VERSION ""

NS_ :

BS_:

BU_: HSCU BCM RINE BRUSA DCDC HVAC DECM BCM_HS HCSU ACCM_HS VICM_HS
VAL_TABLE_ NH3_Heater_Status 4 "Fault" 3 "Prewarm" 2 "On" 1 "Warm_Up" 0 "Off" ;
VAL_TABLE_ DebugRequest 16 "ADC Channel 0010'" 15 "ADC Channel 00F'" 14 "ADC Channel 00E'" 13 "ADC Channel 00D'" 12 "ADC Channel 00C'" 11 "ADC Channel 00B'" 10 "ADC Channel 00A'" 9 "ADC Channel 009'" 8 "ADC Channel 008'" 7 "ADC Channel 007'" 6 "ADC Channel 006'" 5 "ADC Channel 005'" 4 "ADC Channel 004'" 3 "ADC Channel 003'" 2 "ADC Channel 002'" 1 "ADC Channel 001'" 0 "ADC Channel 000'" ;
VAL_TABLE_ u13_error_no_value 8191 "ERROR" 8190 "NO_VALUE" ;
VAL_TABLE_ u10_error_no_value 1023 "ERROR" 1022 "NO_VALUE" ;
VAL_TABLE_ mainc_step 12 "MAIN_P_CLOSED_CHARGE" 11 "MAIN_PN_CLOSED_DRIVE" 10 "FAILED_MAINP_OPEN" 9 "OPEN_MAINR" 8 "CLOSE_MAINP" 7 "WAIT_PRECHARGE" 6 "FAILED_MAINN_OPEN" 5 "CLOSE_MAINN" 4 "FAILED_MAINN_WELD" 3 "FAILED_MAINR_OPEN" 2 "CLOSE_MAINR" 1 "FAILED_MAINP_OR_R_WELD" 0 "ALL_OPEN" ;
VAL_TABLE_ pump_stat 3 "FAILED_HIGH" 2 "FAILED_LOW" 1 "ON" 0 "OFF" ;
VAL_TABLE_ alarm_enum 3 "TYPE3" 2 "TYPE2" 1 "TYPE1" 0 "NONE" ;
VAL_TABLE_ contactor_enum 2 "FAILURE" 1 "CLOSED" 0 "OPEN" ;
VAL_TABLE_ u12_error_no_value 4095 "ERROR" 4094 "NO_VALUE" ;
VAL_TABLE_ u16_error_no_value 65534 "NO_VALUE" 65535 "ERROR" ;
VAL_TABLE_ u16_error 65535 "ERROR" ;
VAL_TABLE_ u8_error_no_value 255 "ERROR" 254 "NO_VALUE" ;
VAL_TABLE_ u8_error 255 "ERROR" ;
VAL_TABLE_ RtmControlState 0 "RtmOffline" 1 "RtmStartup" 2 "RtmRunning" 3 "RtmShutdown_SetDischarge" 4 "RtmShutdown_DischargeActive" 5 "RtmShutdown_DischargeComplete" 6 "RtmShutdown_ShutdownFault" 7 "RtmClearCodes" ;
VAL_TABLE_ BmsControlState 0 "BmsOffline" 1 "BmsStartup" 2 "BmsCloseContactors" 3 "BmsOnline" 4 "BmsShutdown" ;
VAL_TABLE_ mVec2ControlState 0 "mVec2ControllersOff" 1 "mVec2PowerModeOn" 2 "mVec2VehicleReadyOn" 3 "mVec2RineKeepOn" 4 "mVec2ChargerOn_NotCharging" 5 "mVec2ChargerOn_Charging" 6 "mVec2ChargerOn_Error" 7 "mVec2ChargerOn_FinishedCharging" 8 "mVec2HVIL" ;
VAL_TABLE_ mVecControlState 0 "mVec1ControllersOff" 1 "mVec1PowerModeOn" 2 "mVec1VehicleReadyOn" 3 "mVec1RineKeepOn" 4 "mVec1ChargerOn" 5 "mVec1HVIL" ;
VAL_TABLE_ TransmissionOverrideState 0 "Follow_Lever" 1 "Transition_to_Neutral" 2 "Forced_Neutral" 3 "Transition_to_Lever" ;
VAL_TABLE_ IceControlState 0 "IceOff" 1 "IceStartup" 2 "IceCrank_CrankOn" 3 "IceCrank_KeepCranking" 4 "IceCrank_CheckCrank" 5 "IceCrank_CrankComplete" 6 "IceCrank_CrankFail" 7 "IceIdle" 8 "IceEngaged" 9 "IceShutdown" 10 "IceRestartDelay" ;
VAL_TABLE_ VehicleMode 0 "PowertrainOff" 1 "RegenBraking" 2 "MixedBraking" 3 "HydraulicBraking" 4 "RtmOnly" 5 "Hybrid" 6 "IceOnly" 7 "Performance" 8 "LoadShifting" 9 "WaitForStartup" 10 "VehicleShuttingDown" 11 "OnCharger" 12 "ParkAndBrake" 13 "WaitForCrank" 14 "VehicleReady" 15 "PowertrainOff_No_Ice" 16 "PowertrainOff_StartIce" 17 "PowertrainOff_EngineIdle" 18 "PowertrainOff_EngineRevAllowed" 19 "IceOnly_EngageTransmission" 20 "IceOnly_StartEngine" 21 "RtmOnly_CheckEngine" 22 "RtmOnly_StartEngine" 23 "RtmOnly_RunningCoolant" 24 "RtmOnly_NoCoolant" ;

BO_ 3221225472 VECTOR__INDEPENDENT_SIG_MSG: 0 Vector__XXX
 SG_ HybContClrLgsDiag : 0|1@0+ (1,0) [0|1] "" Vector__XXX
 SG_ PrplsnSysAtv : 0|1@0+ (1,0) [0|1] "" Vector__XXX
 SG_ DgnInf : 0|64@0+ (1,0) [0|1.844674407371E+019] "" Vector__XXX
 SG_ PrplsnSysAtv : 0|1@0+ (1,0) [0|1] "" Vector__XXX
 SG_ PTShftLvrLckRqd : 0|1@0+ (1,0) [0|1] "" Vector__XXX
 SG_ DslExNxEmWrngIndRq : 0|4@0+ (1,0) [0|15] "" Vector__XXX
 SG_ DEFWVSL_S3SpdLmt : 0|8@0+ (1,0) [0|255] "km / h" Vector__XXX
 SG_ DEFWVSL_S2SpdLmt : 0|8@0+ (1,0) [0|255] "km / h" Vector__XXX
 SG_ DEFWVSL_S1SpdLmt : 0|8@0+ (1,0) [0|255] "km / h" Vector__XXX
 SG_ DslExFldTpWrngIndRq : 0|4@0+ (1,0) [0|15] "" Vector__XXX
 SG_ DslExhFldQlyWrngIReq : 0|4@0+ (1,0) [0|15] "" Vector__XXX
 SG_ DslExhFldWrngIdRqER : 0|4@0+ (1,0) [0|15] "" Vector__XXX
 SG_ DslExFldCnWrngIndRq : 0|4@0+ (1,0) [0|15] "" Vector__XXX
 SG_ DslExhFldDiagWrnIdRq : 0|3@0+ (1,0) [0|7] "" Vector__XXX
 SG_ DslEmnsOBDMrkt : 0|2@0+ (1,0) [0|3] "" Vector__XXX
 SG_ AlternativeFuelRichTrimLimitOff : 0|6@0- (0.01,0) [-0.32|0.31] "" Vector__XXX
 SG_ AlternativeFuelPostO2BiasOff : 0|8@0- (4,0) [-512|508] "mV" Vector__XXX
 SG_ AlternativeFuelLeanTrimLimitOff : 0|6@0- (0.01,0) [-0.32|0.31] "" Vector__XXX
 SG_ AlternativeFuelInjOpenOff : 0|8@0- (0.0313725490196078,0) [-4.01568|3.98431] "ms" Vector__XXX
 SG_ AlternativeFuelInjMinPulseOff : 0|8@0- (0.0313725490196078,0) [-4.01568|3.98431] "ms" Vector__XXX
 SG_ AlternativeFuelInjFlowOff : 0|8@1- (0.0313725490196078,0) [-4.01568|3.98431] "g/sec" Vector__XXX
 SG_ AlternativeFuelEquvRatBiasOff : 0|8@1- (0.1,0) [-0.0501961|0.0498039] "Eq Rat" Vector__XXX
 SG_ PgVehTheftDetNonImVirtDevAva : 0|1@0+ (1,0) [0|0] "" Vector__XXX
 SG_ PgTractionControlSysPresent : 0|1@0+ (1,0) [0|0] "" Vector__XXX
 SG_ PgThrottleProgReq : 0|2@0+ (1,0) [0|0] "" Vector__XXX
 SG_ PgSystemPowerMode : 0|2@0+ (1,0) [0|0] "" Vector__XXX
 SG_ PgSysBackupPowerModeEnabled : 0|1@0+ (1,0) [0|0] "" Vector__XXX
 SG_ PgSysBackupPowerMode : 0|2@0+ (1,0) [0|0] "" Vector__XXX
 SG_ PgRemVehStartReq : 0|1@0+ (1,0) [0|0] "" Vector__XXX
 SG_ PgrealTimeDampSysPresent : 0|1@0+ (1,0) [0|0] "" Vector__XXX
 SG_ PgPowerModeMstrRunCrankTermStat : 0|1@0+ (1,0) [0|0] "" Vector__XXX
 SG_ PgPowerModeMstrAccTermStatus : 0|1@0+ (1,0) [0|0] "" Vector__XXX
 SG_ PgParkBrakeVirtDevAva : 0|1@0+ (1,0) [0|0] "" Vector__XXX
 SG_ PgParkBrakeSwAct : 0|1@0+ (1,0) [0|0] "" Vector__XXX
 SG_ PgOutAirTempVirtDevAva : 0|1@0+ (1,0) [0|0] "" Vector__XXX
 SG_ PgManTransrevGearActV : 0|1@0+ (1,0) [0|0] "" Vector__XXX
 SG_ PgManTransRevGearAct : 0|1@0+ (1,0) [0|0] "" Vector__XXX
 SG_ PgManTranRevGearSwVDevAv : 0|1@0+ (1,0) [0|0] "" Vector__XXX
 SG_ PgEngOilLifeResetReq : 0|1@0+ (1,0) [0|0] "" Vector__XXX
 SG_ PgEngCoolLevSwVirtDevAva : 0|1@0+ (1,0) [0|0] "" Vector__XXX
 SG_ PgEngCoolLevLow : 0|1@0+ (1,0) [0|0] "" Vector__XXX
 SG_ PgEngCoolFanSpdAdjust : 0|8@0- (0.78125,0) [-100|99.2188] "%" Vector__XXX
 SG_ PgEnergyMngmtMinIdleBoostLevReq : 0|3@0+ (1,0) [0|0] "" Vector__XXX
 SG_ PgCruiseContSwProtValue : 0|4@0+ (1,0) [0|15] "" Vector__XXX
 SG_ PgCruiseControlSwFail : 0|1@0+ (1,0) [0|0] "" Vector__XXX
 SG_ PgCruiseControlSetSwAct : 0|1@0+ (1,0) [0|0] "" Vector__XXX
 SG_ PgCruiseControlResSwAct : 0|1@0+ (1,0) [0|0] "" Vector__XXX
 SG_ PgCruiseControlOnSwAct : 0|1@0+ (1,0) [0|0] "" Vector__XXX
 SG_ PgCruiseControlCancelReq : 0|1@0+ (1,0) [0|0] "" Vector__XXX
 SG_ PgCruiseContAliveRC : 0|2@0+ (1,0) [0|3] "" Vector__XXX
 SG_ PgClimateContVirtDevAva : 0|1@0+ (1,0) [0|0] "" Vector__XXX
 SG_ PgBackupPowerModeMstrVirtDevAva : 0|1@0+ (1,0) [0|0] "" Vector__XXX
 SG_ PgAntilockBrakeSysPresent : 0|1@0+ (1,0) [0|0] "" Vector__XXX
 SG_ PgAirCondCompPresent : 0|1@0+ (1,0) [0|0] "" Vector__XXX
 SG_ PgAirCondCompClutchReq : 0|2@0+ (1,0) [0|0] "" Vector__XXX
 SG_ PgAirbagVirtDevAva : 0|1@0+ (1,0) [0|0] "" Vector__XXX
 SG_ PgAirbagDep : 0|1@0+ (1,0) [0|0] "" Vector__XXX
 SG_ VehicleStabEnhanceSysSpdLimAct : 0|1@0+ (1,0) [0|0] "" Vector__XXX
 SG_ TractionControlSysFailed : 0|1@0+ (1,0) [0|0] "" Vector__XXX
 SG_ BrakePedalDriveAppPresDet : 0|1@0+ (1,0) [0|0] "" Vector__XXX
 SG_ BrakePedalDrivAppPresDetV : 0|1@0+ (1,0) [0|0] "" Vector__XXX
 SG_ SuspensionSysDampFailFullSoft : 0|1@0+ (1,0) [0|0] "" Vector__XXX
 SG_ VehicleDynamicControlActive : 0|1@0+ (1,0) [0|0] "" Vector__XXX
 SG_ TractionCntrlSysEnable : 0|1@0+ (1,0) [0|0] "" Vector__XXX
 SG_ TractionCntrlSysActive : 0|1@0+ (1,0) [0|0] "" Vector__XXX
 SG_ AntilockBrakeSysFailed : 0|1@0+ (1,0) [0|0] "" Vector__XXX
 SG_ AntilockBrakeSysActive : 0|1@0+ (1,0) [0|0] "" Vector__XXX
 SG_ WheelSpeedSensDiagComplete : 0|1@0+ (1,0) [0|0] "" Vector__XXX
 SG_ WheelAvgP2PAccelV : 0|1@0+ (1,0) [0|0] "" Vector__XXX
 SG_ WheelAvgP2PAccel : 0|8@0+ (0.00392156862745098,0) [0|1] "g's" Vector__XXX
 SG_ TractionTrqDecayCtrlActive : 0|1@0+ (1,0) [0|0] "" Vector__XXX
 SG_ WheelAngVelocityRearRightV : 0|1@0+ (1,0) [0|0] "" Vector__XXX
 SG_ WheelAngVelocityRearRight : 0|15@0- (0.25,0) [-4096|4095.75] "RPM" Vector__XXX
 SG_ WheelAngVelocityRearLeftV : 0|1@0+ (1,0) [0|0] "" Vector__XXX
 SG_ WheelAngVelocityRearLeft : 0|15@0- (0.25,0) [-4096|4095.75] "RPM" Vector__XXX
 SG_ WheelAngVelocityFrontRightV : 0|1@0+ (1,0) [0|0] "" Vector__XXX
 SG_ WheelAngVelocityFrontRight : 0|15@0+ (0.25,0) [-4096|4095.75] "RPM" Vector__XXX
 SG_ WheelAngVelocityFrontLeftV : 0|1@0+ (1,0) [0|0] "" Vector__XXX
 SG_ WheelAngVelocityFrontLeft : 0|15@0- (0.25,0) [-4096|4095.75] "RPM" Vector__XXX
 SG_ SteeringWheelAngleV : 0|1@0+ (1,0) [0|0] "" Vector__XXX
 SG_ SteeringWheelAngleGradV : 0|1@0+ (1,0) [0|0] "" Vector__XXX
 SG_ SteeringWheelAngleGrad : 0|12@0+ (1,0) [-2048|2047] "deg/s" Vector__XXX
 SG_ SteeringWheelAngle : 0|16@0+ (0.0625,0) [-2048|2047.94] "deg" Vector__XXX
 SG_ VehicleDynLateralAccV : 0|1@0+ (1,0) [0|0] "" Vector__XXX
 SG_ VehicleDynLateralAcc : 0|12@0- (0.015625,0) [-32|31.9844] "" Vector__XXX
 SG_ TractionTrqDecayGrad : 0|10@0+ (1.5,0) [0|1.5] "%/ms" Vector__XXX
 SG_ TractionTrqDecayEnable : 0|1@0+ (1,0) [0|0] "" Vector__XXX
 SG_ TractionControlTrqReqV : 0|1@0+ (1,0) [0|0] "" Vector__XXX
 SG_ TractionControlTrqReq : 0|16@0+ (1,0) [0|65535] "" Vector__XXX
 SG_ TractionControlAliveRollCount : 0|2@0+ (1,0) [0|3] "" Vector__XXX
 SG_ TorqueRequestValue : 0|12@0+ (0.25,-200) [-200|823.75] "Nm" Vector__XXX
 SG_ TorqueReductionRealizSuggestion : 0|2@0+ (1,0) [0|0] "" Vector__XXX
 SG_ TorqueInterventionType : 0|2@0+ (1,0) [0|0] "" Vector__XXX
 SG_ BrakePedalPosRollCount : 0|2@0+ (1,0) [0|3] "" Vector__XXX
 SG_ BrakePedalPosFailure : 0|1@0+ (1,0) [0|0] "" Vector__XXX
 SG_ BrakePedalModerateTravelAch : 0|1@0+ (1,0) [0|0] "" Vector__XXX
 SG_ BrakePedalInitTravelAchProt : 0|2@0+ (1,0) [0|3] "" Vector__XXX
 SG_ BrakePedalInitTravelAch : 0|1@0+ (1,0) [0|0] "" Vector__XXX
 SG_ VehicleLiftDiveStatusV : 0|1@0+ (1,0) [0|0] "" Vector__XXX
 SG_ VehicleLiftDiveStatus : 0|2@0+ (1,0) [0|0] "" Vector__XXX
 SG_ EngineTrqTractContReqFail : 0|1@0+ (1,0) [0|0] "" Vector__XXX
 SG_ EngineTorqueReductFailStat : 0|3@0+ (1,0) [0|0] "" Vector__XXX
 SG_ EngineTorqueMinV : 0|1@0+ (1,0) [0|0] "" Vector__XXX
 SG_ EngineTorqueMin : 0|12@0+ (0.25,-200) [-200|823.75] "Nm" Vector__XXX
 SG_ EngineTorqueMaxV : 0|1@0+ (1,0) [0|0] "" Vector__XXX
 SG_ EngineTorqueMax : 0|12@0+ (0.25,-200) [-200|823.75] "Nm" Vector__XXX
 SG_ EngineTorqueDriverReqV : 0|1@0+ (1,0) [0|0] "" Vector__XXX
 SG_ EngineTorqueDriverReq : 0|12@0+ (0.25,-200) [-200|823.75] "Nm" Vector__XXX
 SG_ EngineTorqueActualV : 0|1@0+ (1,0) [0|0] "" Vector__XXX
 SG_ EngineTorqueActual : 0|12@0+ (0.25,-200) [-200|823.75] "Nm" Vector__XXX
 SG_ AcceleratorActualPosV : 0|1@0+ (1,0) [0|0] "" Vector__XXX
 SG_ EngineSpeed : 0|16@0+ (0.25,0) [0|16383.75] "RPM" Vector__XXX
 SG_ CruiseControlActive : 0|1@0+ (1,0) [0|0] "" Vector__XXX
 SG_ ThrottlePosV : 0|1@0+ (1,0) [0|0] "" Vector__XXX
 SG_ ThrottlePos : 0|8@0+ (0.392156862745098,0) [0|100] "%" Vector__XXX
 SG_ AcceleratorEffectivePosV : 0|1@0+ (1,0) [0|0] "" Vector__XXX
 SG_ AcceleratorEffectivePos : 0|8@0+ (0.392156862745098,0) [0|100] "%" Vector__XXX
 SG_ AcceleratorActualPos : 0|8@0+ (0.392156862745098,0) [0|100] "%" Vector__XXX
 SG_ EngineSpeedV : 0|1@0+ (1,0) [0|0] "" Vector__XXX
 SG_ UW_Time : 0|64@1+ (1,0) [0|0] "s" Vector__XXX
 SG_ New_Signal_1256 : 0|8@1+ (1,0) [0|0] "" Vector__XXX
 SG_ New_Signal_1255 : 0|8@1+ (1,0) [0|0] "" Vector__XXX
 SG_ New_Signal_1254 : 0|8@1+ (1,0) [0|0] "" Vector__XXX
 SG_ rtmTqrTarget : 0|16@0- (0.0001,0) [-3.2768|3.2767] "" Vector__XXX
 SG_ Sensor_Temp_Fault : 0|1@1+ (1,0) [0|1] "" Vector__XXX
 SG_ Sensor_Internal_Fault : 0|1@1+ (1,0) [0|1] "" Vector__XXX
 SG_ Sensor_at_Temp : 0|1@1+ (1,0) [0|1] "" Vector__XXX
 SG_ Sensor_3_out_fault_Placeholder : 0|1@1+ (1,0) [0|1] "" Vector__XXX
 SG_ Sensor_2_Out_Fault : 0|1@1+ (1,0) [0|1] "" Vector__XXX
 SG_ Sensor_1_Out_Fault : 0|1@1+ (1,0) [0|1] "" Vector__XXX
 SG_ NH3_Trim_Fault : 0|1@1+ (1,0) [0|1] "" Vector__XXX

BO_ 68 K_VEH_CAN_TX_MSG4_ID: 8 Vector__XXX
 SG_ Sensor_tem_out_of_control_timer : 56|8@1+ (1,0) [0|0] "sec" Vector__XXX
 SG_ Heater_warm_up_timer : 48|8@1+ (1,0) [0|0] "sec" Vector__XXX
 SG_ Heater_Limited_Voltage : 32|16@1- (0.001,0) [0|0] "V" Vector__XXX
 SG_ Heater_Duty_Cycle : 16|16@1- (0.01,0) [0|0] "%" Vector__XXX
 SG_ Battery_Voltage : 0|16@1+ (0.01,0) [0|655.35] "V" Vector__XXX

BO_ 67 K_VEH_CAN_TX_MSG3_ID: 8 Vector__XXX
 SG_ NH3_Zcell : 48|16@1- (0.1,0) [0|0] "Ohm" Vector__XXX
 SG_ Sensor_3_Out_placeholder : 32|16@1- (1,0) [0|0] "mV" Vector__XXX
 SG_ Sensor_2_Out : 16|16@1- (1,0) [0|0] "mV" Vector__XXX
 SG_ Sensor_1_Out : 0|16@1- (1,0) [0|0] "mV" Vector__XXX

BO_ 66 K_VEH_CAN_TX_MSG2_ID: 8 Vector__XXX
 SG_ Heater_Warm_Up_too_Long_Fault : 8|1@1+ (1,0) [0|1] "" Vector__XXX
 SG_ Heater_Supply_Low_Fault : 7|1@1+ (1,0) [0|1] "" Vector__XXX

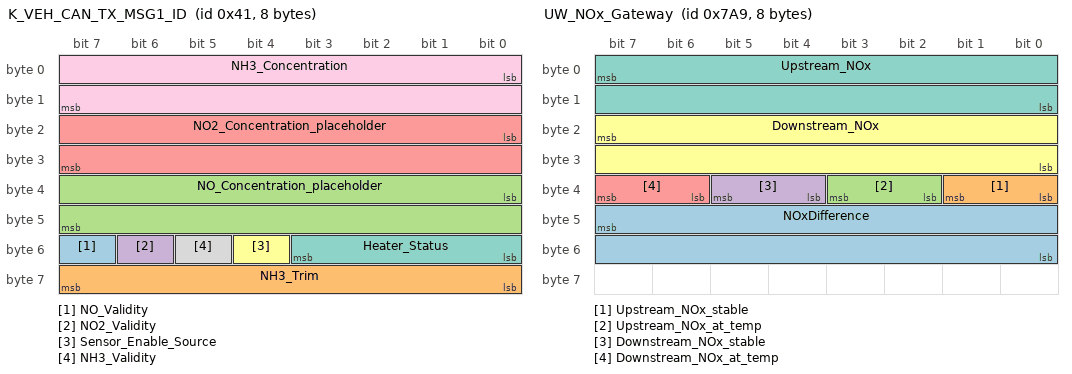
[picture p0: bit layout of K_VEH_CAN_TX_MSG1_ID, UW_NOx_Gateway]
BO_ 65 K_VEH_CAN_TX_MSG1_ID: 8 Vector__XXX
 SG_ NO_Validity : 55|1@1+ (1,0) [0|0] "" Vector__XXX
 SG_ NH3_Trim : 56|8@1+ (0.01,0) [0|2.55] "" Vector__XXX
 SG_ NO_Concentration_placeholder : 32|16@1+ (0.1,0) [0|6553.5] "ppm" Vector__XXX
 SG_ NO2_Validity : 54|1@1+ (1,0) [0|1] "" Vector__XXX
 SG_ NO2_Concentration_placeholder : 16|16@1+ (0.1,0) [0|6553.5] "ppm" Vector__XXX
 SG_ Sensor_Enable_Source : 52|1@1+ (1,0) [0|1] "" Vector__XXX
 SG_ Heater_Status : 48|4@1+ (1,0) [0|15] "" Vector__XXX
 SG_ NH3_Validity : 53|1@1+ (1,0) [0|1] "" Vector__XXX
 SG_ NH3_Concentration : 0|16@1+ (0.1,0) [0|6553.5] "ppm" Vector__XXX

BO_ 146 K_VEH_CAN_RX_MSG2_ID: 8 Vector__XXX
 SG_ Ammoniabyte6 : 48|8@1+ (1,0) [0|0] "" Vector__XXX
 SG_ AmmoniaByte5 : 40|8@1+ (1,0) [0|0] "" Vector__XXX
 SG_ AmmoniaByte4 : 32|8@1+ (1,0) [0|0] "" Vector__XXX
 SG_ AmmoniaByte3 : 24|8@1+ (1,0) [0|0] "" Vector__XXX
 SG_ Update_NonVolatile_Memory : 56|8@1+ (1,0) [0|255] "" Vector__XXX
 SG_ Clear_Diagnostic_Fault : 16|8@1+ (1,0) [0|255] "" Vector__XXX
 SG_ Prewarm_Enable : 8|8@1+ (1,0) [0|255] "" Vector__XXX
 SG_ Dew_Point_Status : 0|8@1+ (1,0) [0|255] "" Vector__XXX

BO_ 1962 UW_Controller_Values: 8 Vector__XXX
 SG_ NH3cumalitive : 39|16@0+ (0.1,0) [0|6553.5] "ppm*s" Vector__XXX
 SG_ NH3average : 23|16@0+ (0.01,0) [0|655.35] "ppm" Vector__XXX
 SG_ AtBMSbuffer : 2|1@0+ (1,0) [0|0] "" Vector__XXX
 SG_ EngineStopStartFlag : 3|1@0+ (1,0) [0|0] "" Vector__XXX
 SG_ targetSOC : 7|4@0+ (0.1,0) [0|0] "" Vector__XXX

BO_ 1961 UW_NOx_Gateway: 8 Vector__XXX
 SG_ NOxDifference : 47|16@0+ (0.05,-200) [-200|4000] "ppm" Vector__XXX
 SG_ Upstream_NOx_stable : 33|2@0+ (1,0) [0|0] "" Vector__XXX
 SG_ Upstream_NOx_at_temp : 35|2@0+ (1,0) [0|0] "" Vector__XXX
 SG_ Downstream_NOx_stable : 37|2@0+ (1,0) [0|0] "" Vector__XXX
 SG_ Downstream_NOx_at_temp : 39|2@0+ (1,0) [0|0] "" Vector__XXX
 SG_ Downstream_NOx : 23|16@0+ (0.05,-200) [-200|4000] "ppm" Vector__XXX
 SG_ Upstream_NOx : 7|16@0+ (0.05,-200) [-200|4000] "ppm" Vector__XXX

BO_ 1952 CenterStackCommands: 8 Vector__XXX
 SG_ HVAC_on_command : 0|1@0+ (1,0) [0|1] "bool" Vector__XXX

BO_ 566 VICM_Status_HS: 4 VICM_HS
 SG_ ClimCtrlHVDvcShtdwnCmd : 23|1@0+ (1,0) [0|1] ""  ACCM_HS
 SG_ VICntlModRunCrkTrmSt : 21|1@0+ (1,0) [0|1] ""  ACCM_HS
 SG_ VICMClrLgsDgInfo : 6|1@0+ (1,0) [0|1] ""  ACCM_HS
 SG_ ThrmlRefCompSpdReq : 5|14@0+ (1,0) [0|16383] "rpm"  ACCM_HS

BO_ 568 A_12V_System_Status_HS: 1 VICM_HS
 SG_ a_12VSysVlt : 7|8@0+ (0.125,0) [0|31.875] "volts"  ACCM_HS

BO_ 1960 UW_ControllerFactors: 8 Vector__XXX
 SG_ IceThrottleCommand : 55|16@0- (0.0001,0) [-3.2768|3.2767] "" Vector__XXX
 SG_ driverTrqRequest : 39|16@0- (0.0001,0) [0|0] "" Vector__XXX
 SG_ rtmTqrFactor : 23|16@0- (0.0001,0) [0|0] "" Vector__XXX
 SG_ iceTqrFactor : 7|16@0- (0.0001,0) [0|0] "" Vector__XXX

BO_ 472 Team_Created_Battery_Current: 8 Vector__XXX
 SG_ Team_Created_Battery_Current_Sig : 51|12@0- (0.3,0) [-614.4|614.1] "A" Vector__XXX

BO_ 983 Team_Created_Battery_Voltage: 8 Vector__XXX
 SG_ Team_Created_Battery_Voltage_Sig : 7|10@0+ (0.52,0) [0|0] "V" Vector__XXX

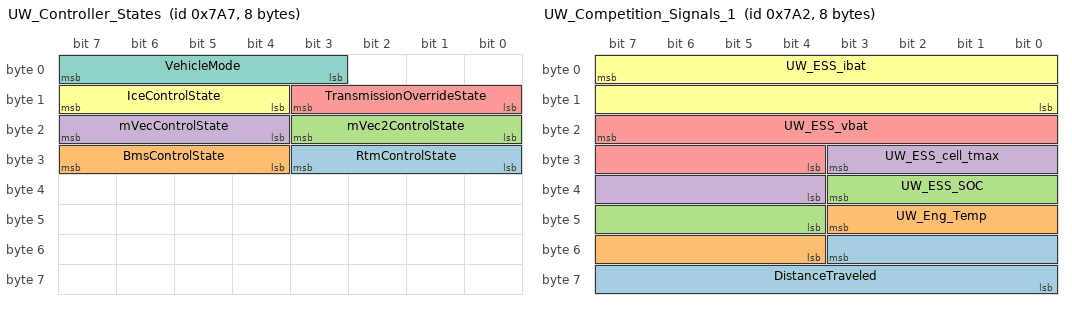
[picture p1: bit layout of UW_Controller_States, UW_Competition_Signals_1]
BO_ 1959 UW_Controller_States: 8 HCSU
 SG_ RtmControlState : 27|4@0+ (1,0) [0|0] "" Vector__XXX
 SG_ BmsControlState : 31|4@0+ (1,0) [0|0] "" Vector__XXX
 SG_ mVec2ControlState : 19|4@0+ (1,0) [0|0] "" Vector__XXX
 SG_ mVecControlState : 23|4@0+ (1,0) [0|0] "" Vector__XXX
 SG_ TransmissionOverrideState : 11|4@0+ (1,0) [0|0] "" Vector__XXX
 SG_ IceControlState : 15|4@0+ (1,0) [0|0] "" Vector__XXX
 SG_ VehicleMode : 7|5@0+ (1,0) [0|0] "" Vector__XXX

BO_ 1958 UW_Competition_Signals_5: 8 HSCU
 SG_ AverageMPG : 17|10@0+ (0.1,0) [0|102.3] "miles/gallon" Vector__XXX
 SG_ InstMPG : 11|10@0+ (0.1,0) [0|102.3] "miles/gallon" Vector__XXX
 SG_ Upstream_NOx : 39|16@0+ (0.05,-200) [-200|4000] "ppm" Vector__XXX
 SG_ Downstream_NOx : 55|16@0+ (0.05,-200) [-200|4000] "ppm" Vector__XXX
 SG_ InstFuelConsmpRate : 7|12@0+ (0.025,0) [0|102.375] "ltrs/hr" Vector__XXX

BO_ 1956 UW_Competition_Signals_3: 8 HSCU
 SG_ UW_Gear_Ratio : 55|8@0+ (0.03125,0) [0|7.96875] "" Vector__XXX
 SG_ UW_Commanded_Gear : 46|4@0+ (1,0) [0|15] "" Vector__XXX
 SG_ UW_Brake_On_Off : 47|1@0+ (1,0) [0|0] "" Vector__XXX
 SG_ UW_Accel_Pedal_Position : 39|8@0+ (0.392156862745098,0) [0|100] "%" Vector__XXX
 SG_ UW_Motor_Torque : 23|16@0- (0.1,0) [-3276.8|3276.7] "Nm" Vector__XXX
 SG_ UW_Motor_Speed : 7|16@0- (1,0) [-32768|32767] "rpm" Vector__XXX

BO_ 1957 UW_Competition_Signals_4: 8 HSCU
 SG_ iceEfficency : 55|8@0+ (0.01,0) [0|2.55] "factor" Vector__XXX
 SG_ rtmEfficency : 47|8@0+ (0.01,0) [0|2.55] "factor" Vector__XXX
 SG_ VehicleEfficencyScoreInst : 39|8@0+ (0.01,0) [0|2.55] "factor" Vector__XXX
 SG_ UW_BRUSA_AC_I : 23|16@0+ (0.01,0) [0|50] "A" Vector__XXX
 SG_ UW_BRUSA_AC_V : 7|16@0+ (0.1,0) [0|500] "V" Vector__XXX

BO_ 1955 UW_Competition_Signals_2: 8 HSCU
 SG_ UW_Engine_Torque : 55|12@0+ (0.5,-848) [-848|1199.5] "Nm" Vector__XXX
 SG_ UW_Engine_Speed : 39|16@0+ (0.25,0) [0|16383.75] "rpm" Vector__XXX
 SG_ UW_Vehicle_Speed : 23|15@0+ (0.015625,0) [0|511.984375] "km / h" Vector__XXX
 SG_ UW_Motor_Temperature : 7|16@0- (0.1,0) [-3276.8|3276.7] "degC" Vector__XXX

BO_ 1954 UW_Competition_Signals_1: 8 HSCU
 SG_ DistanceTraveled : 51|12@0+ (0.1,0) [0|0] "miles" Vector__XXX
 SG_ UW_Eng_Temp : 43|8@0+ (1,-40) [-40|215] "deg C" Vector__XXX
 SG_ UW_ESS_SOC : 35|8@0+ (0.5,0) [0|100] "%" Vector__XXX
 SG_ UW_ESS_cell_tmax : 27|8@0+ (0.5,-40) [-40|85] "DegC" Vector__XXX
 SG_ UW_ESS_vbat : 23|12@0+ (0.25,0) [0|1000] "volts" Vector__XXX
 SG_ UW_ESS_ibat : 7|16@0+ (0.025,-1000) [-1000|500] "amps" Vector__XXX

BO_ 1953 UW_Component_Diagnostics: 8 HSCU
 SG_ rtm_trq_match_force_zero : 40|1@0+ (1,0) [0|0] "" Vector__XXX
 SG_ rtm_trq_match_error : 41|1@0+ (1,0) [0|0] "" Vector__XXX
 SG_ rtm_tqr_match_disable : 42|1@0+ (1,0) [0|0] "" Vector__XXX
 SG_ MVEC_Two_Fuse_Status : 43|1@0+ (1,0) [0|0] "bool" Vector__XXX
 SG_ MVEC_One_Fuse_Status : 32|1@0+ (1,0) [0|0] "" Vector__XXX
 SG_ RINE_Discharge_Fault : 33|1@0+ (1,0) [0|1] ""  HSCU
 SG_ mVec2_8_Relay_State : 24|1@0+ (1,0) [0|0] ""  HSCU
 SG_ mVec2_7_Relay_State : 25|1@0+ (1,0) [0|0] ""  HSCU
 SG_ mVec2_6_Relay_State : 26|1@0+ (1,0) [0|0] ""  HSCU
 SG_ mVec2_5_Relay_State : 27|1@0+ (1,0) [0|0] ""  HSCU
 SG_ mVec2_4_Relay_State : 28|1@0+ (1,0) [0|0] ""  HSCU
 SG_ mVec2_3_Relay_State : 29|1@0+ (1,0) [0|0] ""  HSCU
 SG_ mVec2_2_Relay_State : 30|1@0+ (1,0) [0|0] ""  HSCU
 SG_ mVec2_1_Relay_State : 31|1@0+ (1,0) [0|0] ""  HSCU
 SG_ mVec1_8_Relay_State : 16|1@0+ (1,0) [0|0] ""  HSCU
 SG_ mVec1_7_Relay_State : 17|1@0+ (1,0) [0|0] ""  HSCU
 SG_ mVec1_6_Relay_State : 18|1@0+ (1,0) [0|0] ""  HSCU
 SG_ mVec1_5_Relay_State : 19|1@0+ (1,0) [0|0] ""  HSCU
 SG_ mVec1_4_Relay_State : 20|1@0+ (1,0) [0|0] ""  HSCU
 SG_ mVec1_3_Relay_State : 21|1@0+ (1,0) [0|0] ""  HSCU
 SG_ mVec1_2_Relay_State : 22|1@0+ (1,0) [0|0] ""  HSCU
 SG_ mVec1_1_Relay_State : 23|1@0+ (1,0) [0|0] ""  HSCU
 SG_ DECM_Diagnostics : 39|2@0+ (1,0) [0|0] ""  HSCU
 SG_ TCM_Diagnostics : 13|2@0+ (1,0) [0|3] ""  HSCU
 SG_ EMIS_Diagnostics : 15|2@0+ (1,0) [0|0] ""  HSCU
 SG_ BRUSA_Diagnostics : 1|2@0+ (1,0) [0|0] ""  HSCU
 SG_ EMP_Diagnostics : 3|2@0+ (1,0) [0|0] ""  HSCU
 SG_ DCDC_Diagnostics : 5|2@0+ (1,0) [0|0] ""  HSCU
 SG_ Driver_Input_Diagnostics : 9|2@0+ (1,0) [0|3] ""  HSCU
 SG_ RINE_Operating_Status : 37|4@0+ (1,0) [0|0] ""  HSCU
 SG_ RINE_Diagnostics : 11|2@0+ (1,0) [0|0] ""  HSCU
 SG_ BMS_Operating_Status : 47|4@0+ (1,0) [0|0] ""  HSCU
 SG_ BMS_Diagnostics : 7|2@0+ (1,0) [0|0] ""  HSCU

BO_ 1223 PPEI_Propulsion_Sys_Gen_Status: 3 DECM
 SG_ EngSnPwrECoolLpTmpV : 6|1@0+ (1,0) [0|1] ""  HSCU
 SG_ EngSnPwrECoolLpTmp : 23|8@0+ (1,-40) [-40|215] "deg C"  HSCU
 SG_ PropSysOffTmeV : 5|1@0+ (1,0) [0|1] ""  HSCU
 SG_ PropSysOffTmeM : 4|1@0+ (1,0) [0|1] ""  HSCU
 SG_ PropSysOffTme : 3|12@0+ (0.5,0) [0|2047.5] "min"  HSCU

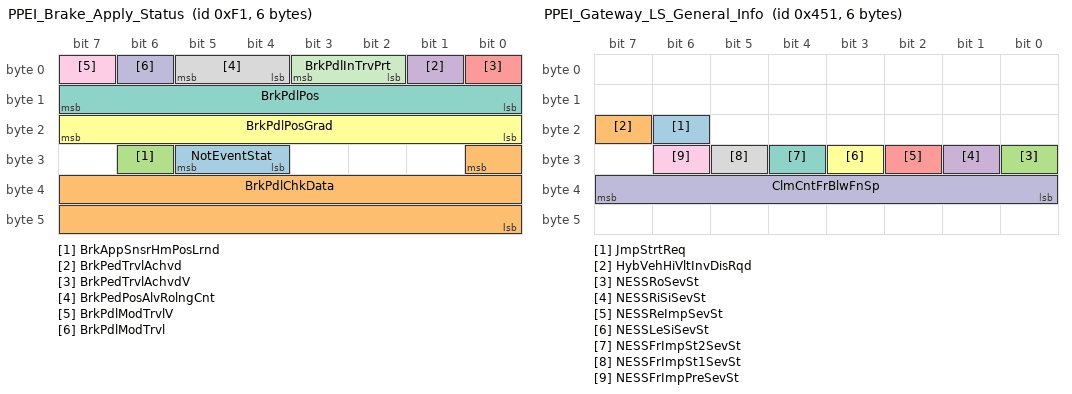
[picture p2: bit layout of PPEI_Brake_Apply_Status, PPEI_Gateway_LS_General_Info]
BO_ 241 PPEI_Brake_Apply_Status: 6 HSCU
 SG_ NotEventStat : 29|2@0+ (1,0) [0|0] ""  DECM
 SG_ BrkPdlChkData : 24|17@0+ (1,0) [0|131071] ""  DECM
 SG_ BrkAppSnsrHmPosLrnd : 30|1@0+ (1,0) [0|1] ""  DECM
 SG_ BrkPedTrvlAchvd : 1|1@0+ (1,0) [0|1] ""  DECM
 SG_ BrkPedTrvlAchvdV : 0|1@0+ (1,0) [0|1] ""  DECM
 SG_ BrkPdlPosGrad : 23|8@0- (40,0) [-5120|5080] "%/s"  DECM
 SG_ BrkPdlPos : 15|8@0+ (0.392157,0) [0|100.000035] "% full"  DECM
 SG_ BrkPedPosAlvRolngCnt : 5|2@0+ (1,0) [0|3] ""  DECM
 SG_ BrkPdlModTrvlV : 7|1@0+ (1,0) [0|1] ""  DECM
 SG_ BrkPdlModTrvl : 6|1@0+ (1,0) [0|1] ""  DECM
 SG_ BrkPdlInTrvPrt : 3|2@0+ (1,0) [0|3] ""  DECM

BO_ 1005 Vehicle_Limit_Speed_Control_Cmd: 6 HSCU
 SG_ EnhSvVehTopSpdLmR : 7|2@0+ (1,0) [0|3] ""  DECM
 SG_ EnhSvVTpSpdLVlARC : 5|2@0+ (1,0) [0|3] ""  DECM
 SG_ EnhSvVehTopSpdLimP : 15|32@0+ (1,0) [0|4294967295] ""  DECM
 SG_ EnhSvVehTopSpdLim : 47|8@0+ (2,0) [0|510] "km / h"  DECM

BO_ 1105 PPEI_Gateway_LS_General_Info: 6 HSCU
 SG_ JmpStrtReq : 22|1@0+ (1,0) [0|1] ""  DECM
 SG_ HybVehHiVltInvDisRqd : 23|1@0+ (1,0) [0|1] ""  DECM
 SG_ NESSRoSevSt : 24|1@0+ (1,0) [0|1] ""  DECM
 SG_ NESSRiSiSevSt : 25|1@0+ (1,0) [0|1] ""  DECM
 SG_ NESSReImpSevSt : 26|1@0+ (1,0) [0|1] ""  DECM
 SG_ NESSLeSiSevSt : 27|1@0+ (1,0) [0|1] ""  DECM
 SG_ NESSFrImpSt2SevSt : 28|1@0+ (1,0) [0|1] ""  DECM
 SG_ NESSFrImpSt1SevSt : 29|1@0+ (1,0) [0|1] ""  DECM
 SG_ NESSFrImpPreSevSt : 30|1@0+ (1,0) [0|1] ""  DECM
 SG_ ClmCntFrBlwFnSp : 39|8@0+ (0.392157,0) [0|100.000035] "%"  DECM

BO_ 419 PTEI_Engine_Common_Use_1: 1 DECM
 SG_ EngRunng : 7|1@0+ (1,0) [0|1] ""  HSCU

BO_ 1249 PPEI_VIN_Digits_10_to_17: 8 HSCU
 SG_ VehIdNmDig10_17 : 7|64@0+ (1,0) [0|1] ""  DECM

BO_ 1221 PPEI_Platform_Eng_Cntrl_Req_2: 3 HSCU
 SG_ CCClntCrcFlwRtReq : 23|8@0+ (0.392157,0) [0|100.000035] "%"  DECM
 SG_ PFFanSpdPrcntRq : 15|8@0+ (0.392157,0) [0|100.000035] "%"  DECM

BO_ 1906 DTC_Triggered_772: 7 DECM
 SG_ DTCI_DTCFaultType_772 : 55|8@0+ (1,0) [0|255] ""  HSCU
 SG_ DTCI_CodeSupported_772 : 40|1@0+ (1,0) [0|1] ""  HSCU
 SG_ DTCI_CurrentStatus_772 : 41|1@0+ (1,0) [0|1] ""  HSCU
 SG_ DTCI_TstNPsdCdClrdSt_772 : 42|1@0+ (1,0) [0|1] ""  HSCU
 SG_ DTCI_TstFldCdClrdStat_772 : 43|1@0+ (1,0) [0|1] ""  HSCU
 SG_ DTCI_HistStat_772 : 44|1@0+ (1,0) [0|1] ""  HSCU
 SG_ DTCI_TstNPsdPwrUpSt_772 : 45|1@0+ (1,0) [0|1] ""  HSCU
 SG_ DTCI_TstFldPwrUpSt_772 : 46|1@0+ (1,0) [0|1] ""  HSCU
 SG_ DTCI_WrnIndRqdSt_772 : 47|1@0+ (1,0) [0|1] ""  HSCU
 SG_ DTCI_DTCFailType_772 : 39|8@0+ (1,0) [0|255] ""  HSCU
 SG_ DTCI_DTCNumber_772 : 23|16@0+ (1,0) [0|65535] ""  HSCU
 SG_ DTCI_DTCSource_772 : 15|8@0+ (1,0) [0|255] ""  HSCU
 SG_ DTCI_DTCTriggered_772 : 0|1@0+ (1,0) [0|1] ""  HSCU
 SG_ DTCIUnused7_772 : 1|1@0+ (1,0) [0|1] ""  HSCU
 SG_ DTCIUnused6_772 : 2|1@0+ (1,0) [0|1] ""  HSCU
 SG_ DTCIUnused5_772 : 3|1@0+ (1,0) [0|1] ""  HSCU
 SG_ DTCIUnused4_772 : 4|1@0+ (1,0) [0|1] ""  HSCU
 SG_ DTCIUnused3_772 : 5|1@0+ (1,0) [0|1] ""  HSCU
 SG_ DTCIUnused2_772 : 6|1@0+ (1,0) [0|1] ""  HSCU
 SG_ DTCIUnused1_772 : 7|1@0+ (1,0) [0|1] ""  HSCU

BO_ 500 PPEI_Drv_Pref_Mode_Switch_Status: 6 DECM
 SG_ DrvSelMd8Stat : 17|1@0+ (1,0) [0|1] ""  HSCU
 SG_ DrvSelMd8ReqDnd : 16|1@0+ (1,0) [0|1] ""  HSCU
 SG_ DrvSelMd7Stat : 19|1@0+ (1,0) [0|1] ""  HSCU
 SG_ DrvSelMd7ReqDnd : 18|1@0+ (1,0) [0|1] ""  HSCU
 SG_ DrvSelMd6Stat : 21|1@0+ (1,0) [0|1] ""  HSCU
 SG_ DrvSelMd6ReqDnd : 20|1@0+ (1,0) [0|1] ""  HSCU
 SG_ DrvSelMd5Stat : 23|1@0+ (1,0) [0|1] ""  HSCU
 SG_ DrvSelMd5ReqDnd : 22|1@0+ (1,0) [0|1] ""  HSCU
 SG_ DrvSelMd4Stat : 9|1@0+ (1,0) [0|1] ""  HSCU
 SG_ DrvSelMd4ReqDnd : 8|1@0+ (1,0) [0|1] ""  HSCU
 SG_ DrvSelMd3Stat : 11|1@0+ (1,0) [0|1] ""  HSCU
 SG_ DrvSelMd3ReqDnd : 10|1@0+ (1,0) [0|1] ""  HSCU
 SG_ DrvSelMd2Stat : 13|1@0+ (1,0) [0|1] ""  HSCU
 SG_ DrvSelMd2ReqDnd : 12|1@0+ (1,0) [0|1] ""  HSCU
 SG_ DSMSS_DrvSelMd0Pn : 47|1@0+ (1,0) [0|1] ""  HSCU
 SG_ DSMSS_DrvSelMd8Pn : 32|1@0+ (1,0) [0|1] ""  HSCU
 SG_ DSMSS_DrvSelMd7Pn : 33|1@0+ (1,0) [0|1] ""  HSCU
 SG_ DSMSS_DrvSelMd6Pn : 34|1@0+ (1,0) [0|1] ""  HSCU
 SG_ DSMSS_DrvSelMd5Pn : 35|1@0+ (1,0) [0|1] ""  HSCU
 SG_ DSMSS_DrvSelMd4Pn : 36|1@0+ (1,0) [0|1] ""  HSCU
 SG_ DSMSS_DrvSelMd3Pn : 37|1@0+ (1,0) [0|1] ""  HSCU
 SG_ DSMSS_DrvSelMd2Pn : 38|1@0+ (1,0) [0|1] ""  HSCU
 SG_ DSMSS_DrvSelMd1Pn : 39|1@0+ (1,0) [0|1] ""  HSCU
 SG_ DSMSS_DrvSelMd8Un : 24|1@0+ (1,0) [0|1] ""  HSCU
 SG_ DSMSS_DrvSelMd7Un : 25|1@0+ (1,0) [0|1] ""  HSCU
 SG_ DSMSS_DrvSelMd6Un : 26|1@0+ (1,0) [0|1] ""  HSCU
 SG_ DSMSS_DrvSelMd5Un : 27|1@0+ (1,0) [0|1] ""  HSCU
 SG_ DSMSS_DrvSelMd4Un : 28|1@0+ (1,0) [0|1] ""  HSCU
 SG_ DSMSS_DrvSelMd3Un : 29|1@0+ (1,0) [0|1] ""  HSCU
 SG_ DSMSS_DrvSelMd2Un : 30|1@0+ (1,0) [0|1] ""  HSCU
 SG_ DSMSS_DrvSelMd1Un : 31|1@0+ (1,0) [0|1] ""  HSCU
 SG_ DrvSelMd1ReqDnd : 14|1@0+ (1,0) [0|1] ""  HSCU
 SG_ DrvSelMd1Stat : 15|1@0+ (1,0) [0|1] ""  HSCU

BO_ 969 PPEI_Platform_Immobilizer_Data: 8 HSCU
 SG_ ImoInf : 7|64@0+ (1,0) [0|1.844674407371E+019] ""  DECM

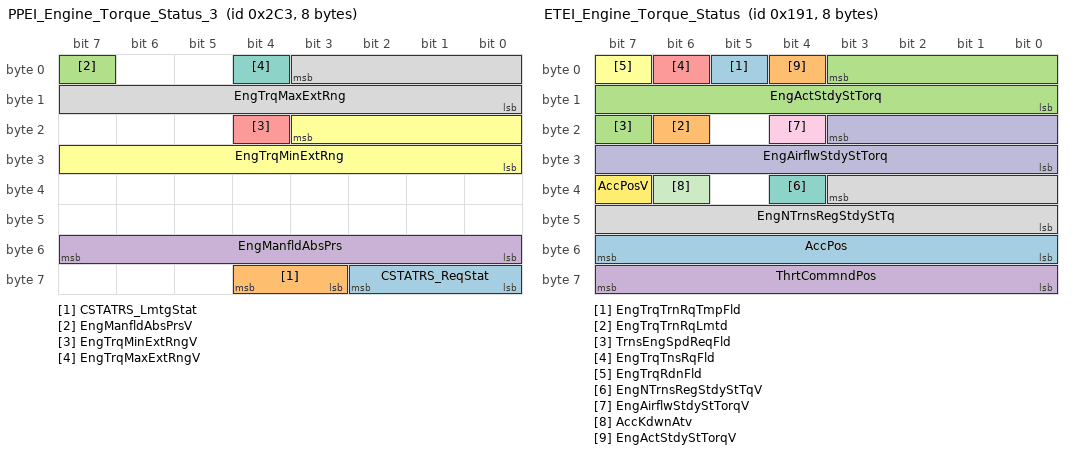
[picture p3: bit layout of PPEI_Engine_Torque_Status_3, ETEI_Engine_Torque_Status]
BO_ 707 PPEI_Engine_Torque_Status_3: 8 DECM
 SG_ CSTATRS_ReqStat : 58|3@0+ (1,0) [0|7] ""  HSCU
 SG_ CSTATRS_LmtgStat : 60|2@0+ (1,0) [0|3] ""  HSCU
 SG_ EngManfldAbsPrsV : 7|1@0+ (1,0) [0|1] ""  HSCU
 SG_ EngManfldAbsPrs : 55|8@0+ (0.5,0) [0|127.5] "kPa"  HSCU
 SG_ EngTrqMinExtRngV : 20|1@0+ (1,0) [0|1] ""  HSCU
 SG_ EngTrqMinExtRng : 19|12@0+ (0.5,-848) [-848|1199.5] "Nm"  HSCU
 SG_ EngTrqMaxExtRngV : 4|1@0+ (1,0) [0|1] ""  HSCU
 SG_ EngTrqMaxExtRng : 3|12@0+ (0.5,-848) [-848|1199.5] "Nm"  HSCU

BO_ 417 ETEI_Engine_General_Status: 7 DECM
 SG_ EngCrsCntrlMode : 29|3@0+ (1,0) [0|7] ""  HSCU
 SG_ EngPstOxgSnsDgAstRq : 31|1@0+ (1,0) [0|1] ""  HSCU
 SG_ CrsCtrlCnstSpdAct : 26|1@0+ (1,0) [0|1] ""  HSCU
 SG_ WrmUpShftPtrnRq : 25|1@0+ (1,0) [0|1] ""  HSCU
 SG_ EngIdlSpdRdcdRng : 39|8@0+ (8,0) [0|2040] "rpm"  HSCU
 SG_ EngAlwCltAdp : 24|1@0+ (1,0) [0|1] ""  HSCU
 SG_ BsTrgtEngIdlSpd : 47|8@0+ (8,0) [0|2040] "rpm"  HSCU
 SG_ AccPdlPosPcntFullRngV : 17|1@0+ (1,0) [0|1] ""  HSCU
 SG_ AccPdlPosPcntFullRng : 55|8@0+ (0.392157,0) [0|100.000035] "%"  HSCU
 SG_ DslPrtFltrIdlRgtnMdReq : 20|1@0+ (1,0) [0|1] ""  HSCU
 SG_ DslPartFltrClngAlgActM : 18|1@0+ (1,0) [0|1] ""  HSCU
 SG_ DslPartFltrClngAlgAct : 19|1@0+ (1,0) [0|1] ""  HSCU
 SG_ EngCylDeactMd : 9|2@0+ (1,0) [0|3] ""  HSCU
 SG_ ACCmCltEngd : 13|1@0+ (1,0) [0|1] ""  HSCU
 SG_ ParkNeutralSwStatV : 21|1@0+ (1,0) [0|1] ""  HSCU
 SG_ ParkNeutralSwStat : 22|1@0+ (1,0) [0|1] ""  HSCU
 SG_ EngColdHiIdleActive : 23|1@0+ (1,0) [0|1] ""  HSCU
 SG_ EngCyDactTqSmtAct : 6|1@0+ (1,0) [0|1] ""  HSCU
 SG_ EngBrkStat : 15|2@0+ (1,0) [0|3] ""  HSCU
 SG_ TracCntlSysPwrtrnInhbt : 12|1@0+ (1,0) [0|1] ""  HSCU
 SG_ EngMtlProtAtv : 11|1@0+ (1,0) [0|1] ""  HSCU
 SG_ EngDgTrqCnvClUnlkRqd : 7|1@0+ (1,0) [0|1] ""  HSCU
 SG_ EngCyldrDeactReqd : 10|1@0+ (1,0) [0|1] ""  HSCU
 SG_ ETGRReqdGear : 3|4@0+ (1,0) [0|15] ""  HSCU
 SG_ ETGRReqType : 5|2@0+ (1,0) [0|3] ""  HSCU

BO_ 401 ETEI_Engine_Torque_Status: 8 DECM
 SG_ EngTrqTrnRqTmpFld : 5|1@0+ (1,0) [0|1] ""  HSCU
 SG_ EngTrqTrnRqLmtd : 22|1@0+ (1,0) [0|1] ""  HSCU
 SG_ TrnsEngSpdReqFld : 23|1@0+ (1,0) [0|1] ""  HSCU
 SG_ ThrtCommndPos : 63|8@0+ (0.392157,0) [0|100.000035] "%"  HSCU
 SG_ EngTrqTnsRqFld : 6|1@0+ (1,0) [0|1] ""  HSCU
 SG_ EngTrqRdnFld : 7|1@0+ (1,0) [0|1] ""  HSCU
 SG_ EngNTrnsRegStdyStTqV : 36|1@0+ (1,0) [0|1] ""  HSCU
 SG_ EngNTrnsRegStdyStTq : 35|12@0+ (0.5,-848) [-848|1199.5] "Nm"  HSCU
 SG_ EngAirflwStdyStTorqV : 20|1@0+ (1,0) [0|1] ""  HSCU
 SG_ EngAirflwStdyStTorq : 19|12@0+ (0.5,-848) [-848|1199.5] "Nm"  HSCU
 SG_ AccKdwnAtv : 38|1@0+ (1,0) [0|1] ""  HSCU
 SG_ AccPosV : 39|1@0+ (1,0) [0|1] ""  HSCU
 SG_ AccPos : 55|8@0+ (0.392157,0) [0|100.000035] "%"  HSCU
 SG_ EngActStdyStTorqV : 4|1@0+ (1,0) [0|1] ""  HSCU
 SG_ EngActStdyStTorq : 3|12@0+ (0.5,-848) [-848|1199.5] "Nm"  HSCU

BO_ 479 PTEI_Propulsion_Gen_Stat_1_HS: 1 HSCU
 SG_ PrplsnSysAtv : 7|1@0+ (1,0) [0|1] ""  DECM
 SG_ PTShftLvrLckRqd : 6|1@0+ (1,0) [0|1] ""  DECM

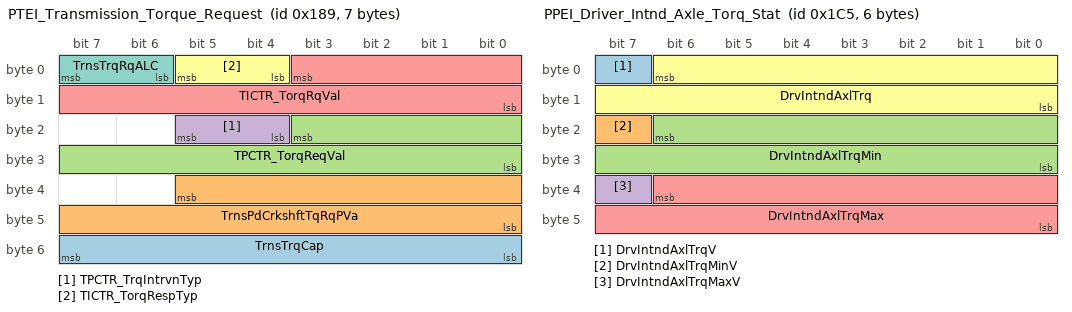
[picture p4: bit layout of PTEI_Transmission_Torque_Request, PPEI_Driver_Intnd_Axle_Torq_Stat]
BO_ 393 PTEI_Transmission_Torque_Request: 7 DECM
 SG_ TrnsTrqCap : 55|8@0+ (4,0) [0|1020] "Nm"  HSCU
 SG_ TrnsPdCrkshftTqRqPVa : 37|14@0+ (1,0) [0|16383] ""  HSCU
 SG_ TPCTR_TorqReqVal : 19|12@0+ (0.5,-848) [-848|1199.5] "Nm"  HSCU
 SG_ TPCTR_TrqIntrvnTyp : 21|2@0+ (1,0) [0|3] ""  HSCU
 SG_ TICTR_TorqRqVal : 3|12@0+ (0.5,-848) [-848|1199.5] "Nm"  HSCU
 SG_ TICTR_TorqRespTyp : 5|2@0+ (1,0) [0|3] ""  HSCU
 SG_ TrnsTrqRqALC : 7|2@0+ (1,0) [0|3] ""  HSCU

BO_ 190 PTEI_Brake_Apply_Status: 2 DECM
 SG_ PTSnsdBrkPdlPosV : 0|1@0+ (1,0) [0|1] ""  HSCU
 SG_ PTSnsdBrkPdlPos : 15|8@0+ (0.392157,0) [0|100.000035] "%"  HSCU

BO_ 463 PPEI_Secondary_Axle_General_Info: 1 DECM
 SG_ SecAxlNonEmMalfIO : 7|1@0+ (1,0) [0|1] ""  HSCU
 SG_ SecAxlOperMod : 3|4@0+ (1,0) [0|3] ""  HSCU
 SG_ SecAxlTmpInhIO : 6|1@0+ (1,0) [0|1] ""  HSCU

BO_ 497 PPEI_Platform_General_Status: 8 HSCU
 SG_ FuelFltLfRstRqd : 56|1@0+ (1,0) [0|1] ""  DECM
 SG_ ACCompSysVDA : 9|1@0+ (1,0) [0|1] ""  DECM
 SG_ BkupPwrModeMstrVDA : 7|1@0+ (1,0) [0|1] ""  DECM
 SG_ PrkBrkVDA : 35|1@0+ (1,0) [0|1] ""  DECM
 SG_ PrkBrkVDM : 62|1@0+ (1,0) [0|1] ""  DECM
 SG_ BkupPwrModeMstrVDM : 61|1@0+ (1,0) [0|1] ""  DECM
 SG_ ACCompSysVDM : 60|1@0+ (1,0) [0|1] ""  DECM
 SG_ AirbgVDA : 57|1@0+ (1,0) [0|1] ""  DECM
 SG_ SysBkupPwrMdEn : 6|1@0+ (1,0) [0|1] ""  DECM
 SG_ SysBkUpPwrMd : 5|2@0+ (1,0) [0|3] ""  DECM
 SG_ SysPwrMd : 1|2@0+ (1,0) [0|3] ""  DECM
 SG_ TrStLgMdAtv : 34|1@0+ (1,0) [0|1] ""  DECM
 SG_ DispMeasSys : 59|1@0+ (1,0) [0|1] ""  DECM
 SG_ ACCmpsrFldOn : 63|1@0+ (1,0) [0|1] ""  DECM
 SG_ ACCompModReq : 12|2@0+ (1,0) [0|3] ""  DECM
 SG_ ACCompNormLd : 55|8@0+ (0.1,0) [0|25.5] "l/min"  DECM
 SG_ ACCompNormLdV : 10|1@0+ (1,0) [0|1] ""  DECM
 SG_ PTORSMstrEngShtReq : 13|1@0+ (1,0) [0|1] ""  DECM
 SG_ EngOilLfRstRq : 37|1@0+ (1,0) [0|1] ""  DECM
 SG_ SIRDpl : 58|1@0+ (1,0) [0|1] ""  DECM
 SG_ PTORmStMsEngStRq : 14|1@0+ (1,0) [0|1] ""  DECM
 SG_ RmVehStrRq : 15|1@0+ (1,0) [0|1] ""  DECM
 SG_ ThrtlPrgrsnReq : 39|2@0+ (1,0) [0|3] ""  DECM
 SG_ PrkBrkSwAtv : 36|1@0+ (1,0) [0|1] ""  DECM
 SG_ PMMAccTrmSt : 2|1@0+ (1,0) [0|1] ""  DECM
 SG_ PMMRunCrkTrmSt : 3|1@0+ (1,0) [0|1] ""  DECM
 SG_ ImmblzrPreRelPswdStat : 8|1@0+ (1,0) [0|1] ""  DECM
 SG_ ImmblzrPreRelPswrd : 23|16@0+ (1,0) [0|65535] "passwrd"  DECM

BO_ 2016 USDT_Req_to_ECM_HS: 8 Vector__XXX
 SG_ DgnInf : 7|64@0+ (1,0) [0|1.844674407371E+019] "" Vector__XXX

BO_ 453 PPEI_Driver_Intnd_Axle_Torq_Stat: 6 DECM
 SG_ DrvIntndAxlTrqV : 7|1@0+ (1,0) [0|1] ""  HSCU
 SG_ DrvIntndAxlTrqMinV : 23|1@0+ (1,0) [0|1] ""  HSCU
 SG_ DrvIntndAxlTrqMin : 22|15@0+ (2,-22534) [-22534|43000] "Nm"  HSCU
 SG_ DrvIntndAxlTrqMaxV : 39|1@0+ (1,0) [0|1] ""  HSCU
 SG_ DrvIntndAxlTrqMax : 38|15@0+ (2,-22534) [-22534|43000] "Nm"  HSCU
 SG_ DrvIntndAxlTrq : 6|15@0+ (2,-22534) [-22534|43000] "Nm"  HSCU

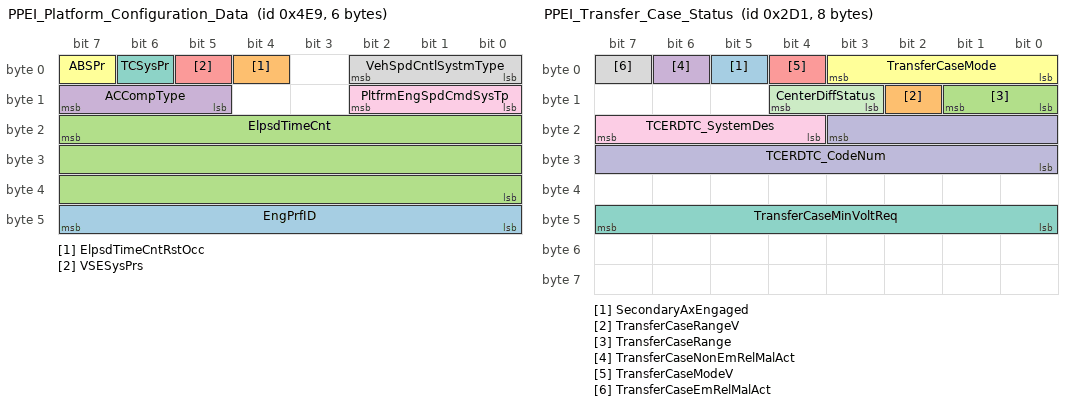
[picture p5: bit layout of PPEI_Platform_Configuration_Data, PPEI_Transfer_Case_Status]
BO_ 1257 PPEI_Platform_Configuration_Data: 6 DECM
 SG_ EngPrfID : 47|8@0+ (2,0) [0|510] "kW"  HSCU
 SG_ ElpsdTimeCntRstOcc : 4|1@0+ (1,0) [0|1] ""  HSCU
 SG_ ElpsdTimeCnt : 23|24@0+ (1,0) [0|16777215] "min"  HSCU
 SG_ ACCompType : 15|3@0+ (1,0) [0|7] ""  HSCU
 SG_ VSESysPrs : 5|1@0+ (1,0) [0|1] ""  HSCU
 SG_ ABSPr : 7|1@0+ (1,0) [0|1] ""  HSCU
 SG_ TCSysPr : 6|1@0+ (1,0) [0|1] ""  HSCU
 SG_ VehSpdCntlSystmType : 2|3@0+ (1,0) [0|7] ""  HSCU
 SG_ PltfrmEngSpdCmdSysTp : 10|3@0+ (1,0) [0|7] ""  HSCU

BO_ 721 PPEI_Transfer_Case_Status: 8 HSCU
 SG_ SecondaryAxEngaged : 5|1@0+ (1,0) [0|0] ""  DECM
 SG_ TransferCaseRangeV : 10|1@0+ (1,0) [0|0] ""  DECM
 SG_ TransferCaseRange : 9|2@0+ (1,0) [0|0] ""  DECM
 SG_ TransferCaseNonEmRelMalAct : 6|1@0+ (1,0) [0|0] ""  DECM
 SG_ TransferCaseModeV : 4|1@0+ (1,0) [0|0] ""  DECM
 SG_ TransferCaseMode : 3|4@0+ (1,0) [0|0] ""  DECM
 SG_ TransferCaseMinVoltReq : 47|8@0+ (0.07843,0) [0|19.9996] "V"  DECM
 SG_ TransferCaseEmRelMalAct : 7|1@0+ (1,0) [0|0] ""  DECM
 SG_ TCERDTC_SystemDes : 23|4@0+ (1,0) [0|0] ""  DECM
 SG_ TCERDTC_CodeNum : 19|12@0+ (1,0) [0|4095] ""  DECM
 SG_ CenterDiffStatus : 12|2@0+ (1,0) [0|0] ""  DECM

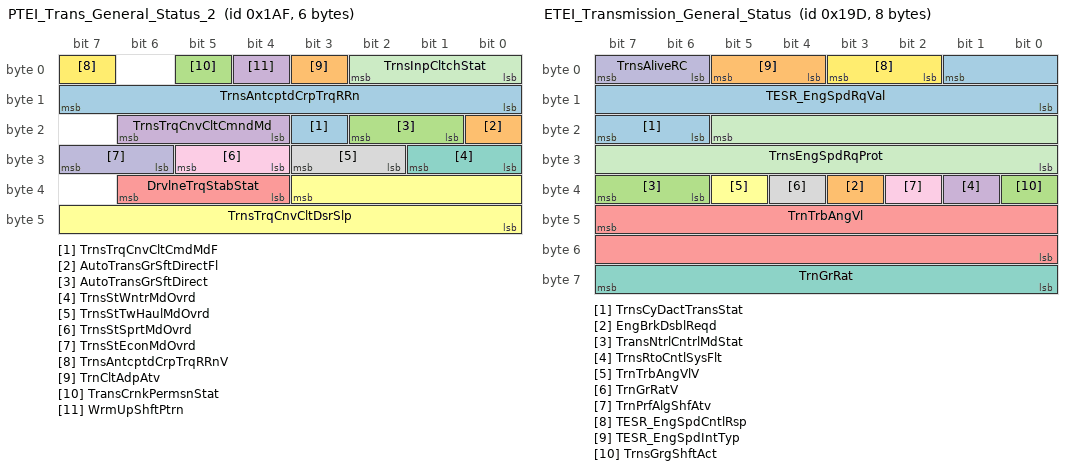
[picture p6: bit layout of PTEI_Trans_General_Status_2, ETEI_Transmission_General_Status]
BO_ 431 PTEI_Trans_General_Status_2: 6 HSCU
 SG_ TrnsTrqCnvCltCmdMdF : 19|1@0+ (1,0) [0|1] ""  DECM
 SG_ AutoTransGrSftDirectFl : 16|1@0+ (1,0) [0|1] ""  DECM
 SG_ AutoTransGrSftDirect : 18|2@0+ (1,0) [0|3] ""  DECM
 SG_ TrnsTrqCnvCltCmndMd : 22|3@0+ (1,0) [0|7] ""  DECM
 SG_ DrvlneTrqStabStat : 38|3@0+ (1,0) [0|7] ""  DECM
 SG_ TrnsTrqCnvCltDsrSlp : 35|12@0- (1,0) [-2048|2047] "rpm"  DECM
 SG_ TrnsStWntrMdOvrd : 25|2@0+ (1,0) [0|3] ""  DECM
 SG_ TrnsStTwHaulMdOvrd : 27|2@0+ (1,0) [0|3] ""  DECM
 SG_ TrnsStSprtMdOvrd : 29|2@0+ (1,0) [0|3] ""  DECM
 SG_ TrnsStEconMdOvrd : 31|2@0+ (1,0) [0|3] ""  DECM
 SG_ TrnsInpCltchStat : 2|3@0+ (1,0) [0|0] ""  DECM
 SG_ TrnsAntcptdCrpTrqRRnV : 7|1@0+ (1,0) [0|1] ""  DECM
 SG_ TrnsAntcptdCrpTrqRRn : 15|8@0+ (0.5,0) [0|127.5] "Nm"  DECM
 SG_ TrnCltAdpAtv : 3|1@0+ (1,0) [0|1] ""  DECM
 SG_ TransCrnkPermsnStat : 5|1@0+ (1,0) [0|1] ""  DECM
 SG_ WrmUpShftPtrn : 4|1@0+ (1,0) [0|1] ""  DECM

BO_ 413 ETEI_Transmission_General_Status: 8 HSCU
 SG_ TrnsCyDactTransStat : 23|2@0+ (1,0) [0|3] ""  DECM
 SG_ EngBrkDsblReqd : 35|1@0+ (1,0) [0|1] ""  DECM
 SG_ TransNtrlCntrlMdStat : 39|2@0+ (1,0) [0|3] ""  DECM
 SG_ TrnsRtoCntlSysFlt : 33|1@0+ (1,0) [0|1] ""  DECM
 SG_ TrnTrbAngVl : 47|16@0+ (0.25,0) [0|16383.75] "rpm"  DECM
 SG_ TrnTrbAngVlV : 37|1@0+ (1,0) [0|1] ""  DECM
 SG_ TrnGrRat : 63|8@0+ (0.03125,0) [0|7.96875] ""  DECM
 SG_ TrnGrRatV : 36|1@0+ (1,0) [0|1] ""  DECM
 SG_ TrnPrfAlgShfAtv : 34|1@0+ (1,0) [0|1] ""  DECM
 SG_ TrnsAliveRC : 7|2@0+ (1,0) [0|3] ""  DECM
 SG_ TrnsEngSpdRqProt : 21|14@0+ (1,0) [0|16383] ""  DECM
 SG_ TESR_EngSpdCntlRsp : 3|2@0+ (1,0) [0|3] ""  DECM
 SG_ TESR_EngSpdRqVal : 1|10@0+ (8,0) [0|8184] "rpm"  DECM
 SG_ TESR_EngSpdIntTyp : 5|2@0+ (1,0) [0|3] ""  DECM
 SG_ TrnsGrgShftAct : 32|1@0+ (1,0) [0|1] ""  DECM

BO_ 719 PPEI_Rear_Virtual_Bump_Req_Stat: 8 HSCU
 SG_ RVBATC_AxTrqReqAct : 15|1@0+ (1,0) [0|0] ""  DECM
 SG_ RVBATC_AxTrqReq : 14|15@0+ (2,-22534) [-22543|43000] "Nm"  DECM
 SG_ RearVirtBumpAxTrqCmdRC : 7|2@0+ (1,0) [0|3] ""  DECM
 SG_ RearVirtBumpAxTrqCmdProtVal : 31|16@0+ (1,0) [0|65535] ""  DECM

BO_ 717 PPEI_Collision_Prep_Req_Status: 5 HSCU
 SG_ ColPrSysAxlTrqCmdProtVal : 31|16@0+ (1,0) [0|65535] ""  DECM
 SG_ CPSATC_AxlTrqRqstAct : 15|1@0+ (1,0) [0|1] ""  DECM
 SG_ CPSATC_AxlTrqRqst : 14|15@0+ (2,-22534) [-22534|43000] "NM"  DECM
 SG_ ColPrSysAxlTrqCmdRC : 7|2@0+ (1,0) [0|3] ""  DECM

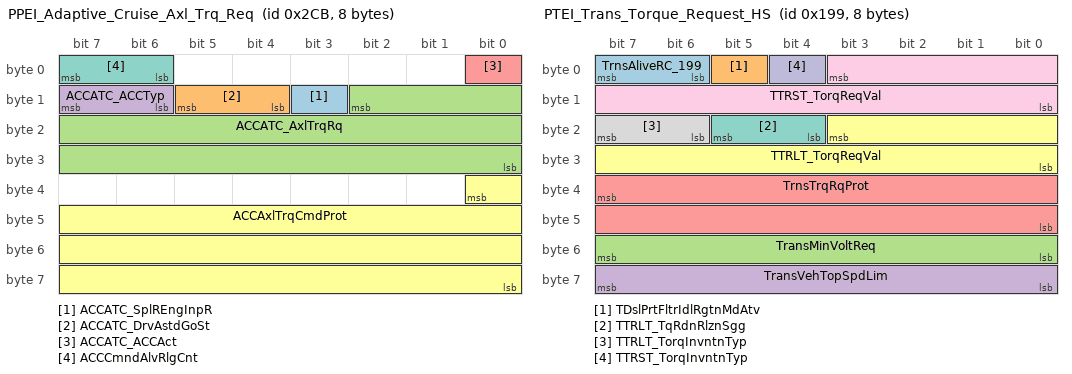
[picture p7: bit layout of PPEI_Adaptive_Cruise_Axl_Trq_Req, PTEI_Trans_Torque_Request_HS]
BO_ 715 PPEI_Adaptive_Cruise_Axl_Trq_Req: 8 HSCU
 SG_ ACCATC_SplREngInpR : 11|1@0+ (1,0) [0|1] ""  DECM
 SG_ ACCATC_DrvAstdGoSt : 13|2@0+ (1,0) [0|3] ""  DECM
 SG_ ACCATC_AxlTrqRq : 10|19@0+ (0.125,-22534) [-22534|43001.875] "Nm"  DECM
 SG_ ACCATC_ACCTyp : 15|2@0+ (1,0) [0|3] ""  DECM
 SG_ ACCATC_ACCAct : 0|1@0+ (1,0) [0|1] ""  DECM
 SG_ ACCAxlTrqCmdProt : 32|25@0+ (1,0) [0|33554431] ""  DECM
 SG_ ACCCmndAlvRlgCnt : 7|2@0+ (1,0) [0|3] ""  DECM

BO_ 409 PTEI_Trans_Torque_Request_HS: 8 HSCU
 SG_ TrnsAliveRC_199 : 7|2@0+ (1,0) [0|3] ""  DECM
 SG_ TDslPrtFltrIdlRgtnMdAtv : 5|1@0+ (1,0) [0|1] ""  DECM
 SG_ TransMinVoltReq : 55|8@0+ (0.07843,0) [0|19.99965] "volts"  DECM
 SG_ TransVehTopSpdLim : 63|8@0+ (2,0) [0|510] "km / h"  DECM
 SG_ TrnsTrqRqProt : 39|16@0+ (1,0) [0|65535] ""  DECM
 SG_ TTRLT_TorqReqVal : 19|12@0+ (0.5,-848) [-848|1199.5] "Nm"  DECM
 SG_ TTRLT_TqRdnRlznSgg : 21|2@0+ (1,0) [0|3] ""  DECM
 SG_ TTRLT_TorqInvntnTyp : 23|2@0+ (1,0) [0|3] ""  DECM
 SG_ TTRST_TorqReqVal : 3|12@0+ (0.5,-848) [-848|1199.5] "Nm"  DECM
 SG_ TTRST_TorqInvntnTyp : 4|1@0+ (1,0) [0|1] ""  DECM

BO_ 505 PPEI_PTO_Command_Data: 8 HSCU
 SG_ PTOVehTopSpdLimVal : 63|8@0+ (2,0) [0|510] "km / h"  DECM
 SG_ AccPdlPwrTkOffOvrAct : 4|1@0+ (1,0) [0|1] ""  DECM
 SG_ PTOTGRReqdGear : 35|4@0+ (1,0) [0|15] ""  DECM
 SG_ PTOTGRReqType : 37|2@0+ (1,0) [0|3] ""  DECM
 SG_ PTORmtEngStrtReq : 44|1@0+ (1,0) [0|1] ""  DECM
 SG_ TrnsPTOCltchRelRqd : 38|1@0+ (1,0) [0|1] ""  DECM
 SG_ FstIdlMdAct : 47|1@0+ (1,0) [0|1] ""  DECM
 SG_ PTOMdAct : 46|1@0+ (1,0) [0|1] ""  DECM
 SG_ PTOEngTrqLmtRchd : 45|1@0+ (1,0) [0|1] ""  DECM
 SG_ PTOEngTrqLmtValER : 55|8@0+ (8,0) [0|2040] "Nm"  DECM
 SG_ PltfrmEngSpdCmdMdAct : 3|1@0+ (1,0) [0|1] ""  DECM
 SG_ PltfrmEngSpdReq : 2|11@0+ (4,0) [0|8188] "rpm"  DECM
 SG_ PFESpdCmdOnSwAct : 7|1@0+ (1,0) [0|1] ""  DECM
 SG_ PFESpdCmdDeSwAct : 5|1@0+ (1,0) [0|1] ""  DECM
 SG_ PFESpdCmdInSwAct : 6|1@0+ (1,0) [0|1] ""  DECM
 SG_ PFESpdCmdSwDIntg : 21|2@0+ (1,0) [0|3] ""  DECM
 SG_ PFEngSpdCmdAlvRlgCnt : 23|2@0+ (1,0) [0|3] ""  DECM
 SG_ PltfrmEngSpdCmdProtVal : 19|12@0+ (1,0) [0|4095] ""  DECM
 SG_ PTORmtEngShtdwnReqd : 39|1@0+ (1,0) [0|1] ""  DECM

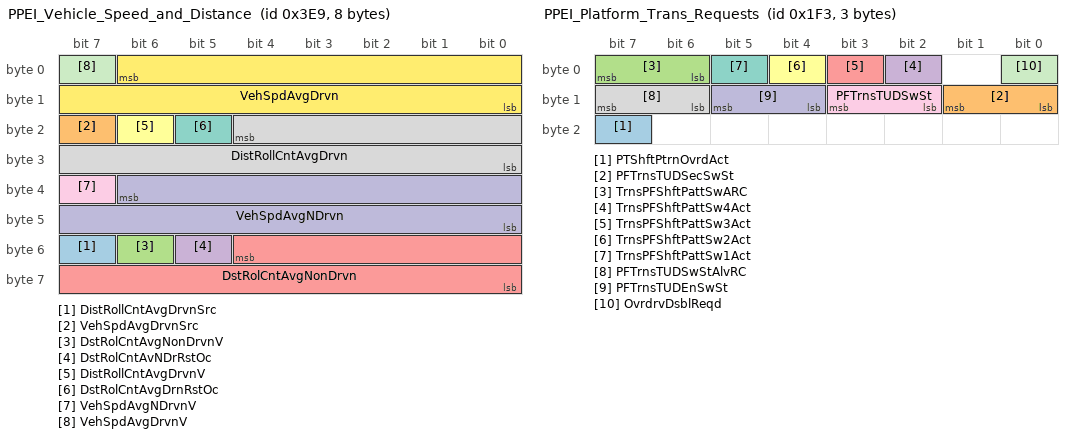
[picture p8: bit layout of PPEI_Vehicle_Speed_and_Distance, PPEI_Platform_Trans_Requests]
BO_ 1001 PPEI_Vehicle_Speed_and_Distance: 8 DECM
 SG_ DistRollCntAvgDrvnSrc : 55|1@0+ (1,0) [0|1] ""  HSCU
 SG_ VehSpdAvgDrvnSrc : 23|1@0+ (1,0) [0|1] ""  HSCU
 SG_ DstRolCntAvgNonDrvnV : 54|1@0+ (1,0) [0|1] ""  HSCU
 SG_ DstRolCntAvNDrRstOc : 53|1@0+ (1,0) [0|1] ""  HSCU
 SG_ DstRolCntAvgNonDrvn : 52|13@0+ (0.125,0) [0|1023.875] "m"  HSCU
 SG_ DistRollCntAvgDrvnV : 22|1@0+ (1,0) [0|1] ""  HSCU
 SG_ DstRolCntAvgDrnRstOc : 21|1@0+ (1,0) [0|1] ""  HSCU
 SG_ DistRollCntAvgDrvn : 20|13@0+ (0.125,0) [0|1023.875] "m"  HSCU
 SG_ VehSpdAvgNDrvnV : 39|1@0+ (1,0) [0|1] ""  HSCU
 SG_ VehSpdAvgNDrvn : 38|15@0+ (0.015625,0) [0|511.984375] "km / h"  HSCU
 SG_ VehSpdAvgDrvnV : 7|1@0+ (1,0) [0|1] ""  HSCU
 SG_ VehSpdAvgDrvn : 6|15@0+ (0.015625,0) [0|511.984375] "km / h"  HSCU

BO_ 499 PPEI_Platform_Trans_Requests: 3 HSCU
 SG_ PTShftPtrnOvrdAct : 23|1@0+ (1,0) [0|1] ""  DECM
 SG_ PFTrnsTUDSecSwSt : 9|2@0+ (1,0) [0|3] ""  DECM
 SG_ TrnsPFShftPattSwARC : 7|2@0+ (1,0) [0|3] ""  DECM
 SG_ TrnsPFShftPattSw4Act : 2|1@0+ (1,0) [0|1] ""  DECM
 SG_ TrnsPFShftPattSw3Act : 3|1@0+ (1,0) [0|1] ""  DECM
 SG_ TrnsPFShftPattSw2Act : 4|1@0+ (1,0) [0|1] ""  DECM
 SG_ TrnsPFShftPattSw1Act : 5|1@0+ (1,0) [0|1] ""  DECM
 SG_ PFTrnsTUDSwStAlvRC : 15|2@0+ (1,0) [0|3] ""  DECM
 SG_ PFTrnsTUDSwSt : 11|2@0+ (1,0) [0|3] ""  DECM
 SG_ PFTrnsTUDEnSwSt : 13|2@0+ (1,0) [0|3] ""  DECM
 SG_ OvrdrvDsblReqd : 0|1@0+ (1,0) [0|1] ""  DECM

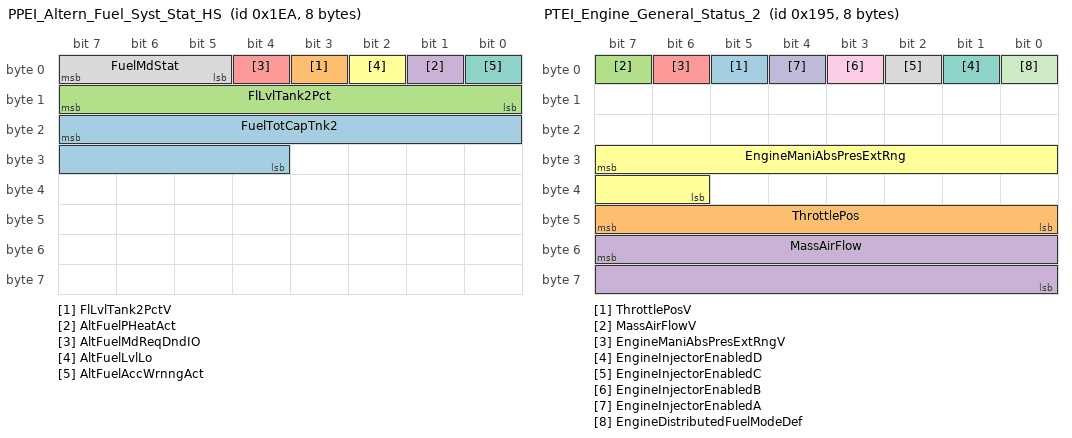
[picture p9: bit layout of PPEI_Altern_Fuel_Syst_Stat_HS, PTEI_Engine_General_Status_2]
BO_ 490 PPEI_Altern_Fuel_Syst_Stat_HS: 8 HSCU
 SG_ FuelTotCapTnk2 : 23|12@0+ (0.125,0) [0|511.875] "liters"  DECM
 SG_ FlLvlTank2PctV : 3|1@0+ (1,0) [0|1] ""  DECM
 SG_ FlLvlTank2Pct : 15|8@0+ (0.392157,0) [0|100.000035] "%"  DECM
 SG_ AltFuelPHeatAct : 1|1@0+ (1,0) [0|1] ""  DECM
 SG_ AltFuelMdReqDndIO : 4|1@0+ (1,0) [0|1] ""  DECM
 SG_ AltFuelLvlLo : 2|1@0+ (1,0) [0|1] ""  DECM
 SG_ AltFuelAccWrnngAct : 0|1@0+ (1,0) [0|1] ""  DECM
 SG_ FuelMdStat : 7|3@0+ (1,0) [0|7] ""  DECM

BO_ 481 PPEI_Cruise_Control_Sw_Status: 7 HSCU
 SG_ CrsSecSwStatPVal : 51|4@0+ (1,0) [0|15] ""  DECM
 SG_ CrsSecSwStatARC : 41|2@0+ (1,0) [0|3] ""  DECM
 SG_ CrsSecSwStat : 27|4@0+ (1,0) [0|15] ""  DECM
 SG_ DrvSelMdSw3Sta : 37|1@0+ (1,0) [0|1] ""  DECM
 SG_ DrvSelMdSw2Sta : 38|1@0+ (1,0) [0|1] ""  DECM
 SG_ AuxHtrRq : 31|1@0+ (1,0) [0|1] ""  DECM
 SG_ AuxHtrAtv : 30|1@0+ (1,0) [0|1] ""  DECM
 SG_ DrvSelMdSwStaARC : 33|2@0+ (1,0) [0|3] ""  DECM
 SG_ DrvSelMdSw1Sta : 39|1@0+ (1,0) [0|1] ""  DECM
 SG_ CrsSpdLmtrSwStatPVal : 55|4@0+ (1,0) [0|15] ""  DECM
 SG_ CrsSpdLmtrSwStatARC : 43|2@0+ (1,0) [0|3] ""  DECM
 SG_ FuelMdSwActV : 29|1@0+ (1,0) [0|1] ""  DECM
 SG_ FuelMdSwAct : 28|1@0+ (1,0) [0|1] ""  DECM
 SG_ CrsSpdLmtrSwStat : 47|4@0+ (1,0) [0|15] ""  DECM
 SG_ AdptCrsGapSwAct : 23|2@0+ (1,0) [0|3] ""  DECM
 SG_ CrsCntrlSwStCanSwAct : 7|1@0+ (1,0) [0|1] ""  DECM
 SG_ CrsCntrlSwStSwDataIntgty : 1|2@0+ (1,0) [0|3] ""  DECM
 SG_ CrsCntrlSwStSpdInSwAct : 3|1@0+ (1,0) [0|1] ""  DECM
 SG_ CrsCntrlSwStSpDcSwAct : 2|1@0+ (1,0) [0|1] ""  DECM
 SG_ CrsCntrlSwStSetSwAct : 4|1@0+ (1,0) [0|1] ""  DECM
 SG_ CrsCntrlSwStResSwAct : 5|1@0+ (1,0) [0|1] ""  DECM
 SG_ CrsCntrlSwStOnSwAct : 6|1@0+ (1,0) [0|1] ""  DECM
 SG_ CrsCntrlSwStatProtValue : 15|8@0+ (1,0) [0|255] ""  DECM
 SG_ CrsCntrlSwStAlvRollCnt : 17|2@0+ (1,0) [0|3] ""  DECM
 SG_ CrsCntCncRq : 18|1@0+ (1,0) [0|1] ""  DECM

BO_ 460 PPEI_Secondary_Axle_Status: 8 HSCU
 SG_ PowertrainTransferCaseMode : 31|2@0+ (1,0) [0|0] ""  DECM

BO_ 459 PPEI_Transfer_Case_Coupling_Stat: 8 HSCU
 SG_ TransferCaseCoupValActV : 3|1@0+ (1,0) [0|0] ""  DECM
 SG_ TransferCaseCoupValAct : 2|11@0+ (0.0488519785051295,0) [0|100] "%"  DECM
 SG_ TransferCaseCoupRepType : 4|1@0+ (1,0) [0|0] ""  DECM

BO_ 405 PTEI_Engine_General_Status_2: 8 DECM
 SG_ ThrottlePosV : 5|1@0+ (1,0) [0|0] ""  HSCU
 SG_ ThrottlePos : 47|8@0+ (0.392156862745098,0) [0|100] "%"  HSCU
 SG_ MassAirFlowV : 7|1@0+ (1,0) [0|0] ""  HSCU
 SG_ MassAirFlow : 55|16@0+ (0.01,0) [0|655.35] "g/s"  HSCU
 SG_ EngineManiAbsPresExtRngV : 6|1@0+ (1,0) [0|0] ""  HSCU
 SG_ EngineManiAbsPresExtRng : 31|10@0+ (0.5,0) [0|511.5] "kPa"  HSCU
 SG_ EngineInjectorEnabledD : 1|1@0+ (1,0) [0|0] ""  HSCU
 SG_ EngineInjectorEnabledC : 2|1@0+ (1,0) [0|0] ""  HSCU
 SG_ EngineInjectorEnabledB : 3|1@0+ (1,0) [0|0] ""  HSCU
 SG_ EngineInjectorEnabledA : 4|1@0+ (1,0) [0|0] ""  HSCU
 SG_ EngineDistributedFuelModeDef : 0|1@0+ (1,0) [0|0] ""  HSCU

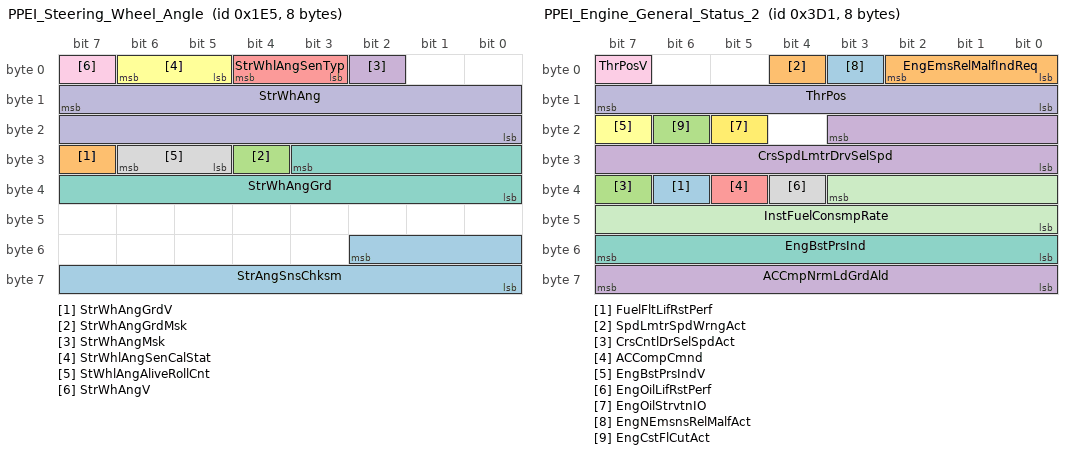
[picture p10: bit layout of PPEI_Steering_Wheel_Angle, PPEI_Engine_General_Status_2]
BO_ 485 PPEI_Steering_Wheel_Angle: 8 HSCU
 SG_ StrAngSnsChksm : 50|11@0+ (1,0) [0|2047] ""  DECM
 SG_ StrWhAngGrdV : 31|1@0+ (1,0) [0|1] ""  DECM
 SG_ StrWhAngGrdMsk : 28|1@0+ (1,0) [0|1] ""  DECM
 SG_ StrWhAngMsk : 2|1@0+ (1,0) [0|1] ""  DECM
 SG_ StrWhlAngSenTyp : 4|2@0+ (1,0) [0|3] ""  DECM
 SG_ StrWhlAngSenCalStat : 6|2@0+ (1,0) [0|3] ""  DECM
 SG_ StrWhAngGrd : 27|12@0- (1,0) [-2048|2047] "deg/sec"  DECM
 SG_ StWhlAngAliveRollCnt : 30|2@0+ (1,0) [0|3] ""  DECM
 SG_ StrWhAngV : 7|1@0+ (1,0) [0|1] ""  DECM
 SG_ StrWhAng : 15|16@0- (0.0625,0) [-2048|2047.9375] "deg"  DECM

BO_ 201 PPEI_Engine_General_Status_1: 8 DECM
 SG_ PrsElvtdIdlCntlStat : 49|1@0+ (1,0) [0|1] ""  HSCU
 SG_ Eng12vStrtrMtrCmmdOn : 53|1@0+ (1,0) [0|1] ""  HSCU
 SG_ EngCntrlRunCrnkTrmSt : 52|1@0+ (1,0) [0|1] ""  HSCU
 SG_ EngAirIntBstPrV : 51|1@0+ (1,0) [0|1] ""  HSCU
 SG_ EngAirIntBstPr : 63|8@0- (1,0) [-128|127] "kPaG"  HSCU
 SG_ SpdLmtrSpdWrngEnbld : 47|1@0+ (1,0) [0|1] ""  HSCU
 SG_ EngCylDactEvntPndg : 54|1@0+ (1,0) [0|1] ""  HSCU
 SG_ EngCylDeactMd : 43|2@0+ (1,0) [0|3] ""  HSCU
 SG_ RmVhStrtEngRng : 55|1@0+ (1,0) [0|1] ""  HSCU
 SG_ PFEngSpdCmndSpcd : 45|1@0+ (1,0) [0|1] ""  HSCU
 SG_ DrThrtlOvrrdDetProtVal : 25|2@0+ (1,0) [0|3] ""  HSCU
 SG_ DrThrtlOvrdDetAlvRlCnt : 27|2@0+ (1,0) [0|3] ""  HSCU
 SG_ PltfrmEngSpdCmdInhtRq : 44|1@0+ (1,0) [0|1] ""  HSCU
 SG_ PT_BrkPedDscrtInpStatV : 41|1@0+ (1,0) [0|1] ""  HSCU
 SG_ PT_BrkPedDscrtInpStat : 40|1@0+ (1,0) [0|1] ""  HSCU
 SG_ AccActPos : 39|8@0+ (0.392157,0) [0|100.000035] "%"  HSCU
 SG_ CrsCntEnbld : 29|1@0+ (1,0) [0|1] ""  HSCU
 SG_ CrsCntAtv : 30|1@0+ (1,0) [0|1] ""  HSCU
 SG_ DrvThrottlOvrrdDet : 28|1@0+ (1,0) [0|1] ""  HSCU
 SG_ PT_CrnkAct : 6|1@0+ (1,0) [0|1] ""  HSCU
 SG_ PTRunAbrt : 4|1@0+ (1,0) [0|1] ""  HSCU
 SG_ PTO_PT_RunAbrtd : 3|1@0+ (1,0) [0|1] ""  HSCU
 SG_ PTCrnkAbrted : 5|1@0+ (1,0) [0|1] ""  HSCU
 SG_ EngSpdStat : 1|2@0+ (1,0) [0|3] ""  HSCU
 SG_ EngSpd : 15|16@0+ (0.25,0) [0|16383.75] "rpm"  HSCU
 SG_ EngRunAtv : 7|1@0+ (1,0) [0|1] ""  HSCU
 SG_ EngIdlAtv : 2|1@0+ (1,0) [0|1] ""  HSCU
 SG_ AccActPosV : 31|1@0+ (1,0) [0|1] ""  HSCU

BO_ 977 PPEI_Engine_General_Status_2: 8 DECM
 SG_ FuelFltLifRstPerf : 38|1@0+ (1,0) [0|1] ""  HSCU
 SG_ SpdLmtrSpdWrngAct : 4|1@0+ (1,0) [0|1] ""  HSCU
 SG_ CrsCntlDrSelSpdAct : 39|1@0+ (1,0) [0|1] ""  HSCU
 SG_ ACCmpNrmLdGrdAld : 63|8@0+ (0.1,0) [0|25.5] "dm3/m/s"  HSCU
 SG_ ACCompCmnd : 37|1@0+ (1,0) [0|1] ""  HSCU
 SG_ EngBstPrsIndV : 23|1@0+ (1,0) [0|1] ""  HSCU
 SG_ EngBstPrsInd : 55|8@0+ (0.392157,0) [0|100.000035] "%"  HSCU
 SG_ EngOilLifRstPerf : 36|1@0+ (1,0) [0|1] ""  HSCU
 SG_ ThrPosV : 7|1@0+ (1,0) [0|1] ""  HSCU
 SG_ ThrPos : 15|8@0+ (0.392157,0) [0|100.000035] "%"  HSCU
 SG_ InstFuelConsmpRate : 35|12@0+ (0.025,0) [0|102.375] "ltrs/hr"  HSCU
 SG_ EngOilStrvtnIO : 21|1@0+ (1,0) [0|1] ""  HSCU
 SG_ EngNEmsnsRelMalfAct : 3|1@0+ (1,0) [0|1] ""  HSCU
 SG_ EngEmsRelMalfIndReq : 2|3@0+ (1,0) [0|7] ""  HSCU
 SG_ EngCstFlCutAct : 22|1@0+ (1,0) [0|1] ""  HSCU
 SG_ CrsSpdLmtrDrvSelSpd : 19|12@0+ (0.0625,0) [0|255.9375] "km / h"  HSCU

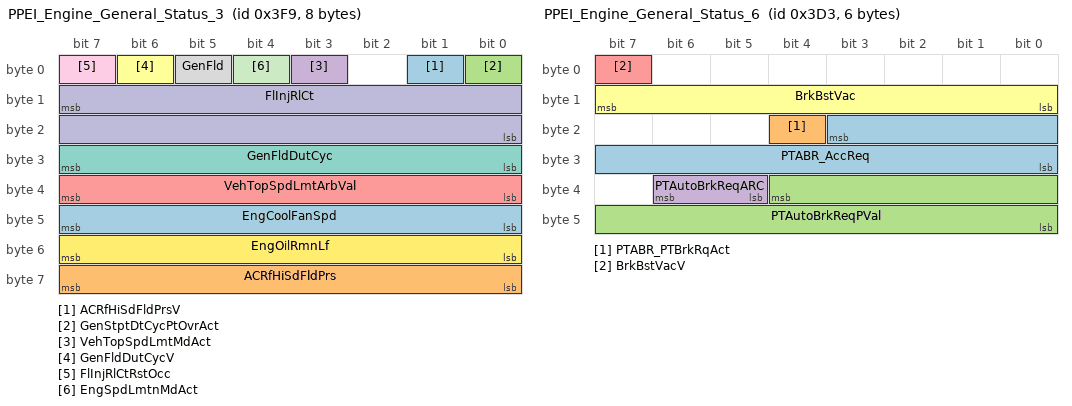
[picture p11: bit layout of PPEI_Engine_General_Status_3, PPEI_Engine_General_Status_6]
BO_ 1017 PPEI_Engine_General_Status_3: 8 DECM
 SG_ ACRfHiSdFldPrsV : 1|1@0+ (1,0) [0|1] ""  HSCU
 SG_ ACRfHiSdFldPrs : 63|8@0+ (14,0) [0|3570] "kPaG"  HSCU
 SG_ GenStptDtCycPtOvrAct : 0|1@0+ (1,0) [0|1] ""  HSCU
 SG_ VehTopSpdLmtMdAct : 3|1@0+ (1,0) [0|1] ""  HSCU
 SG_ VehTopSpdLmtArbVal : 39|8@0+ (2,0) [0|510] "km / h"  HSCU
 SG_ GenFldDutCycV : 6|1@0+ (1,0) [0|1] ""  HSCU
 SG_ GenFldDutCyc : 31|8@0+ (0.392157,0) [0|100.000035] "%"  HSCU
 SG_ GenFld : 5|1@0+ (1,0) [0|1] ""  HSCU
 SG_ FlInjRlCtRstOcc : 7|1@0+ (1,0) [0|1] ""  HSCU
 SG_ FlInjRlCt : 15|16@0+ (3.05176E-005,0) [0|1.999970916] "liters"  HSCU
 SG_ EngSpdLmtnMdAct : 4|1@0+ (1,0) [0|1] ""  HSCU
 SG_ EngOilRmnLf : 55|8@0+ (0.392157,0) [0|100.000035] "%"  HSCU
 SG_ EngCoolFanSpd : 47|8@0+ (0.392157,0) [0|100.000035] "%"  HSCU

BO_ 1217 PPEI_Engine_General_Status_4: 8 DECM
 SG_ LegPstDTCClrDrvCyCm : 40|1@0+ (1,0) [0|1] ""  HSCU
 SG_ LegDiagColdStCndMet : 47|1@0+ (1,0) [0|1] ""  HSCU
 SG_ LegDiagColdStCndFltPr : 46|1@0+ (1,0) [0|1] ""  HSCU
 SG_ EngEconMdCmnd : 44|1@0+ (1,0) [0|1] ""  HSCU
 SG_ DslExhFldRmngDstHRsV : 41|1@0+ (1,0) [0|1] ""  HSCU
 SG_ DslExhFldRmngDstHRs : 54|15@0+ (2,0) [0|65534] "km"  HSCU
 SG_ EngOilHotIO : 45|1@0+ (1,0) [0|1] ""  HSCU
 SG_ OAT_PT_EstV : 3|1@0+ (1,0) [0|1] ""  HSCU
 SG_ LegDiagStndCndMet : 2|1@0+ (1,0) [0|1] ""  HSCU
 SG_ LegDiagStndCndFltPr : 1|1@0+ (1,0) [0|1] ""  HSCU
 SG_ OAT_PT_EstM : 4|1@0+ (1,0) [0|1] ""  HSCU
 SG_ OAT_PT_Est : 39|8@0+ (0.5,-40) [-40|87.5] "deg C"  HSCU
 SG_ EngWrmUpAch : 0|1@0+ (1,0) [0|1] ""  HSCU
 SG_ EngIntAirTmpV : 5|1@0+ (1,0) [0|1] ""  HSCU
 SG_ EngIntAirTmp : 31|8@0+ (1,-40) [-40|215] "deg C"  HSCU
 SG_ EngCltTmpV : 6|1@0+ (1,0) [0|1] ""  HSCU
 SG_ EngCltTmp : 23|8@0+ (1,-40) [-40|215] "deg C"  HSCU
 SG_ BarPrsAbsV : 7|1@0+ (1,0) [0|1] ""  HSCU
 SG_ BarPrsAbs : 15|8@0+ (0.5,0) [0|127.5] "kPa"  HSCU

BO_ 1233 PPEI_Engine_General_Status_5: 8 DECM
 SG_ EngShtdwnAct : 48|1@0+ (1,0) [0|1] ""  HSCU
 SG_ EngShtdwnPndgIO : 49|1@0+ (1,0) [0|1] ""  HSCU
 SG_ FuelFltChgNwIO : 51|1@0+ (1,0) [0|1] ""  HSCU
 SG_ PTExPrtclFltrWrn2IO : 50|1@0+ (1,0) [0|1] ""  HSCU
 SG_ PTHiElecLdReqd : 52|1@0+ (1,0) [0|1] ""  HSCU
 SG_ PTExPrtclFltrWrnIO : 53|1@0+ (1,0) [0|1] ""  HSCU
 SG_ AirCndOffIO : 0|1@0+ (1,0) [0|1] ""  HSCU
 SG_ DslGlwPlgIO : 55|1@0+ (1,0) [0|1] ""  HSCU
 SG_ StgDisIO : 30|1@0+ (1,0) [0|1] ""  HSCU
 SG_ RdcdPwrIO : 31|1@0+ (1,0) [0|1] ""  HSCU
 SG_ FuelTotCap : 27|12@0+ (0.125,0) [0|511.875] "liters"  BCM_HS
 SG_ FlLvlPctV : 28|1@0+ (1,0) [0|1] ""  HSCU
 SG_ FlLvlPct : 47|8@0+ (0.392157,0) [0|100.000035] "%"  HSCU
 SG_ EngWtrInFlIO : 54|1@0+ (1,0) [0|1] ""  HSCU
 SG_ EngOilTmpV : 7|1@0+ (1,0) [0|1] ""  HSCU
 SG_ EngOilTmp : 15|8@0+ (1,-40) [-40|215] "deg C"  HSCU
 SG_ EngOilPrsV : 6|1@0+ (1,0) [0|1] ""  HSCU
 SG_ EngOilPrsLwIO : 5|1@0+ (1,0) [0|1] ""  HSCU
 SG_ EngOilPrs : 23|8@0+ (4,0) [0|1020] "kPa"  HSCU
 SG_ EngOilLvlLwIO : 4|1@0+ (1,0) [0|1] ""  HSCU
 SG_ EngOilChngIO : 3|1@0+ (1,0) [0|1] ""  HSCU
 SG_ EngHt_StpEngIO : 1|1@0+ (1,0) [0|1] ""  HSCU
 SG_ EngHotFuelEnrchmntIO : 2|1@0+ (1,0) [0|1] ""  HSCU
 SG_ CkFlFilrCapIO : 29|1@0+ (1,0) [0|1] ""  HSCU

BO_ 979 PPEI_Engine_General_Status_6: 6 DECM
 SG_ PTABR_AccReq : 19|12@0- (0.01,0) [-20.48|20.47] "m/s^2"  HSCU
 SG_ PTABR_PTBrkRqAct : 20|1@0+ (1,0) [0|1] ""  HSCU
 SG_ PTAutoBrkReqPVal : 36|13@0+ (1,0) [0|8191] ""  HSCU
 SG_ PTAutoBrkReqARC : 38|2@0+ (1,0) [0|3] ""  HSCU
 SG_ BrkBstVacV : 7|1@0+ (1,0) [0|1] ""  HSCU
 SG_ BrkBstVac : 15|8@0+ (0.5,0) [0|127.5] "kPa"  HSCU

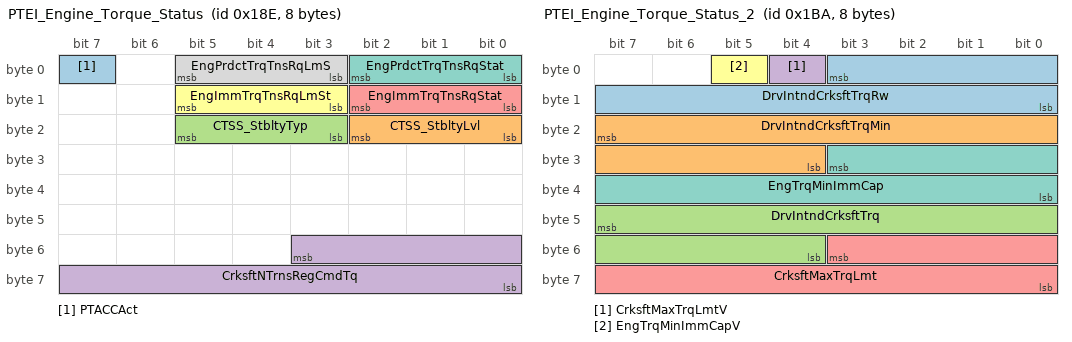
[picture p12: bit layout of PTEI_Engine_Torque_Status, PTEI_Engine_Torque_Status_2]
BO_ 398 PTEI_Engine_Torque_Status: 8 DECM
 SG_ PTACCAct : 7|1@0+ (1,0) [0|1] ""  HSCU
 SG_ CTSS_StbltyLvl : 18|3@0+ (1,0) [0|7] ""  HSCU
 SG_ CTSS_StbltyTyp : 21|3@0+ (1,0) [0|7] ""  HSCU
 SG_ CrksftNTrnsRegCmdTq : 51|12@0+ (0.5,-848) [-848|1199.5] "Nm"  HSCU
 SG_ EngImmTrqTnsRqStat : 10|3@0+ (1,0) [0|7] ""  HSCU
 SG_ EngImmTrqTnsRqLmSt : 13|3@0+ (1,0) [0|7] ""  HSCU
 SG_ EngPrdctTrqTnsRqStat : 2|3@0+ (1,0) [0|7] ""  HSCU
 SG_ EngPrdctTrqTnsRqLmS : 5|3@0+ (1,0) [0|7] ""  HSCU

BO_ 442 PTEI_Engine_Torque_Status_2: 8 DECM
 SG_ DrvIntndCrksftTrqRw : 3|12@0+ (0.5,-848) [-848|1199.5] "Nm"  HSCU
 SG_ DrvIntndCrksftTrqMin : 23|12@0+ (0.5,-848) [-848|1199.5] "Nm"  HSCU
 SG_ DrvIntndCrksftTrq : 47|12@0+ (0.5,-848) [-848|1199.5] "Nm"  HSCU
 SG_ CrksftMaxTrqLmtV : 4|1@0+ (1,0) [0|1] ""  HSCU
 SG_ CrksftMaxTrqLmt : 51|12@0+ (0.5,-848) [-848|1199.5] "Nm"  HSCU
 SG_ EngTrqMinImmCapV : 5|1@0+ (1,0) [0|1] ""  HSCU
 SG_ EngTrqMinImmCap : 27|12@0+ (0.5,-848) [-848|1199.5] "Nm"  HSCU

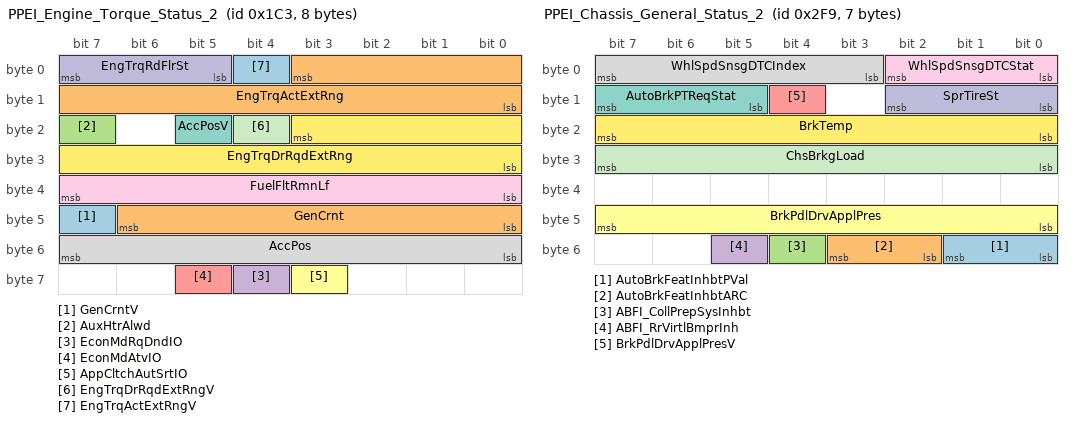
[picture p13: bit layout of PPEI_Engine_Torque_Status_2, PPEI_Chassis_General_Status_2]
BO_ 451 PPEI_Engine_Torque_Status_2: 8 DECM
 SG_ GenCrntV : 47|1@0+ (1,0) [0|1] ""  HSCU
 SG_ GenCrnt : 46|7@0+ (1,0) [0|127] "A"  HSCU
 SG_ AuxHtrAlwd : 23|1@0+ (1,0) [0|1] ""  HSCU
 SG_ EconMdRqDndIO : 60|1@0+ (1,0) [0|1] ""  HSCU
 SG_ EconMdAtvIO : 61|1@0+ (1,0) [0|1] ""  HSCU
 SG_ AppCltchAutSrtIO : 59|1@0+ (1,0) [0|1] ""  HSCU
 SG_ AccPosV : 21|1@0+ (1,0) [0|1] ""  HSCU
 SG_ AccPos : 55|8@0+ (0.392157,0) [0|100.000035] "%"  HSCU
 SG_ FuelFltRmnLf : 39|8@0+ (0.392157,0) [0|100.000035] "%"  HSCU
 SG_ EngTrqRdFlrSt : 7|3@0+ (1,0) [0|7] ""  HSCU
 SG_ EngTrqDrRqdExtRngV : 20|1@0+ (1,0) [0|1] ""  HSCU
 SG_ EngTrqDrRqdExtRng : 19|12@0+ (0.5,-848) [-848|1199.5] "Nm"  HSCU
 SG_ EngTrqActExtRngV : 4|1@0+ (1,0) [0|1] ""  HSCU
 SG_ EngTrqActExtRng : 3|12@0+ (0.5,-848) [-848|1199.5] "Nm"  HSCU

BO_ 452 PPEI_Torque_Request_Status: 8 DECM
 SG_ FSpRgACCSwADdPVal : 50|2@0+ (1,0) [0|3] ""  HSCU
 SG_ FSpRgACCSwADdARC : 6|2@0+ (1,0) [0|3] ""  HSCU
 SG_ FSpRgACCSwADd : 7|1@0+ (1,0) [0|1] ""  HSCU
 SG_ AutBrkAccActPsStRC : 34|2@0+ (1,0) [0|3] ""  HSCU
 SG_ AutBrkAccActPsStPVal : 48|9@0+ (1,0) [0|511] ""  HSCU
 SG_ ABAAPS_AccPos : 47|8@0+ (0.392157,0) [0|100.000035] "%"  HSCU
 SG_ ABAAPS_AccPosV : 32|1@0+ (1,0) [0|1] ""  HSCU
 SG_ ACCATCS_LmtgStat : 12|2@0+ (1,0) [0|3] ""  HSCU
 SG_ ACCATCS_RqStat : 15|3@0+ (1,0) [0|7] ""  HSCU
 SG_ RdLdNomAxlTrq : 10|19@0+ (0.125,-22534) [-22534|43001.875] "Nm"  HSCU
 SG_ AccPdlOvrrdAtvProtVal : 1|2@0+ (1,0) [0|3] ""  HSCU
 SG_ AccPdlOvrrdAtvARC : 3|2@0+ (1,0) [0|3] ""  HSCU
 SG_ AccPdlOvrrdAtv : 4|1@0+ (1,0) [0|1] ""  HSCU
 SG_ CPSATCS_ReqStatus : 37|3@0+ (1,0) [0|0] ""  HSCU
 SG_ CPSATCS_LmtngStatus : 39|2@0+ (1,0) [0|0] ""  HSCU
 SG_ RVBATCS_ReqStat : 53|3@0+ (1,0) [0|0] ""  HSCU
 SG_ RVBATCS_LmtngStat : 55|2@0+ (1,0) [0|0] ""  HSCU

BO_ 489 PPEI_Chassis_General_Status_1: 8 HSCU
 SG_ IMUDataMsk : 25|1@0+ (1,0) [0|1] ""  DECM
 SG_ WhlSlpStARC : 54|2@0+ (1,0) [0|3] ""  DECM
 SG_ DrvIndpntBrkAppAct : 55|1@0+ (1,0) [0|1] ""  DECM
 SG_ WhlSlpSt : 52|2@0+ (1,0) [0|3] ""  DECM
 SG_ BSTGRReqdGear : 19|4@0+ (1,0) [0|15] ""  DECM
 SG_ BSTGRReqType : 21|2@0+ (1,0) [0|3] ""  DECM
 SG_ VehDynOvrUndrStr : 49|10@0- (0.5,0) [-256|255.5] "%"  DECM
 SG_ VSELatAccV : 4|1@0+ (1,0) [0|1] ""  DECM
 SG_ VSELatAcc : 3|12@0- (0.015625,0) [-32|31.984375] "m/s^2"  DECM
 SG_ VSEAct : 24|1@0+ (1,0) [0|1] ""  DECM
 SG_ VhDynCntlSysSt : 39|3@0+ (1,0) [0|7] ""  DECM
 SG_ VehDynYawRateV : 36|1@0+ (1,0) [0|1] ""  DECM
 SG_ VehDynYawRate : 35|12@0- (0.0625,0) [-128|127.9375] "deg/sec"  DECM
 SG_ TrnsBrkSysCltchRelRqd : 5|1@0+ (1,0) [0|1] ""  DECM
 SG_ TracCntrlSysDrIntnt : 26|1@0+ (1,0) [0|1] ""  DECM
 SG_ VehDynOvrUndrStrV : 50|1@0+ (1,0) [0|1] ""  DECM
 SG_ TCSysEnbld : 27|1@0+ (1,0) [0|1] ""  DECM
 SG_ TCSysAtv : 28|1@0+ (1,0) [0|1] ""  DECM
 SG_ BrkPdlDrvAppPrsDetcdV : 7|1@0+ (1,0) [0|1] ""  DECM
 SG_ BrkPdlDrvAppPrsDetcd : 6|1@0+ (1,0) [0|1] ""  DECM
 SG_ ACCBrkngAct : 31|1@0+ (1,0) [0|1] ""  DECM
 SG_ ABSFld : 29|1@0+ (1,0) [0|1] ""  DECM
 SG_ ABSAtv : 30|1@0+ (1,0) [0|1] ""  DECM

BO_ 761 PPEI_Chassis_General_Status_2: 7 HSCU
 SG_ AutoBrkFeatInhbtPVal : 49|2@0+ (1,0) [0|3] ""  DECM
 SG_ AutoBrkFeatInhbtARC : 51|2@0+ (1,0) [0|3] ""  DECM
 SG_ ABFI_CollPrepSysInhbt : 52|1@0+ (1,0) [0|1] ""  DECM
 SG_ ABFI_RrVirtlBmprInh : 53|1@0+ (1,0) [0|1] ""  DECM
 SG_ BrkPdlDrvApplPresV : 12|1@0+ (1,0) [0|1] ""  DECM
 SG_ BrkPdlDrvApplPres : 47|8@0+ (75,0) [0|19125] "kPa"  DECM
 SG_ AutoBrkPTReqStat : 15|3@0+ (1,0) [0|0] ""  DECM
 SG_ WhlSpdSnsgDTCIndex : 7|5@0+ (1,0) [0|31] ""  DECM
 SG_ WhlSpdSnsgDTCStat : 2|3@0+ (1,0) [0|7] ""  DECM
 SG_ SprTireSt : 10|3@0+ (1,0) [0|7] ""  DECM
 SG_ ChsBrkgLoad : 31|8@0+ (0.392157,0) [0|100.000035] "%"  DECM
 SG_ BrkTemp : 23|8@0+ (4,-40) [-40|980] "deg C"  DECM

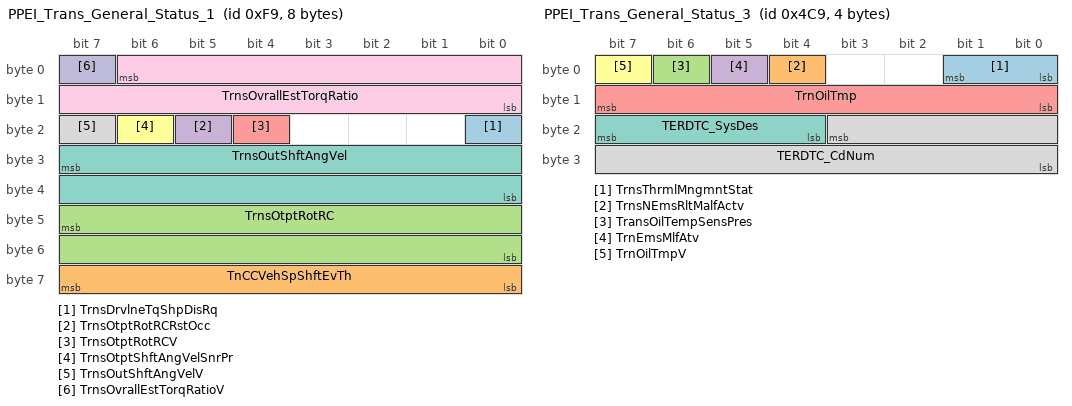
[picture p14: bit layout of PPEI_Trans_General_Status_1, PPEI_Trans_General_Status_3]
BO_ 249 PPEI_Trans_General_Status_1: 8 HSCU
 SG_ TrnsDrvlneTqShpDisRq : 16|1@0+ (1,0) [0|1] ""  DECM
 SG_ TnCCVehSpShftEvTh : 63|8@0+ (2,0) [0|510] "km / h"  DECM
 SG_ TrnsOtptRotRC : 47|16@0+ (0.0078125,0) [0|511.9921875] "rot"  DECM
 SG_ TrnsOtptRotRCRstOcc : 21|1@0+ (1,0) [0|1] ""  DECM
 SG_ TrnsOtptRotRCV : 20|1@0+ (1,0) [0|1] ""  DECM
 SG_ TrnsOtptShftAngVelSnrPr : 22|1@0+ (1,0) [0|1] ""  DECM
 SG_ TrnsOutShftAngVel : 31|16@0+ (0.25,0) [0|16383.75] "rpm"  DECM
 SG_ TrnsOutShftAngVelV : 23|1@0+ (1,0) [0|1] ""  DECM
 SG_ TrnsOvrallEstTorqRatio : 6|15@0- (0.00390625,0) [-64|63.99609375] ""  DECM
 SG_ TrnsOvrallEstTorqRatioV : 7|1@0+ (1,0) [0|1] ""  DECM

BO_ 501 PPEI_Trans_General_Status_2: 8 HSCU
 SG_ TrnsShftLvrPos : 27|4@0+ (1,0) [0|15] ""  DECM
 SG_ EngRecDwnshftIO : 54|1@0+ (1,0) [0|1] ""  DECM
 SG_ TrnsPattSelEcnMdOCm : 52|1@0+ (1,0) [0|1] ""  DECM
 SG_ CltStartSwAtvV : 38|1@0+ (1,0) [0|1] ""  DECM
 SG_ CltStartSwAtv : 37|1@0+ (1,0) [0|1] ""  DECM
 SG_ CltchPdlActPosV : 55|1@0+ (1,0) [0|1] ""  DECM
 SG_ CltchPdlActPos : 63|8@0+ (0.392157,0) [0|100.000035] "%"  DECM
 SG_ TrnsEngdStateV : 50|1@0+ (1,0) [0|1] ""  DECM
 SG_ TrnsEngdState : 49|2@0+ (1,0) [0|3] ""  DECM
 SG_ TrnsShftLvrLckRqd : 47|1@0+ (1,0) [0|1] ""  DECM
 SG_ TransTUDMdStat : 41|2@0+ (1,0) [0|3] ""  DECM
 SG_ TrnCrpMdAtv : 46|1@0+ (1,0) [0|1] ""  DECM
 SG_ TrnsSkpShftIO : 23|1@0+ (1,0) [0|1] ""  DECM
 SG_ TrnsSftMdStat : 34|3@0+ (1,0) [0|7] ""  DECM
 SG_ TrnsRngInhbtStat : 31|3@0+ (1,0) [0|7] ""  DECM
 SG_ TopTrvlCltchSwActV : 15|1@0+ (1,0) [0|1] ""  DECM
 SG_ TopTrvlCltchSwAct : 14|1@0+ (1,0) [0|1] ""  DECM
 SG_ EngRecmndUpshftIO : 22|1@0+ (1,0) [0|1] ""  DECM
 SG_ DrvtShftCntrlTrgtGear : 19|4@0+ (1,0) [0|15] ""  DECM
 SG_ DrShftCntrlReqDndIO : 21|1@0+ (1,0) [0|1] ""  DECM
 SG_ TrnShftPtrnActStat : 44|3@0+ (1,0) [0|7] ""  DECM
 SG_ TrnsFldPrsPrsnt : 51|1@0+ (1,0) [0|1] ""  DECM
 SG_ TrnsShftLvrPosV : 28|1@0+ (1,0) [0|1] ""  DECM
 SG_ TrnsTrqCnvCltCmndMd : 7|3@0+ (1,0) [0|7] ""  DECM
 SG_ AutoTransComndGear : 11|4@0+ (1,0) [0|15] ""  DECM
 SG_ AutoTransGrSftDirect : 13|2@0+ (1,0) [0|3] ""  DECM
 SG_ TransEstGear : 3|4@0+ (1,0) [0|15] ""  DECM
 SG_ TransEstGearV : 4|1@0+ (1,0) [0|1] ""  DECM

BO_ 1225 PPEI_Trans_General_Status_3: 4 DECM
 SG_ TrnsThrmlMngmntStat : 1|2@0+ (1,0) [0|3] ""  HSCU
 SG_ TrnsNEmsRltMalfActv : 4|1@0+ (1,0) [0|1] ""  HSCU
 SG_ TransOilTempSensPres : 6|1@0+ (1,0) [0|1] ""  HSCU
 SG_ TrnEmsMlfAtv : 5|1@0+ (1,0) [0|1] ""  HSCU
 SG_ TrnOilTmp : 15|8@0+ (1,-40) [-40|215] "deg C"  HSCU
 SG_ TrnOilTmpV : 7|1@0+ (1,0) [0|1] ""  HSCU
 SG_ TERDTC_SysDes : 23|4@0+ (1,0) [0|15] ""  HSCU
 SG_ TERDTC_CdNum : 19|12@0+ (1,0) [0|4095] ""  HSCU

BO_ 298 Body_Information_HS: 8 HSCU
 SG_ ChmAct : 55|1@0+ (1,0) [0|1] ""  DECM
 SG_ DDAjrSwAtvM : 63|1@0+ (1,0) [0|1] ""  DECM
 SG_ CrshAlrtDrvrSlctdType : 5|1@0+ (1,0) [0|1] ""  DECM
 SG_ PsSbltAtcV : 54|1@0+ (1,0) [0|1] ""  DECM
 SG_ PsSbltAtc : 53|1@0+ (1,0) [0|1] ""  DECM
 SG_ TrlrBrkDsplyAct : 51|1@0+ (1,0) [0|1] ""  DECM
 SG_ RdSpdCatType : 45|2@0+ (1,0) [0|0] ""  DECM
 SG_ LnCat : 47|2@0+ (1,0) [0|0] ""  DECM
 SG_ FncRdClass : 50|3@0+ (1,0) [0|7] ""  DECM
 SG_ SprtLnRd : 43|1@0+ (1,0) [0|1] ""  DECM
 SG_ CntrldAccRd : 39|1@0+ (1,0) [0|1] ""  DECM
 SG_ BldUpArDet : 11|1@0+ (1,0) [0|1] ""  DECM
 SG_ MpDataAvlbl : 3|1@0+ (1,0) [0|1] ""  DECM
 SG_ SusCustStngReq : 42|3@0+ (1,0) [0|0] ""  DECM
 SG_ StrCustStngReq : 38|3@0+ (1,0) [0|0] ""  DECM
 SG_ RstrCustFctrDef : 35|1@0+ (1,0) [0|1] ""  DECM
 SG_ DrvlnCustStngReq : 34|3@0+ (1,0) [0|7] ""  DECM
 SG_ ChmMstrVDA : 22|1@0+ (1,0) [0|1] ""  DECM
 SG_ IPCVDA : 21|1@0+ (1,0) [0|1] ""  DECM
 SG_ HeadUpDispVDA : 20|1@0+ (1,0) [0|1] ""  DECM
 SG_ HapticSeatVDA : 52|1@0+ (1,0) [0|1] ""  DECM
 SG_ RRDoorAjarSwAct : 23|1@0+ (1,0) [0|1] ""  DECM
 SG_ PDAjrSwAtv : 10|1@0+ (1,0) [0|1] ""  DECM
 SG_ DDAjrSwAtv : 9|1@0+ (1,0) [0|1] ""  DECM
 SG_ TrlrHWIntrfcVDA : 4|1@0+ (1,0) [0|1] ""  DECM
 SG_ DrId : 15|3@0+ (1,0) [0|7] ""  DECM
 SG_ EnrgMgtLdShdRq : 19|4@0+ (1,0) [0|15] ""  DECM
 SG_ DrSbltAtcV : 2|1@0+ (1,0) [0|1] ""  DECM
 SG_ TrlrHtchSwAtv : 0|1@0+ (1,0) [0|1] ""  DECM
 SG_ TreInfMonSysRstReq : 7|1@0+ (1,0) [0|1] ""  DECM
 SG_ HUDActv : 6|1@0+ (1,0) [0|1] ""  DECM
 SG_ BatVltV : 1|1@0+ (1,0) [0|1] ""  DECM
 SG_ BatVlt : 31|8@0+ (0.1,3) [3|28.5] "volts"  DECM
 SG_ RLDoorAjarSwAct : 8|1@0+ (1,0) [0|1] ""  DECM
 SG_ DrSbltAtc : 12|1@0+ (1,0) [0|1] ""  DECM

BO_ 1241 PPEI_Fuel_System_General_Status: 3 HSCU
 SG_ FSERDTC_CdNum : 11|12@0+ (1,0) [0|4095] ""  DECM
 SG_ FSERDTC_SysDes : 15|4@0+ (1,0) [0|15] ""  DECM
 SG_ FuelSysEmsRldMlfAtv : 7|1@0+ (1,0) [0|1] ""  DECM

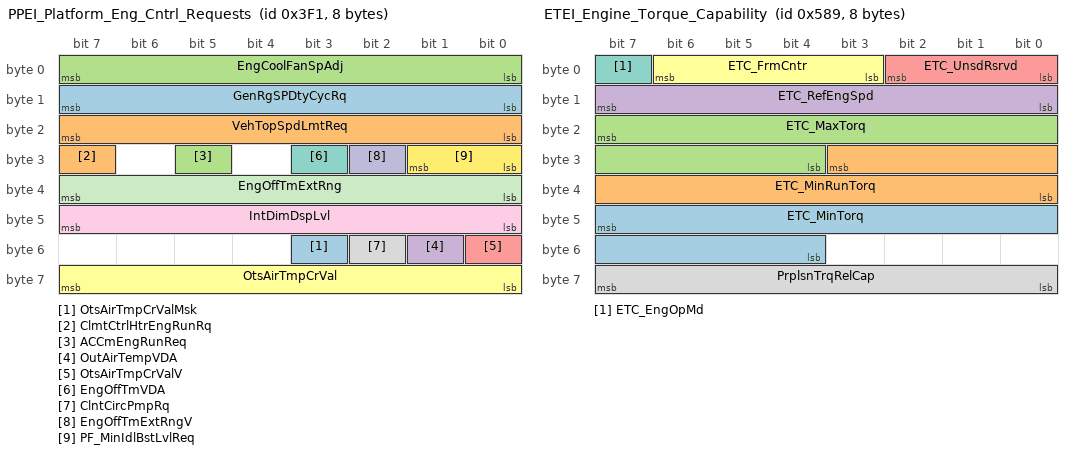
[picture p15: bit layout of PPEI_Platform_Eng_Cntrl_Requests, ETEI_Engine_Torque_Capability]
BO_ 1009 PPEI_Platform_Eng_Cntrl_Requests: 8 HSCU
 SG_ OtsAirTmpCrValMsk : 51|1@0+ (1,0) [0|1] ""  DECM
 SG_ ClmtCtrlHtrEngRunRq : 31|1@0+ (1,0) [0|1] ""  DECM
 SG_ ACCmEngRunReq : 29|1@0+ (1,0) [0|1] ""  DECM
 SG_ OutAirTempVDA : 49|1@0+ (1,0) [0|1] ""  DECM
 SG_ OtsAirTmpCrValV : 48|1@0+ (1,0) [0|1] ""  DECM
 SG_ OtsAirTmpCrVal : 63|8@0+ (0.5,-40) [-40|87.5] "deg C"  DECM
 SG_ EngOffTmVDA : 27|1@0+ (1,0) [0|1] ""  DECM
 SG_ ClntCircPmpRq : 50|1@0+ (1,0) [0|1] ""  DECM
 SG_ IntDimDspLvl : 47|8@0+ (0.392157,0) [0|100.000035] "%"  DECM
 SG_ EngOffTmExtRngV : 26|1@0+ (1,0) [0|1] ""  DECM
 SG_ EngOffTmExtRng : 39|8@0+ (4,0) [0|1020] "min"  DECM
 SG_ PF_MinIdlBstLvlReq : 25|2@0+ (1,0) [0|3] ""  DECM
 SG_ GenRgSPDtyCycRq : 15|8@0+ (0.392157,0) [0|100.000035] "%"  DECM
 SG_ VehTopSpdLmtReq : 23|8@0+ (2,0) [0|510] "km / h"  DECM
 SG_ EngCoolFanSpAdj : 7|8@0- (0.78125,0) [-100|99.21875] "%"  DECM

BO_ 1019 PPEI_Engine_Fuel_Status: 2 DECM
 SG_ FuelAlchlCompAdptnPrg : 4|1@0+ (1,0) [0|1] ""  HSCU
 SG_ FuelLvlEmnsRelStat : 5|1@0+ (1,0) [0|1] ""  HSCU
 SG_ EmnsRelFuelLvlLw : 6|1@0+ (1,0) [0|1] ""  HSCU
 SG_ EngFuelCntlState : 1|2@0+ (1,0) [0|3] ""  HSCU
 SG_ FuelAlcoholCompV : 7|1@0+ (1,0) [0|1] ""  HSCU
 SG_ FuelAlcoholComp : 15|8@0+ (0.392157,0) [0|100.000035] "%"  HSCU

BO_ 1417 ETEI_Engine_Torque_Capability: 8 DECM
 SG_ ETC_MinTorq : 47|12@0+ (0.5,-848) [-848|1199.5] "Nm"  HSCU
 SG_ ETC_MinRunTorq : 27|12@0+ (0.5,-848) [-848|1199.5] "Nm"  HSCU
 SG_ ETC_MaxTorq : 23|12@0+ (0.5,-848) [-848|1199.5] "Nm"  HSCU
 SG_ ETC_RefEngSpd : 15|8@0+ (32,0) [0|8160] "rpm"  HSCU
 SG_ ETC_UnsdRsrvd : 2|3@0+ (1,0) [0|7] ""  HSCU
 SG_ ETC_FrmCntr : 6|4@0+ (1,0) [0|15] ""  HSCU
 SG_ ETC_EngOpMd : 7|1@0+ (1,0) [0|1] ""  HSCU
 SG_ PrplsnTrqRelCap : 63|8@0+ (0.5,0) [0|127.5] "%"  HSCU

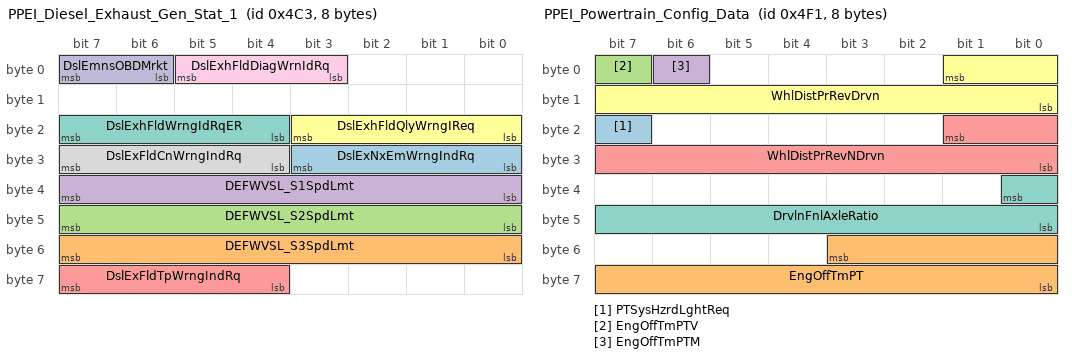
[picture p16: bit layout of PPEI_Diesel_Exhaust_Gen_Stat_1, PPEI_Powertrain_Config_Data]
BO_ 1219 PPEI_Diesel_Exhaust_Gen_Stat_1: 8 DECM
 SG_ DslExNxEmWrngIndRq : 27|4@0+ (1,0) [0|15] ""  HSCU
 SG_ DEFWVSL_S3SpdLmt : 55|8@0+ (1,0) [0|255] "km / h"  HSCU
 SG_ DEFWVSL_S2SpdLmt : 47|8@0+ (1,0) [0|255] "km / h"  HSCU
 SG_ DEFWVSL_S1SpdLmt : 39|8@0+ (1,0) [0|255] "km / h"  HSCU
 SG_ DslExFldTpWrngIndRq : 63|4@0+ (1,0) [0|15] ""  HSCU
 SG_ DslExhFldQlyWrngIReq : 19|4@0+ (1,0) [0|15] ""  HSCU
 SG_ DslExhFldWrngIdRqER : 23|4@0+ (1,0) [0|15] ""  HSCU
 SG_ DslExFldCnWrngIndRq : 31|4@0+ (1,0) [0|15] ""  HSCU
 SG_ DslExhFldDiagWrnIdRq : 5|3@0+ (1,0) [0|7] ""  HSCU
 SG_ DslEmnsOBDMrkt : 7|2@0+ (1,0) [0|3] ""  HSCU

BO_ 1265 PPEI_Powertrain_Config_Data: 8 DECM
 SG_ PTSysHzrdLghtReq : 23|1@0+ (1,0) [0|1] ""  HSCU
 SG_ EngOffTmPT : 51|12@0+ (0.5,0) [0|2047.5] "min"  HSCU
 SG_ EngOffTmPTV : 7|1@0+ (1,0) [0|1] ""  HSCU
 SG_ EngOffTmPTM : 6|1@0+ (1,0) [0|1] ""  HSCU
 SG_ WhlDistPrRevNDrvn : 17|10@0+ (3,800) [800|3869] "mm"  HSCU
 SG_ WhlDistPrRevDrvn : 1|10@0+ (3,800) [800|3869] "mm"  HSCU
 SG_ DrvlnFnlAxleRatio : 32|9@0+ (0.01,2) [2|7.11] ""  HSCU

BO_ 1267 PPEI_Powertrain_Config_Data_2: 1 DECM
 SG_ VehMassNom : 7|8@0+ (20,500) [500|5600] "kg"  HSCU

BO_ 1231 PPEI_Diesel_Exhaust_Gen_Stat_2: 3 DECM
 SG_ DslExhFluidDistTIndcmt : 14|15@0+ (2,0) [0|65534] "km"  HSCU
 SG_ DslExhFluidLvlPrcntV : 15|1@0+ (1,0) [0|1] ""  HSCU
 SG_ DslExhFluidLvlPrcnt : 7|8@0+ (0.392157,0) [0|100.000035] "%"  HSCU

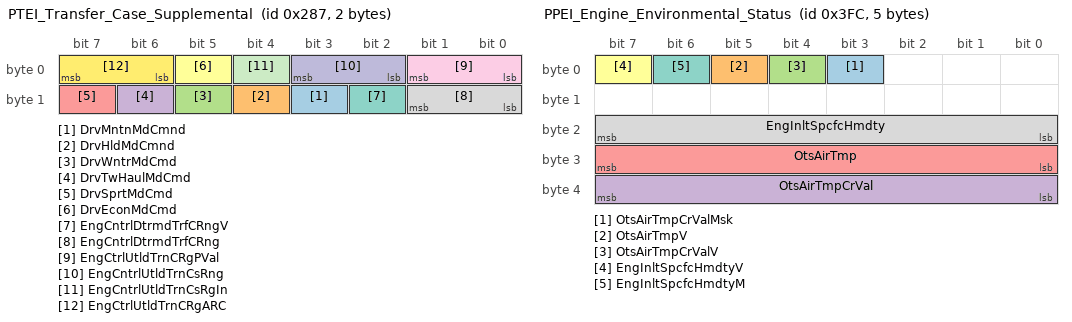
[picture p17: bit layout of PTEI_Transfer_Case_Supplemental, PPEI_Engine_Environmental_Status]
BO_ 647 PTEI_Transfer_Case_Supplemental: 2 DECM
 SG_ DrvMntnMdCmnd : 11|1@0+ (1,0) [0|1] ""  HSCU
 SG_ DrvHldMdCmnd : 12|1@0+ (1,0) [0|1] ""  HSCU
 SG_ DrvWntrMdCmd : 13|1@0+ (1,0) [0|1] ""  HSCU
 SG_ DrvTwHaulMdCmd : 14|1@0+ (1,0) [0|1] ""  HSCU
 SG_ DrvSprtMdCmd : 15|1@0+ (1,0) [0|1] ""  HSCU
 SG_ DrvEconMdCmd : 5|1@0+ (1,0) [0|1] ""  HSCU
 SG_ EngCntrlDtrmdTrfCRngV : 10|1@0+ (1,0) [0|1] ""  HSCU
 SG_ EngCntrlDtrmdTrfCRng : 9|2@0+ (1,0) [0|3] ""  HSCU
 SG_ EngCtrlUtldTrnCRgPVal : 1|2@0+ (1,0) [0|3] ""  HSCU
 SG_ EngCntrlUtldTrnCsRng : 3|2@0+ (1,0) [0|3] ""  HSCU
 SG_ EngCntrlUtldTrnCsRgIn : 4|1@0+ (1,0) [0|1] ""  HSCU
 SG_ EngCtrlUtldTrnCRgARC : 7|2@0+ (1,0) [0|3] ""  HSCU

BO_ 723 Prfrmnc_Trctn_Cntrl_Eng_Stat_HS: 2 DECM
 SG_ PerfTrcEngSpdRqStat : 10|3@0+ (1,0) [0|7] ""  HSCU
 SG_ PerfTrcEngSpdLmtStat : 12|2@0+ (1,0) [0|3] ""  HSCU
 SG_ PerfTrcTrqRqStat : 2|3@0+ (1,0) [0|7] ""  HSCU
 SG_ PerfTrcTrqLmtStat : 4|2@0+ (1,0) [0|3] ""  HSCU

BO_ 961 PPEI_Powertrain_Immobilizer_Data: 8 DECM
 SG_ PTImmblzerInfo : 7|64@0+ (1,0) [0|1.844674407371E+019] ""  HSCU

BO_ 1020 PPEI_Engine_Environmental_Status: 5 DECM
 SG_ OtsAirTmpCrValMsk : 3|1@0+ (1,0) [0|1] ""  HSCU
 SG_ OtsAirTmpV : 5|1@0+ (1,0) [0|1] ""  HSCU
 SG_ OtsAirTmpCrValV : 4|1@0+ (1,0) [0|1] ""  HSCU
 SG_ OtsAirTmpCrVal : 39|8@0+ (0.5,-40) [-40|87.5] "deg C"  HSCU
 SG_ OtsAirTmp : 31|8@0+ (0.5,-40) [-40|87.5] "deg C"  HSCU
 SG_ EngInltSpcfcHmdtyV : 7|1@0+ (1,0) [0|1] ""  HSCU
 SG_ EngInltSpcfcHmdtyM : 6|1@0+ (1,0) [0|1] ""  HSCU
 SG_ EngInltSpcfcHmdty : 23|8@0+ (0.0196078,0) [0|4.999989] "% water"  HSCU

BO_ 1512 UUDT_Resp_From_ECM: 8 DECM
 SG_ DgnInf : 7|64@0+ (1,0) [0|1.844674407371E+019] ""  HSCU

BO_ 2024 USDT_Resp_From_ECM_HS: 8 DECM
 SG_ pid_LB : 24|8@1+ (1,0) [0|255] "" Vector__XXX
 SG_ pid_HB : 16|8@1+ (1,0) [0|0] "" Vector__XXX
 SG_ pid_V : 8|8@1+ (1,0) [0|0] "" Vector__XXX
 SG_ DgnInf : 39|16@0+ (1,0) [0|65535] "0"  HSCU

BO_ 257 USDT_Req_to_All_HS_ECUs: 8 HSCU
 SG_ DgnInf : 7|64@0+ (1,0) [0|1.844674407371E+019] ""  HSCU

BO_ 468 Accessory_Pwr_Mod_LV_cmds: 8 HSCU
 SG_ APM_LV_setpoint_cmd : 15|8@0+ (0.0784313725490196,0) [0|20] "volts"  DCDC
 SG_ APM_LV_enable_request : 7|1@0+ (1,0) [0|1] "boolean"  DCDC

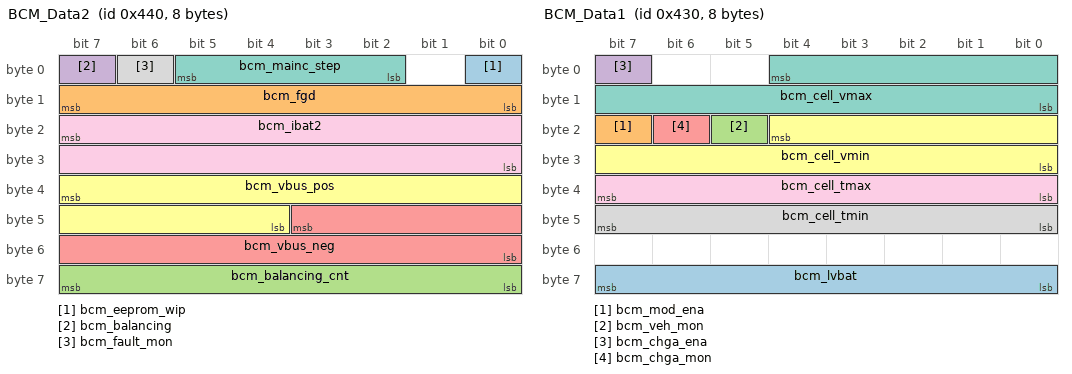
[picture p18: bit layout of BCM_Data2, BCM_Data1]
BO_ 1088 BCM_Data2: 8 BCM
 SG_ bcm_eeprom_wip : 0|1@0+ (1,0) [0|1] "flag"  HSCU
 SG_ bcm_fgd : 15|8@0+ (0.5,0) [0|100] "% Duty Cycle"  HSCU
 SG_ bcm_balancing_cnt : 63|8@0+ (1,0) [0|250] "cells"  HSCU
 SG_ bcm_balancing : 7|1@0+ (1,0) [0|1] "flag"  HSCU
 SG_ bcm_vbus_neg : 43|12@0+ (0.25,-500) [-500|500] "volts"  HSCU
 SG_ bcm_vbus_pos : 39|12@0+ (0.25,0) [0|1000] "volts"  HSCU
 SG_ bcm_mainc_step : 5|4@0+ (1,0) [0|15] "enum"  HSCU
 SG_ bcm_fault_mon : 6|1@0+ (1,0) [0|1] "flag"  HSCU
 SG_ bcm_ibat2 : 23|16@0+ (0.025,-1000) [-1000|500] "amps"  HSCU

BO_ 1072 BCM_Data1: 8 BCM
 SG_ bcm_lvbat : 63|8@0+ (0.1,0) [0|25] "Volts"  HSCU
 SG_ bcm_mod_ena : 23|1@0+ (1,0) [0|1] "flag"  HSCU
 SG_ bcm_veh_mon : 21|1@0+ (1,0) [0|1] "flag"  HSCU
 SG_ bcm_chga_ena : 7|1@0+ (1,0) [0|1] "flag"  HSCU
 SG_ bcm_chga_mon : 22|1@0+ (1,0) [0|1] "flag"  HSCU
 SG_ bcm_cell_vmin : 20|13@0+ (0.001,0) [0|5] "volts"  HSCU
 SG_ bcm_cell_vmax : 4|13@0+ (0.001,0) [0|5] "volts"  HSCU
 SG_ bcm_cell_tmin : 47|8@0+ (0.5,-40) [-40|85] "DegC"  HSCU
 SG_ bcm_cell_tmax : 39|8@0+ (0.5,-40) [-40|85] "DegC"  HSCU

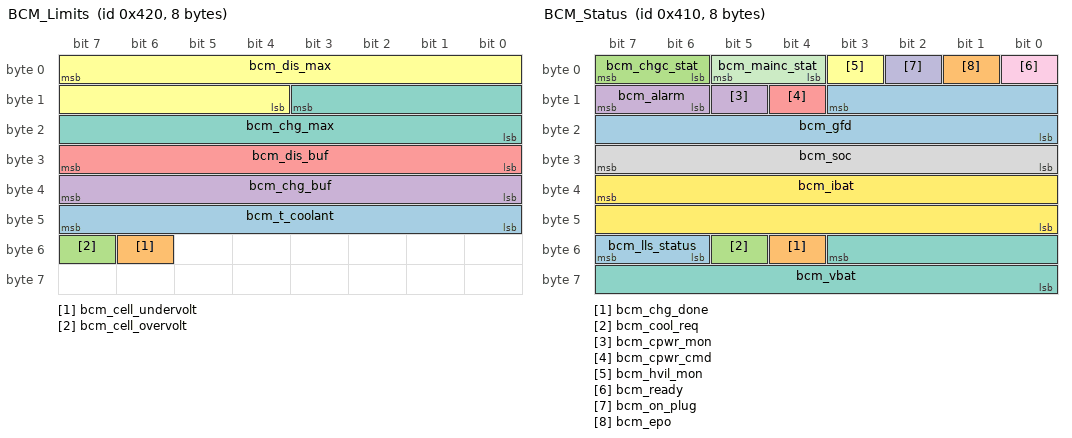
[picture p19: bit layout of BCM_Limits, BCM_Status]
BO_ 1056 BCM_Limits: 8 BCM
 SG_ bcm_t_coolant : 47|8@0+ (0.5,-40) [-40|85] "DegC"  HSCU
 SG_ bcm_cell_undervolt : 54|1@0+ (1,0) [0|1] "flag"  HSCU
 SG_ bcm_cell_overvolt : 55|1@0+ (1,0) [0|1] "flag"  HSCU
 SG_ bcm_chg_buf : 39|8@0+ (0.5,0) [0|100] "%"  HSCU
 SG_ bcm_dis_buf : 31|8@0+ (0.5,0) [0|100] "%"  HSCU
 SG_ bcm_dis_max : 7|12@0+ (0.25,0) [0|1000] "amps"  HSCU
 SG_ bcm_chg_max : 11|12@0+ (0.25,0) [0|1000] "amps"  HSCU

BO_ 1040 BCM_Status: 8 BCM
 SG_ bcm_lls_status : 55|2@0+ (1,0) [0|3] "state"  HSCU
 SG_ bcm_chg_done : 52|1@0+ (1,0) [0|1] "flag"  HSCU
 SG_ bcm_cool_req : 53|1@0+ (1,0) [0|1] "flag"  HSCU
 SG_ bcm_cpwr_mon : 13|1@0+ (1,0) [0|1] "flag"  HSCU
 SG_ bcm_cpwr_cmd : 12|1@0+ (1,0) [0|1] "flag"  HSCU
 SG_ bcm_hvil_mon : 3|1@0+ (1,0) [0|1] "flag"  HSCU
 SG_ bcm_vbat : 51|12@0+ (0.25,0) [0|1000] "volts"  HSCU
 SG_ bcm_soc : 31|8@0+ (0.5,0) [0|100] "%"  HSCU
 SG_ bcm_ready : 0|1@0+ (1,0) [0|1] "flag"  HSCU
 SG_ bcm_on_plug : 2|1@0+ (1,0) [0|1] "flag"  HSCU
 SG_ bcm_mainc_stat : 5|2@0+ (1,0) [0|2] "enum"  HSCU
 SG_ bcm_ibat : 39|16@0+ (0.025,-1000) [-1000|500] "amps"  HSCU
 SG_ bcm_gfd : 11|12@0+ (0.25,0) [0|1000] "kOhm"  HSCU
 SG_ bcm_epo : 1|1@0+ (1,0) [0|1] "flag"  HSCU
 SG_ bcm_chgc_stat : 7|2@0+ (1,0) [0|2] "enum"  HSCU
 SG_ bcm_alarm : 15|2@0+ (1,0) [0|3] "enum"  HSCU

BO_ 1024 BCM_Request: 4 HSCU
 SG_ hsc_bcm_mainc_close : 2|1@0+ (1,0) [0|1] "flag"  BCM
 SG_ hsc_bcm_leakage_ena : 3|1@0+ (1,0) [0|1] "flag"  BCM
 SG_ hsc_bcm_epo : 1|1@0+ (1,0) [0|1] "flag"  BCM
 SG_ hsc_bcm_enable : 0|1@0+ (1,0) [0|1] "flag"  BCM

BO_ 1120 BCM_Faults: 8 BCM
 SG_ bcm_dtc_type3 m0 : 47|8@0+ (1,0) [0|255] "DTCs"  HSCU
 SG_ bcm_dtc_type2 m0 : 39|8@0+ (1,0) [0|255] "DTCs"  HSCU
 SG_ bcm_dtc_type1 m0 : 31|8@0+ (1,0) [0|255] "DTCs"  HSCU
 SG_ bcm_dtc_testFailedThisOpCycle m0 : 55|8@0+ (1,0) [0|255] "DTCs"  HSCU
 SG_ bcm_dtc_pages m0 : 23|8@0+ (1,0) [0|255] "page count"  HSCU
 SG_ bcm_dtc_fault_detected m0 : 63|8@0+ (1,0) [0|255] "DTCs"  HSCU
 SG_ bcm_dtc_001 m1 : 23|24@0+ (1,0) [0|16777215] "DTC ID"  HSCU
 SG_ bcm_dtc_002 m1 : 47|24@0+ (1,0) [0|16777215] "DTC ID"  HSCU
 SG_ bcm_dtc_003 m2 : 23|24@0+ (1,0) [0|16777215] "DTC ID"  HSCU
 SG_ bcm_dtc_004 m2 : 47|24@0+ (1,0) [0|16777215] "DTC ID"  HSCU
 SG_ bcm_dtc_005 m3 : 23|24@0+ (1,0) [0|16777215] "DTC ID"  HSCU
 SG_ bcm_dtc_006 m3 : 47|24@0+ (1,0) [0|16777215] "DTC ID"  HSCU
 SG_ bcm_dtc_007 m4 : 23|24@0+ (1,0) [0|16777215] "DTC ID"  HSCU
 SG_ bcm_dtc_008 m4 : 47|24@0+ (1,0) [0|16777215] "DTC ID"  HSCU
 SG_ bcm_dtc_page M : 7|8@0+ (1,0) [0|255] "page number"  HSCU

CM_ BU_ HSCU "UW Hybrid Supervisory Control Unit (MABx II)";
CM_ BU_ BCM "Battery Control Module";
CM_ BU_ RINE "Motor Controller (RMS PM150DX)";
CM_ BU_ BRUSA "Battery Charger (NLG5)";
CM_ BU_ DCDC "DC/DC Converter (GM APM)";
CM_ BO_ 3221225472 "This is a message for not used signals, created by Vector CANdb++ DBC OLE DB Provider.";
CM_ SG_ 1961 Upstream_NOx "0 ppm +/- 15";
CM_ SG_ 1958 Upstream_NOx "0 ppm +/- 15";
CM_ SG_ 1956 UW_Motor_Torque "Estimated motor torque feedback";
CM_ SG_ 1956 UW_Motor_Speed "The measured speed of the motor";
CM_ SG_ 1957 UW_BRUSA_AC_I "Actual mains current";
CM_ SG_ 1957 UW_BRUSA_AC_V "Actual mains voltage";
CM_ SG_ 1955 UW_Motor_Temperature "Motor Temperature Sensor";
CM_ SG_ 1954 UW_ESS_SOC "Battery State of Charge.";
CM_ SG_ 1954 UW_ESS_cell_tmax "Max cell case temperature.";
CM_ SG_ 1954 UW_ESS_vbat "HV Battery voltage measurement.";
CM_ SG_ 1954 UW_ESS_ibat "HV Battery Current where negative is battery discharge and positive is battery charge.";
CM_ SG_ 1088 bcm_eeprom_wip "BCM fault status: EEPROM write in progress.";
CM_ SG_ 1088 bcm_fgd "Flammable gas detector duty cycle (most severe).";
CM_ SG_ 1088 bcm_balancing_cnt "Number of cells currently balancing.";
CM_ SG_ 1088 bcm_balancing "Charge balance circuits are active.";
CM_ SG_ 1088 bcm_vbus_neg "HV bus negative voltage measurement.";
CM_ SG_ 1088 bcm_vbus_pos "HV bus positive voltage measurement.";
CM_ SG_ 1088 bcm_mainc_step "Main contactor control state enumeration.";
CM_ SG_ 1088 bcm_fault_mon "Module Fault monitor, indicates if of the modules triggered a hardware based fault (0=low, 1=high).";
CM_ SG_ 1088 bcm_ibat2 "[Development Sensor] HV Battery Current where negative is battery discharge and positive is battery charge.";
CM_ SG_ 1072 bcm_lvbat "SLI Battery Voltage.";
CM_ SG_ 1072 bcm_mod_ena "Module 12V enable command (0=off, 1=on).";
CM_ SG_ 1072 bcm_veh_mon "Vehicle wakeup monitor (0=low, 1=high).";
CM_ SG_ 1072 bcm_chga_ena "Charger enable command (0=off, 1=on).";
CM_ SG_ 1072 bcm_chga_mon "Charger AC wakeup monitor (0=low, 1=high).";
CM_ SG_ 1072 bcm_cell_vmin "Min cell voltage.";
CM_ SG_ 1072 bcm_cell_vmax "Max cell voltage.";
CM_ SG_ 1072 bcm_cell_tmin "Min cell case temperature.";
CM_ SG_ 1072 bcm_cell_tmax "Max cell case temperature.";
CM_ SG_ 1056 bcm_t_coolant "Battery coolant temperature sensor value.";
CM_ SG_ 1056 bcm_cell_undervolt "One or more cells are below normal voltage range.";
CM_ SG_ 1056 bcm_cell_overvolt "One or more cells are above normal voltage range.";
CM_ SG_ 1056 bcm_chg_buf "Transient acceptance indicator, how soon before the BCM will start to limit it's max charge current.
100% - large buffer to accept charge up to bcm_chg_max.
0% - bcm_chg_max is being reduced to steady-state level.";
CM_ SG_ 1056 bcm_dis_buf "Transient acceptance indicator, how soon before the BCM will start to limit it's max discharge current.
100% - large buffer to accept discharge up to bcm_dis_max.
0% - bcm_dis_max is being reduced to steady-state level.";
CM_ SG_ 1056 bcm_dis_max "Max allowed discharge current.";
CM_ SG_ 1056 bcm_chg_max "Max allowed charge current.";
CM_ SG_ 1040 bcm_lls_status "Liquid level sensor located mid-pack.  FAULT indicates that Liquid was detected within the pack.";
CM_ SG_ 1040 bcm_chg_done "Charging is complete.";
CM_ SG_ 1040 bcm_cool_req "Battey cell temperaure indicates cooling required, the vehicle should activate the cooling pump and target bcm_t_coolant <= 20C.";
CM_ SG_ 1040 bcm_cpwr_mon "Contactor Power Relay monitor (0=low, 1=high).";
CM_ SG_ 1040 bcm_cpwr_cmd "Contactor Power Relay command state (0=off, 1=on).";
CM_ SG_ 1040 bcm_hvil_mon "HVIL monitor (0=low, 1=high).";
CM_ SG_ 1040 bcm_vbat "HV Battery voltage measurement.";
CM_ SG_ 1040 bcm_soc "Battery State of Charge.";
CM_ SG_ 1040 bcm_ready "BCM completed Power On Self Test and is ready.";
CM_ SG_ 1040 bcm_on_plug "Charger is plugged into AC socket, use an an input to start/drive-away logic.";
CM_ SG_ 1040 bcm_mainc_stat "Main contactor status.";
CM_ SG_ 1040 bcm_ibat "HV Battery Current where negative is battery discharge and positive is battery charge.";
CM_ SG_ 1040 bcm_gfd "Ground fault detection result.";
CM_ SG_ 1040 bcm_epo "BCM Emergency Power Off status.";
CM_ SG_ 1040 bcm_chgc_stat "Charge contactor status.";
CM_ SG_ 1040 bcm_alarm "Alarm condition from the BCM indicating overall condition.";
CM_ SG_ 1024 hsc_bcm_mainc_close "Vehicle main contactor command.";
CM_ SG_ 1024 hsc_bcm_leakage_ena "Vehicle leakage detection enabled (bcm_gfd calculation).";
CM_ SG_ 1024 hsc_bcm_epo "Vehicle Emergency Power Off command, fast shutdown.";
CM_ SG_ 1024 hsc_bcm_enable "Flag from vehicle controller allowing BCM to accept commands.";
BA_DEF_ SG_  "GenSigStartValue" INT 0 0;
BA_DEF_ BO_  "GenMsgCycleTime" INT 0 1000;
BA_DEF_  "BusType" STRING ;
BA_DEF_ SG_  "SystemSignalLongSymbol" STRING ;
BA_DEF_DEF_  "GenSigStartValue" 0;
BA_DEF_DEF_  "GenMsgCycleTime" 100;
BA_DEF_DEF_  "BusType" "CAN";
BA_DEF_DEF_  "SystemSignalLongSymbol" "";
BA_ "GenMsgCycleTime" BO_ 1961 1000;
BA_ "GenMsgCycleTime" BO_ 1953 1000;
BA_ "GenMsgCycleTime" BO_ 1223 500;
BA_ "GenMsgCycleTime" BO_ 241 10;
BA_ "GenMsgCycleTime" BO_ 1005 250;
BA_ "GenMsgCycleTime" BO_ 1105 25;
BA_ "GenMsgCycleTime" BO_ 419 25;
BA_ "GenMsgCycleTime" BO_ 1249 1000;
BA_ "GenMsgCycleTime" BO_ 1221 500;
BA_ "GenMsgCycleTime" BO_ 1906 1000;
BA_ "GenMsgCycleTime" BO_ 500 25;
BA_ "GenMsgCycleTime" BO_ 707 50;
BA_ "GenMsgCycleTime" BO_ 417 25;
BA_ "GenMsgCycleTime" BO_ 401 12;
BA_ "GenMsgCycleTime" BO_ 479 25;
BA_ "GenMsgCycleTime" BO_ 393 25;
BA_ "GenMsgCycleTime" BO_ 190 12;
BA_ "GenMsgCycleTime" BO_ 453 25;
BA_ "GenMsgCycleTime" BO_ 1257 1000;
BA_ "GenMsgCycleTime" BO_ 721 50;
BA_ "GenMsgCycleTime" BO_ 431 25;
BA_ "GenMsgCycleTime" BO_ 413 25;
BA_ "GenMsgCycleTime" BO_ 719 50;
BA_ "GenMsgCycleTime" BO_ 717 50;
BA_ "GenMsgCycleTime" BO_ 715 50;
BA_ "GenMsgCycleTime" BO_ 409 25;
BA_ "GenMsgCycleTime" BO_ 505 30;
BA_ "GenMsgCycleTime" BO_ 499 30;
BA_ "GenMsgCycleTime" BO_ 490 12;
BA_ "GenMsgCycleTime" BO_ 460 20;
BA_ "GenMsgCycleTime" BO_ 459 20;
BA_ "GenMsgCycleTime" BO_ 405 12;
BA_ "GenMsgCycleTime" BO_ 485 10;
BA_ "GenMsgCycleTime" BO_ 201 12;
BA_ "GenMsgCycleTime" BO_ 1017 250;
BA_ "GenMsgCycleTime" BO_ 1217 500;
BA_ "GenMsgCycleTime" BO_ 1233 500;
BA_ "GenMsgCycleTime" BO_ 398 12;
BA_ "GenMsgCycleTime" BO_ 442 25;
BA_ "GenMsgCycleTime" BO_ 451 25;
BA_ "GenMsgCycleTime" BO_ 452 25;
BA_ "GenMsgCycleTime" BO_ 489 20;
BA_ "GenMsgCycleTime" BO_ 761 50;
BA_ "GenMsgCycleTime" BO_ 249 12;
BA_ "GenMsgCycleTime" BO_ 501 25;
BA_ "GenMsgCycleTime" BO_ 1225 500;
BA_ "GenMsgCycleTime" BO_ 1241 500;
BA_ "GenMsgCycleTime" BO_ 1009 250;
BA_ "GenMsgCycleTime" BO_ 1019 250;
BA_ "GenMsgCycleTime" BO_ 1417 500;
BA_ "GenMsgCycleTime" BO_ 1219 1000;
BA_ "GenMsgCycleTime" BO_ 1265 1000;
BA_ "GenMsgCycleTime" BO_ 1267 1000;
BA_ "GenMsgCycleTime" BO_ 1231 1000;
BA_ "GenMsgCycleTime" BO_ 647 25;
BA_ "GenMsgCycleTime" BO_ 723 50;
BA_ "GenMsgCycleTime" BO_ 1020 250;
BA_ "GenMsgCycleTime" BO_ 1088 50;
BA_ "GenMsgCycleTime" BO_ 1072 50;
BA_ "GenMsgCycleTime" BO_ 1040 50;
BA_ "GenMsgCycleTime" BO_ 1024 10;
BA_ "GenSigStartValue" SG_ 3221225472 TorqueRequestValue 800;
BA_ "GenSigStartValue" SG_ 3221225472 EngineTorqueMin 800;
BA_ "GenSigStartValue" SG_ 3221225472 EngineTorqueMax 800;
BA_ "GenSigStartValue" SG_ 3221225472 EngineTorqueDriverReq 800;
BA_ "GenSigStartValue" SG_ 3221225472 EngineTorqueActual 800;
BA_ "GenSigStartValue" SG_ 1961 NOxDifference 4000;
BA_ "GenSigStartValue" SG_ 1961 Downstream_NOx 4000;
BA_ "GenSigStartValue" SG_ 1961 Upstream_NOx 4000;
BA_ "GenSigStartValue" SG_ 1958 Upstream_NOx 4000;
BA_ "GenSigStartValue" SG_ 1958 Downstream_NOx 4000;
BA_ "GenSigStartValue" SG_ 1954 UW_ESS_cell_tmax 130;
BA_ "GenSigStartValue" SG_ 719 RVBATC_AxTrqReq 11267;
BA_ "GenSigStartValue" SG_ 468 APM_LV_setpoint_cmd 172;
BA_ "GenSigStartValue" SG_ 1072 bcm_cell_tmin 130;
BA_ "GenSigStartValue" SG_ 1072 bcm_cell_tmax 130;
VAL_ 3221225472 PgVehTheftDetNonImVirtDevAva 0 "Virtual Device Unavailable" 1 "Virtual Device Available" ;
VAL_ 3221225472 PgTractionControlSysPresent 1 "true" 0 "false" ;
VAL_ 3221225472 PgThrottleProgReq 0 "Map A" 1 "Map B" 2 "Map C" ;
VAL_ 3221225472 PgSystemPowerMode 0 "Off" 1 "Accessory" 2 "Run" 3 "Crank Request" ;
VAL_ 3221225472 PgSysBackupPowerModeEnabled 1 "true" 0 "false" ;
VAL_ 3221225472 PgSysBackupPowerMode 0 "Off" 1 "Accessory" 2 "Run" 3 "Crank Request" ;
VAL_ 3221225472 PgrealTimeDampSysPresent 1 "true" 0 "false" ;
VAL_ 3221225472 PgPowerModeMstrRunCrankTermStat 0 "Inactive" 1 "Active" ;
VAL_ 3221225472 PgPowerModeMstrAccTermStatus 0 "Inactive" 1 "Active" ;
VAL_ 3221225472 PgParkBrakeSwAct 1 "true" 0 "false" ;
VAL_ 3221225472 PgManTransrevGearActV 1 "Invalid" 0 "Valid" ;
VAL_ 3221225472 PgManTransRevGearAct 1 "true" 0 "false" ;
VAL_ 3221225472 PgManTranRevGearSwVDevAv 0 "Virtual Device Unavailable" 1 "Virtual Device Available" ;
VAL_ 3221225472 PgEngOilLifeResetReq 1 "true" 0 "false" ;
VAL_ 3221225472 PgEngCoolLevSwVirtDevAva 0 "Virtual Device Unavailable" 1 "Virtual Device Available" ;
VAL_ 3221225472 PgEngCoolLevLow 1 "true" 0 "false" ;
VAL_ 3221225472 PgEnergyMngmtMinIdleBoostLevReq 0 "No Boost Requested" 1 "Boost Level 1" 2 "Boost Level 2" 3 "Boost Level 3" ;
VAL_ 3221225472 PgCruiseControlSwFail 1 "true" 0 "false" ;
VAL_ 3221225472 PgCruiseControlSetSwAct 1 "true" 0 "false" ;
VAL_ 3221225472 PgCruiseControlResSwAct 1 "true" 0 "false" ;
VAL_ 3221225472 PgCruiseControlOnSwAct 1 "true" 0 "false" ;
VAL_ 3221225472 PgCruiseControlCancelReq 1 "Cancel" 0 "Do not cancel" ;
VAL_ 3221225472 PgClimateContVirtDevAva 0 "Virtual Device Unavailable" 1 "Virtual Device Available" ;
VAL_ 3221225472 PgBackupPowerModeMstrVirtDevAva 0 "Virtual Device Unavailable" 1 "Virtual Device Available" ;
VAL_ 3221225472 PgAntilockBrakeSysPresent 1 "true" 0 "false" ;
VAL_ 3221225472 PgAirCondCompPresent 1 "true" 0 "false" ;
VAL_ 3221225472 PgAirCondCompClutchReq 0 "No Action" 1 "Engage" 2 "Disengage" 3 "Disengage Immediately" ;
VAL_ 3221225472 PgAirbagVirtDevAva 0 "Virtual Device Unavailable" 1 "Virtual Device Available" ;
VAL_ 3221225472 PgAirbagDep 1 "true" 0 "false" ;
VAL_ 3221225472 VehicleStabEnhanceSysSpdLimAct 1 "true" 0 "false" ;
VAL_ 3221225472 TractionControlSysFailed 1 "true" 0 "false" ;
VAL_ 3221225472 BrakePedalDriveAppPresDet 1 "true" 0 "false" ;
VAL_ 3221225472 BrakePedalDrivAppPresDetV 0 "Valid" 1 "Invalid" ;
VAL_ 3221225472 SuspensionSysDampFailFullSoft 1 "true" 0 "false" ;
VAL_ 3221225472 VehicleDynamicControlActive 1 "true" 0 "false" ;
VAL_ 3221225472 TractionCntrlSysEnable 1 "true" 0 "false" ;
VAL_ 3221225472 TractionCntrlSysActive 1 "true" 0 "false" ;
VAL_ 3221225472 AntilockBrakeSysFailed 1 "true" 0 "false" ;
VAL_ 3221225472 AntilockBrakeSysActive 1 "true" 0 "false" ;
VAL_ 3221225472 WheelSpeedSensDiagComplete 1 "true" 0 "false" ;
VAL_ 3221225472 WheelAvgP2PAccelV 0 "Valid" 1 "Invalid" ;
VAL_ 3221225472 TractionTrqDecayCtrlActive 1 "true" 0 "false" ;
VAL_ 3221225472 WheelAngVelocityRearRightV 0 "Valid" 1 "Invalid" ;
VAL_ 3221225472 WheelAngVelocityRearLeftV 0 "Valid" 1 "Invalid" ;
VAL_ 3221225472 WheelAngVelocityFrontRightV 0 "Valid" 1 "Invalid" ;
VAL_ 3221225472 WheelAngVelocityFrontLeftV 0 "Valid" 1 "Invalid" ;
VAL_ 3221225472 SteeringWheelAngleV 1 "Invalid" 0 "Valid" ;
VAL_ 3221225472 SteeringWheelAngleGradV 1 "Invalid" 0 "Valid" ;
VAL_ 3221225472 VehicleDynLateralAccV 0 "Valid" 1 "Invalid" ;
VAL_ 3221225472 TractionTrqDecayEnable 0 "False" 1 "True" ;
VAL_ 3221225472 TractionControlTrqReqV 0 "Valid" 1 "Invalid" ;
VAL_ 3221225472 TorqueReductionRealizSuggestion 0 "No Suggestion" 1 "No Throttle Usage" 2 "Throttle Only" ;
VAL_ 3221225472 TorqueInterventionType 0 "No Intervention" 1 "Reduce Torque" 2 "Increase Torque" ;
VAL_ 3221225472 BrakePedalPosFailure 0 "Brake Position Sensing Valid" 1 "Brake Position Sensing Invalid" ;
VAL_ 3221225472 BrakePedalModerateTravelAch 0 "False" 1 "True" ;
VAL_ 3221225472 BrakePedalInitTravelAch 0 "False" 1 "True" ;
VAL_ 3221225472 VehicleLiftDiveStatusV 0 "Valid" 1 "Invalid" ;
VAL_ 3221225472 VehicleLiftDiveStatus 0 "Neutral" 1 "Lift" 2 "Dive" ;
VAL_ 3221225472 EngineTrqTractContReqFail 0 "False" 1 "True" ;
VAL_ 3221225472 EngineTorqueReductFailStat 0 "Torque Reduction OK" 1 "Torque Reduction Temporarily Failed" 2 "Torque Reduction Permanently Failed" 3 "Torque Reduction Limited" ;
VAL_ 3221225472 EngineTorqueMinV 0 "Valid" 1 "Invalid" ;
VAL_ 3221225472 EngineTorqueMaxV 0 "Valid" 1 "Invalid" ;
VAL_ 3221225472 EngineTorqueDriverReqV 0 "Valid" 1 "Invalid" ;
VAL_ 3221225472 EngineTorqueActualV 0 "Valid" 1 "Invalid" ;
VAL_ 3221225472 AcceleratorActualPosV 0 "Valid" 1 "Invalid" ;
VAL_ 3221225472 CruiseControlActive 0 "False" 1 "True" ;
VAL_ 3221225472 ThrottlePosV 0 "Valid" 1 "Invalid" ;
VAL_ 3221225472 AcceleratorEffectivePosV 0 "Valid" 1 "Invalid" ;
VAL_ 3221225472 EngineSpeedV 0 "Valid" 1 "Invalid" ;
VAL_ 65 Heater_Status 4 "Fault" 3 "Prewarm" 2 "On" 1 "Warm_Up" 0 "Off" ;
VAL_ 1959 RtmControlState 0 "RtmOffline" 1 "RtmStartup" 2 "RtmRunning" 3 "RtmShutdown_SetDischarge" 4 "RtmShutdown_DischargeActive" 5 "RtmShutdown_DischargeComplete" 6 "RtmShutdown_ShutdownFault" 7 "RtmClearCodes" ;
VAL_ 1959 BmsControlState 0 "BmsOffline" 1 "BmsStartup" 2 "BmsCloseContactors" 3 "BmsOnline" 4 "BmsShutdown" ;
VAL_ 1959 mVec2ControlState 0 "mVec2ControllersOff" 1 "mVec2PowerModeOn" 2 "mVec2VehicleReadyOn" 3 "mVec2RineKeepOn" 4 "mVec2ChargerOn_NotCharging" 5 "mVec2ChargerOn_Charging" 6 "mVec2ChargerOn_Error" 7 "mVec2ChargerOn_FinishedCharging" ;
VAL_ 1959 mVecControlState 0 "mVec1ControllersOff" 1 "mVec1PowerModeOn" 2 "mVec1VehicleReadyOn" 3 "mVec1RineKeepOn" 4 "mVec1ChargerOn" ;
VAL_ 1959 TransmissionOverrideState 0 "Follow_Lever" 1 "Transition_to_Neutral" 2 "Forced_Neutral" 3 "Transition_to_Lever" ;
VAL_ 1959 IceControlState 0 "IceOff" 1 "IceStartup" 2 "IceCrank_CrankOn" 3 "IceCrank_KeepCranking" 4 "IceCrank_CheckCrank" 5 "IceCrank_CrankComplete" 6 "IceCrank_CrankFail" 7 "IceIdle" 8 "IceEngaged" 9 "IceShutdown" 10 "IceRestartDelay" ;
VAL_ 1959 VehicleMode 0 "PowertrainOff" 1 "RegenBraking" 2 "MixedBraking" 3 "HydraulicBraking" 4 "RtmOnly" 5 "Hybrid" 6 "IceOnly" 7 "Performance" 8 "LoadShifting" 9 "WaitForStartup" 10 "VehicleShuttingDown" 11 "OnCharger" 12 "ParkAndBrake" 13 "WaitForCrank" 14 "VehicleReady" 15 "PowertrainOff_No_Ice" 16 "PowertrainOff_StartIce" 17 "PowertrainOff_EngineIdle" 18 "PowertrainOff_EngineRevAllowed" 19 "IceOnly_EngageTransmission" 20 "IceOnly_StartEngine" ;
VAL_ 1956 UW_Commanded_Gear 15 "Lever Position Unknown" 11 "Forward Range H" 10 "Forward Range G" 9 "Forward Range F" 8 "Forward Range E" 7 "Forward Range D" 6 "Forward Range C" 5 "Forward Range B" 4 "Forward Range A" 3 "Neutral Range" 2 "Reverse Range" 1 "Park Range" 0 "Between Ranges" ;
VAL_ 1954 UW_ESS_SOC 255 "ERROR" 254 "NO_VALUE" ;
VAL_ 1954 UW_ESS_cell_tmax 255 "ERROR" 254 "NO_VALUE" ;
VAL_ 1954 UW_ESS_vbat 4095 "ERROR" 4094 "NO_VALUE" ;
VAL_ 1954 UW_ESS_ibat 65534 "NO_VALUE" 65535 "ERROR" ;
VAL_ 1953 DECM_Diagnostics 2 "OK" 1 "Limited" 0 "Offline" ;
VAL_ 1953 TCM_Diagnostics 2 "OK" 1 "Limited" 0 "Offline" ;
VAL_ 1953 EMIS_Diagnostics 2 "OK" 1 "Limited" 0 "Offline" ;
VAL_ 1953 BRUSA_Diagnostics 2 "OK" 1 "Limited" 0 "Offline" ;
VAL_ 1953 EMP_Diagnostics 2 "OK" 1 "Limited" 0 "Offline" ;
VAL_ 1953 DCDC_Diagnostics 2 "OK" 1 "Limited" 0 "Offline" ;
VAL_ 1953 Driver_Input_Diagnostics 2 "OK" 1 "Limited" 0 "Offline" ;
VAL_ 1953 RINE_Operating_Status 16 "Clearing 5 V Sense Post Fault" 3 "Shutdown" 2 "Run" 1 "Start Up" 0 "Off" ;
VAL_ 1953 RINE_Diagnostics 2 "OK" 1 "Limited" 0 "Offline" ;
VAL_ 1953 BMS_Diagnostics 2 "OK" 1 "Limited" 0 "Offline" ;
VAL_ 1223 EngSnPwrECoolLpTmpV 1 "Invalid" 0 "Valid" ;
VAL_ 1223 PropSysOffTmeV 1 "Invalid" 0 "Valid" ;
VAL_ 1223 PropSysOffTmeM 1 "Use Data" 0 "Don't Use Data" ;
VAL_ 241 NotEventStat 2 "Pretensioner Deployment Event" 1 "Near Deployment Event" 0 "No Event" 3 "Airbag Deployment Event" ;
VAL_ 241 BrkAppSnsrHmPosLrnd 1 "true" 0 "false" ;
VAL_ 241 BrkPedTrvlAchvd 1 "true" 0 "false" ;
VAL_ 241 BrkPedTrvlAchvdV 1 "Invalid" 0 "Valid" ;
VAL_ 241 BrkPdlModTrvlV 1 "Invalid" 0 "Valid" ;
VAL_ 241 BrkPdlModTrvl 1 "true" 0 "false" ;
VAL_ 1005 EnhSvVehTopSpdLmR 2 "Inactive" 1 "Active" 0 "No Action" ;
VAL_ 1105 JmpStrtReq 1 "true" 0 "false" ;
VAL_ 1105 HybVehHiVltInvDisRqd 1 "true" 0 "false" ;
VAL_ 1105 NESSRoSevSt 1 "true" 0 "false" ;
VAL_ 1105 NESSRiSiSevSt 1 "true" 0 "false" ;
VAL_ 1105 NESSReImpSevSt 1 "true" 0 "false" ;
VAL_ 1105 NESSLeSiSevSt 1 "true" 0 "false" ;
VAL_ 1105 NESSFrImpSt2SevSt 1 "true" 0 "false" ;
VAL_ 1105 NESSFrImpSt1SevSt 1 "true" 0 "false" ;
VAL_ 1105 NESSFrImpPreSevSt 1 "true" 0 "false" ;
VAL_ 419 EngRunng 1 "true" 0 "false" ;
VAL_ 1906 DTCI_DTCFaultType_772 3 "Type C" 2 "Type B" 1 "Type A" 0 "Not Supported" ;
VAL_ 1906 DTCI_CodeSupported_772 1 "true" 0 "false" ;
VAL_ 1906 DTCI_CurrentStatus_772 1 "true" 0 "false" ;
VAL_ 1906 DTCI_TstNPsdCdClrdSt_772 1 "true" 0 "false" ;
VAL_ 1906 DTCI_TstFldCdClrdStat_772 1 "true" 0 "false" ;
VAL_ 1906 DTCI_HistStat_772 1 "true" 0 "false" ;
VAL_ 1906 DTCI_TstNPsdPwrUpSt_772 1 "true" 0 "false" ;
VAL_ 1906 DTCI_TstFldPwrUpSt_772 1 "true" 0 "false" ;
VAL_ 1906 DTCI_WrnIndRqdSt_772 1 "true" 0 "false" ;
VAL_ 1906 DTCI_DTCTriggered_772 1 "true" 0 "false" ;
VAL_ 1906 DTCIUnused7_772 1 "true" 0 "false" ;
VAL_ 1906 DTCIUnused6_772 1 "true" 0 "false" ;
VAL_ 1906 DTCIUnused5_772 1 "true" 0 "false" ;
VAL_ 1906 DTCIUnused4_772 1 "true" 0 "false" ;
VAL_ 1906 DTCIUnused3_772 1 "true" 0 "false" ;
VAL_ 1906 DTCIUnused2_772 1 "true" 0 "false" ;
VAL_ 1906 DTCIUnused1_772 1 "true" 0 "false" ;
VAL_ 500 DrvSelMd8Stat 1 "Active" 0 "Inactive" ;
VAL_ 500 DrvSelMd8ReqDnd 1 "true" 0 "false" ;
VAL_ 500 DrvSelMd7Stat 1 "Active" 0 "Inactive" ;
VAL_ 500 DrvSelMd7ReqDnd 1 "true" 0 "false" ;
VAL_ 500 DrvSelMd6Stat 1 "Active" 0 "Inactive" ;
VAL_ 500 DrvSelMd6ReqDnd 1 "true" 0 "false" ;
VAL_ 500 DrvSelMd5Stat 1 "Active" 0 "Inactive" ;
VAL_ 500 DrvSelMd5ReqDnd 1 "true" 0 "false" ;
VAL_ 500 DrvSelMd4Stat 1 "Active" 0 "Inactive" ;
VAL_ 500 DrvSelMd4ReqDnd 1 "true" 0 "false" ;
VAL_ 500 DrvSelMd3Stat 1 "Active" 0 "Inactive" ;
VAL_ 500 DrvSelMd3ReqDnd 1 "true" 0 "false" ;
VAL_ 500 DrvSelMd2Stat 1 "Active" 0 "Inactive" ;
VAL_ 500 DrvSelMd2ReqDnd 1 "true" 0 "false" ;
VAL_ 500 DSMSS_DrvSelMd0Pn 1 "true" 0 "false" ;
VAL_ 500 DSMSS_DrvSelMd8Pn 1 "true" 0 "false" ;
VAL_ 500 DSMSS_DrvSelMd7Pn 1 "true" 0 "false" ;
VAL_ 500 DSMSS_DrvSelMd6Pn 1 "true" 0 "false" ;
VAL_ 500 DSMSS_DrvSelMd5Pn 1 "true" 0 "false" ;
VAL_ 500 DSMSS_DrvSelMd4Pn 1 "true" 0 "false" ;
VAL_ 500 DSMSS_DrvSelMd3Pn 1 "true" 0 "false" ;
VAL_ 500 DSMSS_DrvSelMd2Pn 1 "true" 0 "false" ;
VAL_ 500 DSMSS_DrvSelMd1Pn 1 "true" 0 "false" ;
VAL_ 500 DSMSS_DrvSelMd8Un 1 "true" 0 "false" ;
VAL_ 500 DSMSS_DrvSelMd7Un 1 "true" 0 "false" ;
VAL_ 500 DSMSS_DrvSelMd6Un 1 "true" 0 "false" ;
VAL_ 500 DSMSS_DrvSelMd5Un 1 "true" 0 "false" ;
VAL_ 500 DSMSS_DrvSelMd4Un 1 "true" 0 "false" ;
VAL_ 500 DSMSS_DrvSelMd3Un 1 "true" 0 "false" ;
VAL_ 500 DSMSS_DrvSelMd2Un 1 "true" 0 "false" ;
VAL_ 500 DSMSS_DrvSelMd1Un 1 "true" 0 "false" ;
VAL_ 500 DrvSelMd1ReqDnd 1 "true" 0 "false" ;
VAL_ 500 DrvSelMd1Stat 1 "Active" 0 "Inactive" ;
VAL_ 707 CSTATRS_ReqStat 6 "Control System Failure Permanent" 5 "Control System Failure Temporary" 4 "Serial Data Failure Permanent" 3 "Serial Data Failure Temporary" 2 "Lost Arbitration" 1 "Request Honored" 0 "No Request" ;
VAL_ 707 CSTATRS_LmtgStat 3 "Rate and Value Limited" 2 "Value Limited" 1 "Rate Limited" 0 "Not Limited" ;
VAL_ 707 EngManfldAbsPrsV 1 "Invalid" 0 "Valid" ;
VAL_ 707 EngTrqMinExtRngV 1 "Invalid" 0 "Valid" ;
VAL_ 707 EngTrqMaxExtRngV 1 "Invalid" 0 "Valid" ;
VAL_ 417 EngCrsCntrlMode 5 "Tap" 4 "Coast" 3 "Accel" 2 "Resume" 1 "Engaged" 0 "Inactive" ;
VAL_ 417 EngPstOxgSnsDgAstRq 1 "true" 0 "false" ;
VAL_ 417 CrsCtrlCnstSpdAct 1 "true" 0 "false" ;
VAL_ 417 WrmUpShftPtrnRq 1 "Active" 0 "Inactive" ;
VAL_ 417 EngAlwCltAdp 1 "true" 0 "false" ;
VAL_ 417 AccPdlPosPcntFullRngV 1 "Invalid" 0 "Valid" ;
VAL_ 417 DslPrtFltrIdlRgtnMdReq 1 "true" 0 "false" ;
VAL_ 417 DslPartFltrClngAlgActM 1 "Use Data" 0 "Don't Use Data" ;
VAL_ 417 DslPartFltrClngAlgAct 1 "true" 0 "false" ;
VAL_ 417 EngCylDeactMd 3 "Reactivation In Progress" 2 "Half of Total Cylinders Active" 1 "Deactivation In Progress" 0 "All Cylinders Active" ;
VAL_ 417 ACCmCltEngd 1 "true" 0 "false" ;
VAL_ 417 ParkNeutralSwStatV 1 "Invalid" 0 "Valid" ;
VAL_ 417 ParkNeutralSwStat 1 "Not Park/Neutral" 0 "Park/Neutral" ;
VAL_ 417 EngColdHiIdleActive 1 "true" 0 "false" ;
VAL_ 417 EngCyDactTqSmtAct 1 "true" 0 "false" ;
VAL_ 417 EngBrkStat 2 "Active Absorbing Torque" 1 "Active Not Absorbing Torque" 0 "Inactive" ;
VAL_ 417 TracCntlSysPwrtrnInhbt 1 "true" 0 "false" ;
VAL_ 417 EngMtlProtAtv 1 "true" 0 "false" ;
VAL_ 417 EngDgTrqCnvClUnlkRqd 1 "true" 0 "false" ;
VAL_ 417 EngCyldrDeactReqd 1 "true" 0 "false" ;
VAL_ 417 ETGRReqdGear 8 "Eighth Gear" 7 "Seventh Gear" 6 "Sixth Gear" 5 "Fifth Gear" 4 "Fourth Gear" 3 "Third Gear" 2 "Second Gear" 1 "First Gear" 0 "No Action" ;
VAL_ 417 ETGRReqType 0 "No Action" 3 "Hold Gear" 2 "Min Gear Request" 1 "Max Gear Request" ;
VAL_ 401 EngTrqTrnRqTmpFld 1 "true" 0 "false" ;
VAL_ 401 EngTrqTrnRqLmtd 1 "true" 0 "false" ;
VAL_ 401 TrnsEngSpdReqFld 1 "true" 0 "false" ;
VAL_ 401 EngTrqTnsRqFld 1 "true" 0 "false" ;
VAL_ 401 EngTrqRdnFld 1 "true" 0 "false" ;
VAL_ 401 EngNTrnsRegStdyStTqV 1 "Invalid" 0 "Valid" ;
VAL_ 401 EngAirflwStdyStTorqV 1 "Invalid" 0 "Valid" ;
VAL_ 401 AccKdwnAtv 1 "true" 0 "false" ;
VAL_ 401 AccPosV 1 "Invalid" 0 "Valid" ;
VAL_ 401 EngActStdyStTorqV 1 "Invalid" 0 "Valid" ;
VAL_ 479 PrplsnSysAtv 1 "true" 0 "false" ;
VAL_ 479 PTShftLvrLckRqd 1 "true" 0 "false" ;
VAL_ 393 TPCTR_TrqIntrvnTyp 3 "Unused and Reserved" 2 "Minimum Limit" 1 "Maximum Limit" 0 "No Request" ;
VAL_ 393 TICTR_TorqRespTyp 3 "Automatic Actuator Selection" 2 "Maximum Range" 1 "Pleasability Limited" 0 "Inactive" ;
VAL_ 190 PTSnsdBrkPdlPosV 1 "Invalid" 0 "Valid" ;
VAL_ 463 SecAxlNonEmMalfIO 1 "true" 0 "false" ;
VAL_ 463 SecAxlOperMod 3 "Active All Wheel Drive (High)" 2 "4 Wheel Drive Low Locked" 1 "4 Wheel Drive High Locked" 0 "2 Wheel Drive High" 15 "Neutral" 14 "Unknown" 7 "2 Wheel Drive Low" 6 "Active All Wheel Drive (Low)" 5 "4 Wheel Drive Low Open" 4 "4 Wheel Drive High Open" ;
VAL_ 463 SecAxlTmpInhIO 1 "true" 0 "false" ;
VAL_ 497 FuelFltLfRstRqd 1 "true" 0 "false" ;
VAL_ 497 ACCompSysVDA 1 "VirtualDeviceAvailable" 0 "VirtualDeviceUnavailable" ;
VAL_ 497 BkupPwrModeMstrVDA 1 "VirtualDeviceAvailable" 0 "VirtualDeviceUnavailable" ;
VAL_ 497 PrkBrkVDA 1 "VirtualDeviceAvailable" 0 "VirtualDeviceUnavailable" ;
VAL_ 497 PrkBrkVDM 1 "Use Data" 0 "Don't Use Data" ;
VAL_ 497 BkupPwrModeMstrVDM 1 "Use Data" 0 "Don't Use Data" ;
VAL_ 497 ACCompSysVDM 1 "Use Data" 0 "Don't Use Data" ;
VAL_ 497 AirbgVDA 1 "VirtualDeviceAvailable" 0 "VirtualDeviceUnavailable" ;
VAL_ 497 SysBkupPwrMdEn 1 "true" 0 "false" ;
VAL_ 497 SysBkUpPwrMd 3 "Crank Request" 2 "Run" 1 "Accessory" 0 "Off" ;
VAL_ 497 SysPwrMd 3 "Crank Request" 2 "Run" 1 "Accessory" 0 "Off" ;
VAL_ 497 TrStLgMdAtv 1 "true" 0 "false" ;
VAL_ 497 DispMeasSys 1 "English" 0 "Metric" ;
VAL_ 497 ACCmpsrFldOn 1 "true" 0 "false" ;
VAL_ 497 ACCompModReq 3 "No Action" 2 "Engage" 1 "Disengage" 0 "Disengage Immediately" ;
VAL_ 497 ACCompNormLdV 1 "Invalid" 0 "Valid" ;
VAL_ 497 PTORSMstrEngShtReq 1 "true" 0 "false" ;
VAL_ 497 EngOilLfRstRq 1 "true" 0 "false" ;
VAL_ 497 SIRDpl 1 "true" 0 "false" ;
VAL_ 497 PTORmStMsEngStRq 1 "PTO Remote Start Requested" 0 "PTO Remote Start Not Requested" ;
VAL_ 497 RmVehStrRq 1 "Remote Start Requested" 0 "Remote Start Not Requested" ;
VAL_ 497 ThrtlPrgrsnReq 2 "Map C" 1 "Map B" 0 "Map A" ;
VAL_ 497 PrkBrkSwAtv 1 "true" 0 "false" ;
VAL_ 497 PMMAccTrmSt 1 "Active" 0 "Inactive" ;
VAL_ 497 PMMRunCrkTrmSt 1 "Active" 0 "Inactive" ;
VAL_ 497 ImmblzrPreRelPswdStat 1 "Information Valid" 0 "No Information" ;
VAL_ 453 DrvIntndAxlTrqV 1 "Invalid" 0 "Valid" ;
VAL_ 453 DrvIntndAxlTrqMinV 1 "Invalid" 0 "Valid" ;
VAL_ 453 DrvIntndAxlTrqMaxV 1 "Invalid" 0 "Valid" ;
VAL_ 1257 ElpsdTimeCntRstOcc 1 "true" 0 "false" ;
VAL_ 1257 ACCompType 4 "Electric Driven Motor" 3 "Variable Displacement Electronic" 2 "Variable Displacement Mechanical" 1 "Fixed Displacement Clutched" 0 "None" ;
VAL_ 1257 VSESysPrs 1 "true" 0 "false" ;
VAL_ 1257 ABSPr 1 "true" 0 "false" ;
VAL_ 1257 TCSysPr 1 "true" 0 "false" ;
VAL_ 1257 VehSpdCntlSystmType 2 "Adaptive Cruise Control" 1 "Conventional Cruise Control" 0 "No Vehicle Speed Control" ;
VAL_ 1257 PltfrmEngSpdCmdSysTp 6 "Auto Elevated Idle" 5 "Enhanced Fast Idle" 4 "Fast Idle" 3 "Mobile Variable PTO" 2 "Stationary Variable PTO" 1 "Stationary PTO" 0 "No Platform Eng. Speed Command Sys." ;
VAL_ 721 SecondaryAxEngaged 1 "True" 0 "False" ;
VAL_ 721 TransferCaseRangeV 0 "Valid" 1 "Invalid" ;
VAL_ 721 TransferCaseRange 0 "High" 1 "Low" 3 "Neutral" ;
VAL_ 721 TransferCaseNonEmRelMalAct 1 "True" 0 "False" ;
VAL_ 721 TransferCaseMode 0 "2 Wheel Drive High" 1 "4 Wheel Drive High Locked" 2 "4 Wheel Drive Low Locked" 3 "Active All Wheel Drive" 4 "4 Wheel Drive High Open" 5 "4 Wheel Drive Low Open" 6 "4WDLow Locked Differential Locked" 15 "Neutral" ;
VAL_ 721 TransferCaseEmRelMalAct 1 "True" 0 "False" ;
VAL_ 721 TCERDTC_SystemDes 0 "P0-Powertrain Codes SAE Controlled" 1 "P1-Powertrain Codes MFG Controlled" 2 "P2-Powertrain Codes Reserved" 3 "P3-Powertrain Codes Reserved" 4 "C0-Chassis Codes SAE Controlled" 5 "C1-Chassis Codes MFG Controlled" 6 "C2-Chassis Codes Reserved" 7 "C3-Chassis Codes Reserved" 8 "B0-Body Codes SAE Controlled" 9 "B1-Body Codes MFG Controlled" 10 "B2-Body Codes Reserved" 11 "B3-Body Codes Reserved" 12 "U0-Network Codes SAE Controlled" 13 "U1-Network Codes MFG Controlled" 14 "U2- Network Codes Reserved" 15 "U3-Network Codes Reserved" ;
VAL_ 721 CenterDiffStatus 0 "Open" 1 "Locked" 2 "Controlled" ;
VAL_ 413 TrnsCyDactTransStat 2 "Ready for Half of TotalCylinders" 1 "Ready for All Cylinders" 0 "Not Ready" ;
VAL_ 413 EngBrkDsblReqd 1 "true" 0 "false" ;
VAL_ 413 TransNtrlCntrlMdStat 3 "Exiting Neutral Control" 2 "Neutral Control Active" 1 "Entering Neutral Control" 0 "Neutral Control Not Active" ;
VAL_ 413 TrnsRtoCntlSysFlt 1 "true" 0 "false" ;
VAL_ 413 TrnTrbAngVlV 1 "Invalid" 0 "Valid" ;
VAL_ 413 TrnGrRatV 1 "Invalid" 0 "Valid" ;
VAL_ 413 TrnPrfAlgShfAtv 1 "true" 0 "false" ;
VAL_ 413 TESR_EngSpdCntlRsp 3 "Stability Optimized Condition 2" 2 "Stability Optimized Condition 1" 1 "Transient Optimized" 0 "No Suggestion" ;
VAL_ 413 TESR_EngSpdIntTyp 2 "Engine Speed Min Limit" 1 "Engine Speed Max Limit" 0 "No Intervention" ;
VAL_ 413 TrnsGrgShftAct 1 "true" 0 "false" ;
VAL_ 719 RVBATC_AxTrqReqAct 0 "False" 1 "True" ;
VAL_ 717 CPSATC_AxlTrqRqstAct 1 "true" 0 "false" ;
VAL_ 715 ACCATC_SplREngInpR 1 "true" 0 "false" ;
VAL_ 715 ACCATC_DrvAstdGoSt 2 "Apply Acc Pedal or Resume Sw To Go" 1 "Apply Accel Pedal to Go" 0 "Not Stopped" ;
VAL_ 715 ACCATC_ACCTyp 2 "Full Speed Range ACC with Booster" 1 "Full Speed Range ACC" 0 "Adaptive Cruise Control" ;
VAL_ 715 ACCATC_ACCAct 1 "true" 0 "false" ;
VAL_ 409 TDslPrtFltrIdlRgtnMdAtv 1 "true" 0 "false" ;
VAL_ 409 TTRLT_TqRdnRlznSgg 3 "Stability Optimized 2" 2 "Stability Optimized 1" 1 "Transient Optimized" 0 "No Suggestion" ;
VAL_ 409 TTRLT_TorqInvntnTyp 2 "Minimum Limit" 1 "Maximum Limit" 0 "No Intervention" ;
VAL_ 409 TTRST_TorqInvntnTyp 1 "Maximum Limit" 0 "No Intervention" ;
VAL_ 505 AccPdlPwrTkOffOvrAct 1 "true" 0 "false" ;
VAL_ 505 PTOTGRReqdGear 8 "Eighth Gear" 7 "Seventh Gear" 6 "Sixth Gear" 5 "Fifth Gear" 4 "Fourth Gear" 3 "Third Gear" 2 "Second Gear" 1 "First Gear" 0 "No Action" ;
VAL_ 505 PTOTGRReqType 3 "Hold Gear" 2 "Min Gear Request" 1 "Max Gear Request" 0 "No Action" ;
VAL_ 505 PTORmtEngStrtReq 1 "PTO Remote Start Requested" 0 "PTO Remote Start Not Requested" ;
VAL_ 505 TrnsPTOCltchRelRqd 1 "true" 0 "false" ;
VAL_ 505 FstIdlMdAct 1 "true" 0 "false" ;
VAL_ 505 PTOMdAct 1 "true" 0 "false" ;
VAL_ 505 PTOEngTrqLmtRchd 1 "true" 0 "false" ;
VAL_ 505 PltfrmEngSpdCmdMdAct 1 "true" 0 "false" ;
VAL_ 505 PFESpdCmdOnSwAct 1 "true" 0 "false" ;
VAL_ 505 PFESpdCmdDeSwAct 1 "true" 0 "false" ;
VAL_ 505 PFESpdCmdInSwAct 1 "true" 0 "false" ;
VAL_ 505 PFESpdCmdSwDIntg 2 "Failure Detected" 1 "Data Invalid" 0 "Data Valid" ;
VAL_ 505 PTORmtEngShtdwnReqd 1 "true" 0 "false" ;
VAL_ 1001 DistRollCntAvgDrvnSrc 1 "Wheel Speed" 0 "Transmission Output Speed" ;
VAL_ 1001 VehSpdAvgDrvnSrc 1 "Wheel Speed" 0 "Transmission Output Speed" ;
VAL_ 1001 DstRolCntAvgNonDrvnV 1 "Invalid" 0 "Valid" ;
VAL_ 1001 DstRolCntAvNDrRstOc 1 "true" 0 "false" ;
VAL_ 1001 DistRollCntAvgDrvnV 1 "Invalid" 0 "Valid" ;
VAL_ 1001 DstRolCntAvgDrnRstOc 1 "true" 0 "false" ;
VAL_ 1001 VehSpdAvgNDrvnV 1 "Invalid" 0 "Valid" ;
VAL_ 1001 VehSpdAvgDrvnV 1 "Invalid" 0 "Valid" ;
VAL_ 499 PTShftPtrnOvrdAct 1 "true" 0 "false" ;
VAL_ 499 PFTrnsTUDSecSwSt 3 "Illegal Up/Down Switch State Active" 2 "Decrement Switch Active" 1 "Increment Switch Active" 0 "No Activation" ;
VAL_ 499 TrnsPFShftPattSw4Act 1 "true" 0 "false" ;
VAL_ 499 TrnsPFShftPattSw3Act 1 "true" 0 "false" ;
VAL_ 499 TrnsPFShftPattSw2Act 1 "true" 0 "false" ;
VAL_ 499 TrnsPFShftPattSw1Act 1 "true" 0 "false" ;
VAL_ 499 PFTrnsTUDSwSt 3 "Illegal Up/Down Switch State Active" 2 "Decrement Switch Active" 1 "Increment Switch Active" 0 "No Activation" ;
VAL_ 499 PFTrnsTUDEnSwSt 3 "Illegal Enable Switch State" 2 "Electronic Range Select Enable Sw" 1 "Driver Shift Control Enable Switch" 0 "No Activation" ;
VAL_ 499 OvrdrvDsblReqd 1 "true" 0 "false" ;
VAL_ 490 FlLvlTank2PctV 1 "Invalid" 0 "Valid" ;
VAL_ 490 AltFuelPHeatAct 1 "true" 0 "false" ;
VAL_ 490 AltFuelMdReqDndIO 1 "true" 0 "false" ;
VAL_ 490 AltFuelLvlLo 1 "true" 0 "false" ;
VAL_ 490 AltFuelAccWrnngAct 1 "true" 0 "false" ;
VAL_ 490 FuelMdStat 3 "Alternative Fuel Cut-off Active" 2 "Liquified Petroleum Gas Mode" 1 "Natural Gas Mode" 0 "Gasoline Mode" ;
VAL_ 481 CrsSecSwStat 15 "Unused and Reserved 7" 14 "Unused and Reserved 6" 13 "Unused and Reserved 5" 12 "Unused and Reserved 4" 11 "Unused and Reserved 3" 10 "Unused and Reserved 2" 9 "Between Ranges" 8 "Short to Power" 7 "Open/Short to Ground" 6 "Speed Decrease High" 5 "Speed Increase High" 4 "Gap Up" 3 "Gap Down" 2 "Unused and Reserved 1" 1 "No Activation" 0 "Indeterminate" ;
VAL_ 481 DrvSelMdSw3Sta 1 "Active" 0 "Inactive" ;
VAL_ 481 DrvSelMdSw2Sta 1 "Active" 0 "Inactive" ;
VAL_ 481 AuxHtrRq 1 "On" 0 "Off" ;
VAL_ 481 AuxHtrAtv 1 "true" 0 "false" ;
VAL_ 481 DrvSelMdSw1Sta 1 "Active" 0 "Inactive" ;
VAL_ 481 FuelMdSwActV 1 "Invalid" 0 "Valid" ;
VAL_ 481 FuelMdSwAct 1 "True" 0 "False" ;
VAL_ 481 CrsSpdLmtrSwStat 9 "Between Ranges" 8 "Short to Power" 7 "Open/Short to Ground" 6 "Cancel" 5 "Cruise On/Off" 4 "SL/SW On/Off/GAP" 3 "Set" 2 "Resume" 1 "No Activation" 0 "Indeterminate" ;
VAL_ 481 AdptCrsGapSwAct 2 "Increase Gap" 1 "Decrease Gap" 0 "No Activation" ;
VAL_ 481 CrsCntrlSwStCanSwAct 1 "true" 0 "false" ;
VAL_ 481 CrsCntrlSwStSwDataIntgty 3 "Illegal Range" 2 "Failure Detected" 1 "Data Invalid" 0 "Data Valid" ;
VAL_ 481 CrsCntrlSwStSpdInSwAct 1 "true" 0 "false" ;
VAL_ 481 CrsCntrlSwStSpDcSwAct 1 "true" 0 "false" ;
VAL_ 481 CrsCntrlSwStSetSwAct 1 "true" 0 "false" ;
VAL_ 481 CrsCntrlSwStResSwAct 1 "true" 0 "false" ;
VAL_ 481 CrsCntrlSwStOnSwAct 1 "true" 0 "false" ;
VAL_ 481 CrsCntCncRq 1 "Cancel" 0 "Do Not Cancel" ;
VAL_ 460 PowertrainTransferCaseMode 0 "2 Wheel Drive High" 1 "4 Wheel Drive High" 2 "4 Wheel Drive Low" 3 "Neutral" ;
VAL_ 459 TransferCaseCoupValActV 1 "Invalid" 0 "Valid" ;
VAL_ 459 TransferCaseCoupRepType 0 "Actual" 1 "Estimated" ;
VAL_ 405 ThrottlePosV 1 "Invalid" 0 "Valid" ;
VAL_ 405 MassAirFlowV 1 "Invalid" 0 "Valid" ;
VAL_ 405 EngineManiAbsPresExtRngV 1 "Invalid" 0 "Valid" ;
VAL_ 405 EngineInjectorEnabledD 1 "true" 0 "false" ;
VAL_ 405 EngineInjectorEnabledC 1 "true" 0 "false" ;
VAL_ 405 EngineInjectorEnabledB 1 "true" 0 "false" ;
VAL_ 405 EngineInjectorEnabledA 1 "true" 0 "false" ;
VAL_ 405 EngineDistributedFuelModeDef 1 "true" 0 "false" ;
VAL_ 485 StrWhAngGrdV 0 "Valid" 1 "Invalid" ;
VAL_ 485 StrWhAngGrdMsk 0 "Don't Use Data" 1 "Use Data" ;
VAL_ 485 StrWhAngMsk 0 "Don't Use Data" 1 "Use Data" ;
VAL_ 485 StrWhlAngSenTyp 0 "Type 1" 1 "Type 2" 2 "Type 3" 3 "Type 4" ;
VAL_ 485 StrWhlAngSenCalStat 2 "Calibrated" 1 "Estimated" 0 "Unknown" ;
VAL_ 485 StrWhAngV 1 "Invalid" 0 "Valid" ;
VAL_ 201 PrsElvtdIdlCntlStat 1 "Enabled" 0 "Disabled" ;
VAL_ 201 Eng12vStrtrMtrCmmdOn 1 "true" 0 "false" ;
VAL_ 201 EngCntrlRunCrnkTrmSt 1 "Active" 0 "Inactive" ;
VAL_ 201 EngAirIntBstPrV 1 "Invalid" 0 "Valid" ;
VAL_ 201 SpdLmtrSpdWrngEnbld 1 "true" 0 "false" ;
VAL_ 201 EngCylDactEvntPndg 1 "true" 0 "false" ;
VAL_ 201 EngCylDeactMd 3 "Reactivation In Progress" 2 "Half of Total Cylinders Active" 1 "Deactivation In Progress" 0 "All Cylinders Active" ;
VAL_ 201 RmVhStrtEngRng 1 "true" 0 "false" ;
VAL_ 201 PFEngSpdCmndSpcd 1 "true" 0 "false" ;
VAL_ 201 PltfrmEngSpdCmdInhtRq 1 "Inhibit Platform Eng. Speed Control" 0 "Allow Platform Engine Speed Control" ;
VAL_ 201 PT_BrkPedDscrtInpStatV 1 "Invalid" 0 "Valid" ;
VAL_ 201 PT_BrkPedDscrtInpStat 1 "Brake Applied" 0 "Brake Not Applied" ;
VAL_ 201 CrsCntEnbld 1 "true" 0 "false" ;
VAL_ 201 CrsCntAtv 1 "true" 0 "false" ;
VAL_ 201 DrvThrottlOvrrdDet 1 "true" 0 "false" ;
VAL_ 201 PT_CrnkAct 1 "true" 0 "false" ;
VAL_ 201 PTRunAbrt 1 "true" 0 "false" ;
VAL_ 201 PTO_PT_RunAbrtd 1 "true" 0 "false" ;
VAL_ 201 PTCrnkAbrted 1 "true" 0 "false" ;
VAL_ 201 EngSpdStat 3 "Invalid" 1 "Degraded Operation" 0 "Normal Operation" ;
VAL_ 201 EngRunAtv 1 "true" 0 "false" ;
VAL_ 201 EngIdlAtv 1 "true" 0 "false" ;
VAL_ 977 FuelFltLifRstPerf 1 "true" 0 "false" ;
VAL_ 977 SpdLmtrSpdWrngAct 1 "true" 0 "false" ;
VAL_ 977 CrsCntlDrSelSpdAct 1 "true" 0 "false" ;
VAL_ 977 ACCompCmnd 1 "On" 0 "Off" ;
VAL_ 977 EngBstPrsIndV 1 "Invalid" 0 "Valid" ;
VAL_ 977 EngOilLifRstPerf 1 "true" 0 "false" ;
VAL_ 977 ThrPosV 1 "Invalid" 0 "Valid" ;
VAL_ 977 EngOilStrvtnIO 1 "true" 0 "false" ;
VAL_ 977 EngNEmsnsRelMalfAct 1 "true" 0 "false" ;
VAL_ 977 EngEmsRelMalfIndReq 4 "Flashing 0.5 Hertz Indication" 3 "Flashing 2 Hertz Indication" 2 "Flashing 1 Hertz Indication" 1 "No Indication" 0 "Continuous Indication" ;
VAL_ 977 EngCstFlCutAct 1 "true" 0 "false" ;
VAL_ 1017 ACRfHiSdFldPrsV 1 "Invalid" 0 "Valid" ;
VAL_ 1017 GenStptDtCycPtOvrAct 1 "true" 0 "false" ;
VAL_ 1017 VehTopSpdLmtMdAct 1 "true" 0 "false" ;
VAL_ 1017 GenFldDutCycV 1 "Invalid" 0 "Valid" ;
VAL_ 1017 GenFld 1 "true" 0 "false" ;
VAL_ 1017 FlInjRlCtRstOcc 1 "true" 0 "false" ;
VAL_ 1017 EngSpdLmtnMdAct 1 "true" 0 "false" ;
VAL_ 1217 LegPstDTCClrDrvCyCm 1 "true" 0 "false" ;
VAL_ 1217 LegDiagColdStCndMet 1 "true" 0 "false" ;
VAL_ 1217 LegDiagColdStCndFltPr 1 "true" 0 "false" ;
VAL_ 1217 EngEconMdCmnd 1 "true" 0 "false" ;
VAL_ 1217 DslExhFldRmngDstHRsV 1 "Invalid" 0 "Valid" ;
VAL_ 1217 EngOilHotIO 1 "true" 0 "false" ;
VAL_ 1217 OAT_PT_EstV 1 "Invalid" 0 "Valid" ;
VAL_ 1217 LegDiagStndCndMet 1 "true" 0 "false" ;
VAL_ 1217 LegDiagStndCndFltPr 1 "true" 0 "false" ;
VAL_ 1217 OAT_PT_EstM 1 "Use Data" 0 "Don't Use Data" ;
VAL_ 1217 EngWrmUpAch 1 "true" 0 "false" ;
VAL_ 1217 EngIntAirTmpV 1 "Invalid" 0 "Valid" ;
VAL_ 1217 EngCltTmpV 1 "Invalid" 0 "Valid" ;
VAL_ 1217 BarPrsAbsV 1 "Invalid" 0 "Valid" ;
VAL_ 1233 EngShtdwnAct 1 "true" 0 "false" ;
VAL_ 1233 EngShtdwnPndgIO 1 "true" 0 "false" ;
VAL_ 1233 FuelFltChgNwIO 1 "true" 0 "false" ;
VAL_ 1233 PTExPrtclFltrWrn2IO 1 "true" 0 "false" ;
VAL_ 1233 PTHiElecLdReqd 1 "true" 0 "false" ;
VAL_ 1233 PTExPrtclFltrWrnIO 1 "true" 0 "false" ;
VAL_ 1233 AirCndOffIO 1 "true" 0 "false" ;
VAL_ 1233 DslGlwPlgIO 1 "true" 0 "false" ;
VAL_ 1233 StgDisIO 1 "true" 0 "false" ;
VAL_ 1233 RdcdPwrIO 1 "true" 0 "false" ;
VAL_ 1233 FlLvlPctV 1 "Invalid" 0 "Valid" ;
VAL_ 1233 EngWtrInFlIO 1 "true" 0 "false" ;
VAL_ 1233 EngOilTmpV 1 "Invalid" 0 "Valid" ;
VAL_ 1233 EngOilPrsV 1 "Invalid" 0 "Valid" ;
VAL_ 1233 EngOilPrsLwIO 1 "true" 0 "false" ;
VAL_ 1233 EngOilLvlLwIO 1 "true" 0 "false" ;
VAL_ 1233 EngOilChngIO 1 "true" 0 "false" ;
VAL_ 1233 EngHt_StpEngIO 1 "true" 0 "false" ;
VAL_ 1233 EngHotFuelEnrchmntIO 1 "true" 0 "false" ;
VAL_ 1233 CkFlFilrCapIO 1 "true" 0 "false" ;
VAL_ 979 PTABR_PTBrkRqAct 1 "true" 0 "false" ;
VAL_ 979 BrkBstVacV 1 "Invalid" 0 "Valid" ;
VAL_ 398 PTACCAct 1 "true" 0 "false" ;
VAL_ 398 CTSS_StbltyLvl 7 "Level 7" 6 "Level 6" 5 "Level 5" 4 "Level 4" 3 "Level 3" 2 "Level 2" 1 "Level 1" 0 "Level 0" ;
VAL_ 398 CTSS_StbltyTyp 7 "Unused and Reserved 6" 6 "Unused and Reserved 5" 5 "Unused and Reserved 4" 4 "Unused and Reserved 3" 3 "Torque Increase Pending" 2 "Torque Decrease Pending" 1 "Torque High Pulsation" 0 "Normal Stability" ;
VAL_ 398 EngImmTrqTnsRqStat 0 "No Request" 7 "Unused and Reserved" 6 "Control System Failure Permanent" 5 "Control System Failure Temporary" 4 "Serial Data Failure Permanent" 3 "Serial Data Failure Temporary" 2 "Lost Arbitration" 1 "Request Honored" ;
VAL_ 398 EngImmTrqTnsRqLmSt 7 "Unused and Reserved 4" 6 "Unused and Reserved 3" 5 "Unused and Reserved 2" 4 "Unused and Reserved 1" 3 "Value Limited High" 2 "Value Limited Low" 1 "Rate Limited" 0 "Not Limited" ;
VAL_ 398 EngPrdctTrqTnsRqStat 7 "Unused and Reserved" 6 "Control System Failure Permanent" 5 "Control System Failure Temporary" 4 "Serial Data Failure Permanent" 3 "Serial Data Failure Temporary" 2 "Lost Arbitration" 1 "Request Honored" 0 "No Request" ;
VAL_ 398 EngPrdctTrqTnsRqLmS 7 "Unused and Reserved 4" 6 "Unused and Reserved 3" 5 "Unused and Reserved 2" 4 "Unused and Reserved 1" 3 "Value Limited High" 2 "Value Limited Low" 1 "Rate Limited" 0 "Not Limited" ;
VAL_ 442 CrksftMaxTrqLmtV 0 "Valid" 1 "Invalid" ;
VAL_ 442 EngTrqMinImmCapV 1 "Invalid" 0 "Valid" ;
VAL_ 451 GenCrntV 1 "Invalid" 0 "Valid" ;
VAL_ 451 AuxHtrAlwd 1 "true" 0 "false" ;
VAL_ 451 EconMdRqDndIO 1 "true" 0 "false" ;
VAL_ 451 EconMdAtvIO 1 "true" 0 "false" ;
VAL_ 451 AppCltchAutSrtIO 1 "true" 0 "false" ;
VAL_ 451 AccPosV 1 "Invalid" 0 "Valid" ;
VAL_ 451 EngTrqRdFlrSt 4 "Torq Reduction Communication Failed" 3 "Torque Reduction Limited" 2 "Torque Reduction Permanently Failed" 1 "Torque Reduction Temporarily Failed" 0 "Torque Reduction OK" ;
VAL_ 451 EngTrqDrRqdExtRngV 1 "Invalid" 0 "Valid" ;
VAL_ 451 EngTrqActExtRngV 1 "Invalid" 0 "Valid" ;
VAL_ 452 FSpRgACCSwADd 1 "true" 0 "false" ;
VAL_ 452 ABAAPS_AccPosV 1 "Invalid" 0 "Valid" ;
VAL_ 452 ACCATCS_LmtgStat 3 "Request Rate Limited" 2 "Request Value Limited Maximum" 1 "Request Value Limited Minimum" 0 "Request Not Limited" ;
VAL_ 452 ACCATCS_RqStat 4 "Request Suspended Till Driver Input" 3 "Request Denied" 2 "Lost Arbitration" 1 "Request Honored" 0 "No Request" ;
VAL_ 452 AccPdlOvrrdAtv 1 "true" 0 "false" ;
VAL_ 452 CPSATCS_ReqStatus 0 "No Request" 1 "Request Honored" 2 "Lost Arbitration" 3 "Serial Data Failure Temporary" 4 "Serial Data Failure Permanent" 5 "Control System Failure Temporary" 6 "Control System Failure Permanent" ;
VAL_ 452 CPSATCS_LmtngStatus 0 "Request Not Limited" 1 "Request Value Limited to Minimum" 2 "Request Value Limited to Maximum" 3 "Request Rate Limited" ;
VAL_ 452 RVBATCS_ReqStat 0 "No Request" 1 "Request Honored" 2 "Lost Arbitration" 3 "Serial Data Failure Temporary" 4 "Serial Data Failure Permanent" 5 "Control System Failure Temporary" 6 "Control System Failure Permanent" ;
VAL_ 452 RVBATCS_LmtngStat 0 "Request Not Limited" 1 "Request Value Limited to Minimum" 2 "Request Value Limited to Maximum" 3 "Request Rate Limited" ;
VAL_ 489 IMUDataMsk 1 "true" 0 "false" ;
VAL_ 489 DrvIndpntBrkAppAct 1 "true" 0 "false" ;
VAL_ 489 WhlSlpSt 3 "Slip Detection Fault" 2 "Positive Slip Detected" 1 "Negative Slip Detected" 0 "No Slip Detected" ;
VAL_ 489 BSTGRReqdGear 8 "Eighth Gear" 7 "Seventh Gear" 6 "Sixth Gear" 5 "Fifth Gear" 4 "Fourth Gear" 3 "Third Gear" 2 "Second Gear" 1 "First Gear" 0 "No Action" ;
VAL_ 489 BSTGRReqType 3 "Hold Gear" 2 "Min Gear Request" 1 "Max Gear Request" 0 "No Action" ;
VAL_ 489 VSELatAccV 1 "Invalid" 0 "Valid" ;
VAL_ 489 VSEAct 1 "true" 0 "false" ;
VAL_ 489 VhDynCntlSysSt 7 "Driver Disabled" 6 "Enhanced Operation" 5 "Calibrating" 4 "Warming Up" 3 "Permanently Failed" 2 "Temporarily Inhibited" 1 "Reduced Function" 0 "Normal Operation" ;
VAL_ 489 VehDynYawRateV 1 "Invalid" 0 "Valid" ;
VAL_ 489 TrnsBrkSysCltchRelRqd 1 "true" 0 "false" ;
VAL_ 489 TracCntrlSysDrIntnt 1 "Enabled" 0 "Disabled" ;
VAL_ 489 VehDynOvrUndrStrV 1 "Invalid" 0 "Valid" ;
VAL_ 489 TCSysEnbld 1 "true" 0 "false" ;
VAL_ 489 TCSysAtv 1 "true" 0 "false" ;
VAL_ 489 BrkPdlDrvAppPrsDetcdV 1 "Invalid" 0 "Valid" ;
VAL_ 489 BrkPdlDrvAppPrsDetcd 1 "true" 0 "false" ;
VAL_ 489 ACCBrkngAct 1 "true" 0 "false" ;
VAL_ 489 ABSFld 1 "true" 0 "false" ;
VAL_ 489 ABSAtv 1 "true" 0 "false" ;
VAL_ 761 ABFI_CollPrepSysInhbt 1 "true" 0 "false" ;
VAL_ 761 ABFI_RrVirtlBmprInh 1 "true" 0 "false" ;
VAL_ 761 BrkPdlDrvApplPresV 1 "Invalid" 0 "Valid" ;
VAL_ 761 AutoBrkPTReqStat 0 "Inactive" 1 "Active" 2 "Failed" 3 "Serial Communication Failure" 4 "Unused and Reserved 1" 5 "Unused and Reserved 2" 6 "Unused and Reserved 3" 7 "Unused and Reserved 4" ;
VAL_ 761 WhlSpdSnsgDTCStat 4 "Diagnostic Failed" 3 "Diagnostic Passed" 2 "No Status to Report" 1 "Critically Disabled" 0 "Not Supported" ;
VAL_ 761 SprTireSt 2 "Spare Detected" 1 "No Spare Detected" 0 "Undetermined" ;
VAL_ 249 TrnsDrvlneTqShpDisRq 1 "true" 0 "false" ;
VAL_ 249 TrnsOtptRotRCRstOcc 1 "true" 0 "false" ;
VAL_ 249 TrnsOtptRotRCV 1 "Invalid" 0 "Valid" ;
VAL_ 249 TrnsOtptShftAngVelSnrPr 1 "true" 0 "false" ;
VAL_ 249 TrnsOutShftAngVelV 1 "Invalid" 0 "Valid" ;
VAL_ 249 TrnsOvrallEstTorqRatioV 1 "Invalid" 0 "Valid" ;
VAL_ 501 TrnsShftLvrPos 15 "Lever Position Unknown" 11 "Forward Range H" 10 "Forward Range G" 9 "Forward Range F" 8 "Forward Range E" 7 "Forward Range D" 6 "Forward Range C" 5 "Forward Range B" 4 "Forward Range A" 3 "Neutral Range" 2 "Reverse Range" 1 "Park Range" 0 "Between Ranges" ;
VAL_ 501 EngRecDwnshftIO 1 "true" 0 "false" ;
VAL_ 501 TrnsPattSelEcnMdOCm 1 "true" 0 "false" ;
VAL_ 501 CltStartSwAtvV 1 "Invalid" 0 "Valid" ;
VAL_ 501 CltStartSwAtv 1 "true" 0 "false" ;
VAL_ 501 CltchPdlActPosV 1 "Invalid" 0 "Valid" ;
VAL_ 501 TrnsEngdStateV 1 "Invalid" 0 "Valid" ;
VAL_ 501 TrnsEngdState 3 "Operating State Not Reached" 2 "Transmission Engaged in Reverse" 1 "Transmission Engaged in Forward" 0 "Transmission Not Engaged" ;
VAL_ 501 TrnsShftLvrLckRqd 1 "true" 0 "false" ;
VAL_ 501 TransTUDMdStat 2 "Electronic Range Select Active" 1 "Driver Shift Control Active" 0 "No Activation" ;
VAL_ 501 TrnCrpMdAtv 1 "true" 0 "false" ;
VAL_ 501 TrnsSkpShftIO 1 "true" 0 "false" ;
VAL_ 501 TrnsSftMdStat 3 "Automatic Grade Braking Mode" 2 "Lift-Foot Cornering Mode" 1 "Performance Mode" 0 "No Override Mode" ;
VAL_ 501 TrnsRngInhbtStat 4 "Diagnostic Inhibit Active" 3 "Driveline Not Engaged" 2 "Transmission Range Re-Selection Req" 1 "Transmission Inhibit Active" 0 "No Range Inhibit Active" ;
VAL_ 501 TopTrvlCltchSwActV 1 "Invalid" 0 "Valid" ;
VAL_ 501 TopTrvlCltchSwAct 1 "true" 0 "false" ;
VAL_ 501 EngRecmndUpshftIO 1 "true" 0 "false" ;
VAL_ 501 DrvtShftCntrlTrgtGear 8 "Eighth Gear" 7 "Seventh Gear" 6 "Sixth Gear" 5 "Fifth Gear" 4 "Fourth Gear" 3 "Third Gear" 2 "Second Gear" 1 "First Gear" 0 "Not Supported" ;
VAL_ 501 DrShftCntrlReqDndIO 1 "true" 0 "false" ;
VAL_ 501 TrnShftPtrnActStat 6 "PT Protection Pattern Active" 5 "PT Non-Protection Pattern Active" 4 "Shift Pattern 4 Active" 3 "Shift Pattern 3 Active" 2 "Shift Pattern 2 Active" 1 "Shift Pattern 1 Active" 0 "Default Shift Pattern Active" ;
VAL_ 501 TrnsFldPrsPrsnt 1 "true" 0 "false" ;
VAL_ 501 TrnsShftLvrPosV 1 "Invalid" 0 "Valid" ;
VAL_ 501 TrnsTrqCnvCltCmndMd 7 "Not Supported" 3 "Locked" 2 "Controlled Slip" 1 "Transitioning" 0 "Unlocked" ;
VAL_ 501 AutoTransComndGear 15 "Park Gear" 14 "Reverse Gear" 13 "Neutral Gear" 12 "CVT Forward Gear" 11 "EVT Mode 2" 10 "EVT Mode 1" 8 "Eighth Gear" 7 "Seventh Gear" 6 "Sixth Gear" 5 "Fifth Gear" 4 "Fourth Gear" 3 "Third Gear" 2 "Second Gear" 1 "First Gear" 0 "Not Supported" ;
VAL_ 501 AutoTransGrSftDirect 2 "Downshift in Progress" 1 "Upshift in Progress" 0 "No Shift in Progress" ;
VAL_ 501 TransEstGear 15 "Park Gear" 14 "Reverse Gear" 13 "Neutral Gear" 12 "CVT Forward Gear" 11 "EVT Mode 2" 10 "EVT Mode 1" 8 "Eighth Gear" 7 "Seventh Gear" 6 "Sixth Gear" 5 "Fifth Gear" 4 "Fourth Gear" 3 "Third Gear" 2 "Second Gear" 1 "First Gear" 0 "Not Supported" ;
VAL_ 501 TransEstGearV 1 "Invalid" 0 "Valid" ;
VAL_ 1225 TrnsThrmlMngmntStat 2 "Driver Intervention Requested" 1 "Countermeasures Active" 0 "Normal" ;
VAL_ 1225 TrnsNEmsRltMalfActv 1 "true" 0 "false" ;
VAL_ 1225 TransOilTempSensPres 1 "true" 0 "false" ;
VAL_ 1225 TrnEmsMlfAtv 1 "true" 0 "false" ;
VAL_ 1225 TrnOilTmpV 1 "Invalid" 0 "Valid" ;
VAL_ 1225 TERDTC_SysDes 15 "U3-Network Codes Reserved" 14 "U2-Network Codes Reserved" 13 "U1-Network Codes MFG Controlled" 12 "U0-Network Codes SAE Controlled" 11 "B3-Body Codes Reserved" 10 "B2-Body Codes Reserved" 9 "B1-Body Codes MFG Controlled" 8 "B0-Body Codes SAE Controlled" 7 "C3-Chassis Codes Reserved" 6 "C2-Chassis Codes Reserved" 5 "C1-Chassis Codes MFG Controlled" 4 "C0-Chassis Codes SAE Controlled" 3 "P3-Powertrain Codes Reserved" 2 "P2-Powertrain Codes Reserved" 1 "P1-Powertrain Codes MFG Controlled" 0 "P0-Powertrain Codes SAE Controlled" ;
VAL_ 298 ChmAct 1 "true" 0 "false" ;
VAL_ 298 DDAjrSwAtvM 0 "Don't Use Data" 1 "Use Data" ;
VAL_ 298 CrshAlrtDrvrSlctdType 0 "Chime" 1 "Seat" ;
VAL_ 298 PsSbltAtcV 1 "Invalid" 0 "Valid" ;
VAL_ 298 PsSbltAtc 1 "true" 0 "false" ;
VAL_ 298 TrlrBrkDsplyAct 1 "true" 0 "false" ;
VAL_ 298 RdSpdCatType 3 "all speed categories 0 - 50 km/h" 2 "all speed categories 51-80 km/h" 1 "all speed categories 81-130 km/h" 0 "all speed categories > 130 km/h" ;
VAL_ 298 LnCat 3 "Four Or More Lanes" 2 "Two Or Three Lanes" 1 "One lane" 0 "no info available" ;
VAL_ 298 FncRdClass 7 "COLLECTOR" 6 "ALLEY" 5 "ARTERIAL" 4 "HIGHWAY" 3 "PED-MALL" 2 "FREEWAY" 1 "SFREEWAY" 0 "LOCAL (Residential Road)" ;
VAL_ 298 SprtLnRd 1 "true" 0 "false" ;
VAL_ 298 CntrldAccRd 1 "true" 0 "false" ;
VAL_ 298 BldUpArDet 1 "true" 0 "false" ;
VAL_ 298 MpDataAvlbl 1 "true" 0 "false" ;
VAL_ 298 SusCustStngReq 2 "Sport" 1 "Normal/Off" 0 "No Action" ;
VAL_ 298 StrCustStngReq 2 "Sport" 1 "Normal/Off" 0 "No Action" ;
VAL_ 298 RstrCustFctrDef 1 "Restore Defaults" 0 "No Action" ;
VAL_ 298 DrvlnCustStngReq 2 "Sport" 1 "Normal/Off" 0 "No Action" ;
VAL_ 298 ChmMstrVDA 1 "VirtualDeviceAvailable" 0 "VirtualDeviceUnavailable" ;
VAL_ 298 IPCVDA 1 "VirtualDeviceAvailable" 0 "VirtualDeviceUnavailable" ;
VAL_ 298 HeadUpDispVDA 1 "VirtualDeviceAvailable" 0 "VirtualDeviceUnavailable" ;
VAL_ 298 HapticSeatVDA 1 "VirtualDeviceAvailable" 0 "VirtualDeviceUnavailable" ;
VAL_ 298 RRDoorAjarSwAct 1 "true" 0 "false" ;
VAL_ 298 PDAjrSwAtv 1 "true" 0 "false" ;
VAL_ 298 DDAjrSwAtv 1 "true" 0 "false" ;
VAL_ 298 TrlrHWIntrfcVDA 1 "VirtualDeviceAvailable" 0 "VirtualDeviceUnavailable" ;
VAL_ 298 DrId 7 "Unknown" 6 "Driver #7" 5 "Driver #6" 4 "Driver #5" 3 "Driver #4" 2 "Driver #3" 1 "Driver #2" 0 "Driver #1" ;
VAL_ 298 EnrgMgtLdShdRq 4 "Load Shed Level 4" 3 "Load Shed Level 3" 2 "Load Shed Level 2" 1 "Load Shed Level 1" 0 "No Load Shedding" ;
VAL_ 298 DrSbltAtcV 1 "Invalid" 0 "Valid" ;
VAL_ 298 TrlrHtchSwAtv 1 "true" 0 "false" ;
VAL_ 298 TreInfMonSysRstReq 1 "true" 0 "false" ;
VAL_ 298 HUDActv 1 "true" 0 "false" ;
VAL_ 298 BatVltV 1 "Invalid" 0 "Valid" ;
VAL_ 298 RLDoorAjarSwAct 1 "true" 0 "false" ;
VAL_ 298 DrSbltAtc 1 "true" 0 "false" ;
VAL_ 1241 FSERDTC_SysDes 15 "U3-Network Codes Reserved" 14 "U2-Network Codes Reserved" 13 "U1-Network Codes MFG Controlled" 12 "U0-Network Codes SAE Controlled" 11 "B3-Body Codes Reserved" 10 "B2-Body Codes Reserved" 9 "B1-Body Codes MFG Controlled" 8 "B0-Body Codes SAE Controlled" 7 "C3-Chassis Codes Reserved" 6 "C2-Chassis Codes Reserved" 5 "C1-Chassis Codes MFG Controlled" 4 "C0-Chassis Codes SAE Controlled" 3 "P3-Powertrain Codes Reserved" 2 "P2-Powertrain Codes Reserved" 1 "P1-Powertrain Codes MFG Controlled" 0 "P0-Powertrain Codes SAE Controlled" ;
VAL_ 1241 FuelSysEmsRldMlfAtv 1 "true" 0 "false" ;
VAL_ 1009 OtsAirTmpCrValMsk 0 "Don't Use Data" 1 "Use Data" ;
VAL_ 1009 ClmtCtrlHtrEngRunRq 1 "Engine Run Requested" 0 "No Action" ;
VAL_ 1009 ACCmEngRunReq 1 "Engine Run Requested" 0 "No Action" ;
VAL_ 1009 OutAirTempVDA 1 "VirtualDeviceAvailable" 0 "VirtualDeviceUnavailable" ;
VAL_ 1009 OtsAirTmpCrValV 1 "Invalid" 0 "Valid" ;
VAL_ 1009 EngOffTmVDA 1 "VirtualDeviceAvailable" 0 "VirtualDeviceUnavailable" ;
VAL_ 1009 ClntCircPmpRq 1 "On" 0 "Off" ;
VAL_ 1009 EngOffTmExtRngV 1 "Invalid" 0 "Valid" ;
VAL_ 1009 PF_MinIdlBstLvlReq 3 "Boost Level 3" 2 "Boost Level 2" 1 "Boost Level 1" 0 "No Boost Requested" ;
VAL_ 1019 FuelAlchlCompAdptnPrg 1 "true" 0 "false" ;
VAL_ 1019 FuelLvlEmnsRelStat 0 "Valid" 1 "Invalid" ;
VAL_ 1019 EmnsRelFuelLvlLw 1 "true" 0 "false" ;
VAL_ 1019 EngFuelCntlState 2 "Stoichiometric Closed Loop" 1 "Non-Stoichiometric Closed Loop" 0 "Open Loop" ;
VAL_ 1019 FuelAlcoholCompV 1 "Invalid" 0 "Valid" ;
VAL_ 1417 ETC_EngOpMd 1 "Half Cylinders" 0 "All cylinders" ;
VAL_ 1219 DslExNxEmWrngIndRq 15 "Warning Level 15" 14 "Warning Level 14" 13 "Warning Level 13" 12 "Warning Level 12" 11 "Warning Level 11" 10 "Warning Level 10" 9 "Warning Level 9" 8 "Warning Level 8" 7 "Warning Level 7" 6 "Warning Level 6" 5 "Warning Level 5" 4 "Warning Level 4" 3 "Warning Level 3" 2 "Warning Level 2" 1 "Warning Level 1" 0 "No Indication" ;
VAL_ 1219 DslExFldTpWrngIndRq 15 "Warning Level 15" 14 "Warning Level 14" 13 "Warning Level 13" 12 "Warning Level 12" 11 "Warning Level 11" 10 "Warning Level 10" 9 "Warning Level 9" 8 "Warning Level 8" 7 "Warning Level 7" 6 "Warning Level 6" 5 "Warning Level 5" 4 "Warning Level 4" 3 "Warning Level 3" 2 "Warning Level 2" 1 "Warning Level 1" 0 "No Indication" ;
VAL_ 1219 DslExhFldQlyWrngIReq 15 "Warning Level 15" 14 "Warning Level 14" 13 "Warning Level 13" 12 "Warning Level 12" 11 "Warning Level 11" 10 "Warning Level 10" 9 "Warning Level 9" 8 "Warning Level 8" 7 "Warning Level 7" 6 "Warning Level 6" 5 "Warning Level 5" 4 "Warning Level 4" 3 "Warning Level 3" 2 "Warning Level 2" 1 "Warning Level 1" 0 "No Indication" ;
VAL_ 1219 DslExhFldWrngIdRqER 15 "Warning Level 15" 14 "Warning Level 14" 13 "Warning Level 13" 12 "Warning Level 12" 11 "Warning Level 11" 10 "Warning Level 10" 9 "Warning Level 9" 8 "Warning Level 8" 7 "Warning Level 7" 6 "Warning Level 6" 5 "Warning Level 5" 4 "Warning Level 4" 3 "Warning Level 3" 2 "Warning Level 2" 1 "Warning Level 1" 0 "No Indication" ;
VAL_ 1219 DslExFldCnWrngIndRq 15 "Warning Level 15" 14 "Warning Level 14" 13 "Warning Level 13" 12 "Warning Level 12" 11 "Warning Level 11" 10 "Warning Level 10" 9 "Warning Level 9" 8 "Warning Level 8" 7 "Warning Level 7" 6 "Warning Level 6" 5 "Warning Level 5" 4 "Warning Level 4" 3 "Warning Level 3" 2 "Warning Level 2" 1 "Warning Level 1" 0 "No Indication" ;
VAL_ 1219 DslExhFldDiagWrnIdRq 7 "Warning Level 7" 6 "Warning Level 6" 5 "Warning Level 5" 4 "Warning Level 4" 3 "Warning Level 3" 2 "Warning Level 2" 1 "Warning Level 1" 0 "No Indication" ;
VAL_ 1219 DslEmnsOBDMrkt 1 "EURO5/6" 0 "USEPA TIER 2 / CALIFORNIA LEV II" ;
VAL_ 1265 PTSysHzrdLghtReq 1 "true" 0 "false" ;
VAL_ 1265 EngOffTmPTV 1 "Invalid" 0 "Valid" ;
VAL_ 1265 EngOffTmPTM 1 "Use Data" 0 "Don't Use Data" ;
VAL_ 1231 DslExhFluidLvlPrcntV 1 "Invalid" 0 "Valid" ;
VAL_ 647 DrvMntnMdCmnd 1 "true" 0 "false" ;
VAL_ 647 DrvHldMdCmnd 1 "true" 0 "false" ;
VAL_ 647 DrvWntrMdCmd 1 "true" 0 "false" ;
VAL_ 647 DrvTwHaulMdCmd 1 "true" 0 "false" ;
VAL_ 647 DrvSprtMdCmd 1 "true" 0 "false" ;
VAL_ 647 DrvEconMdCmd 1 "true" 0 "false" ;
VAL_ 647 EngCntrlDtrmdTrfCRngV 1 "Invalid" 0 "Valid" ;
VAL_ 647 EngCntrlDtrmdTrfCRng 3 "Neutral" 2 "Unused and Reserved" 1 "Low" 0 "High" ;
VAL_ 647 EngCntrlUtldTrnCsRng 3 "Neutral" 2 "Unused and Reserved" 1 "Low" 0 "High" ;
VAL_ 647 EngCntrlUtldTrnCsRgIn 1 "true" 0 "false" ;
VAL_ 723 PerfTrcEngSpdRqStat 6 "Control System Failure Permanent" 5 "Control System Failure Temporary" 4 "Serial Data Failure Permanent" 3 "Serial Data Failure Temporary" 2 "Lost Arbitration" 1 "Request Honored" 0 "No Request" ;
VAL_ 723 PerfTrcEngSpdLmtStat 3 "Rate & Value Limited" 2 "Value Limited" 1 "Rate Limited" 0 "Not Limited" ;
VAL_ 723 PerfTrcTrqRqStat 6 "Control System Failure Permanent" 5 "Control System Failure Temporary" 4 "Serial Data Failure Permanent" 3 "Serial Data Failure Temporary" 2 "Lost Arbitration" 1 "Request Honored" 0 "No Request" ;
VAL_ 723 PerfTrcTrqLmtStat 3 "Rate & Value Limited" 2 "Value Limited" 1 "Rate Limited" 0 "Not Limited" ;
VAL_ 1020 OtsAirTmpCrValMsk 0 "Don't Use Data" 1 "Use Data" ;
VAL_ 1020 OtsAirTmpV 1 "Invalid" 0 "Valid" ;
VAL_ 1020 OtsAirTmpCrValV 1 "Invalid" 0 "Valid" ;
VAL_ 1020 EngInltSpcfcHmdtyV 1 "Invalid" 0 "Valid" ;
VAL_ 1020 EngInltSpcfcHmdtyM 0 "Don't Use Data" 1 "Use Data" ;
VAL_ 1088 bcm_fgd 255 "ERROR" 254 "NO_VALUE" ;
VAL_ 1088 bcm_balancing_cnt 255 "ERROR" 254 "NO_VALUE" ;
VAL_ 1088 bcm_vbus_neg 4095 "ERROR" 4094 "NO_VALUE" ;
VAL_ 1088 bcm_vbus_pos 4095 "ERROR" 4094 "NO_VALUE" ;
VAL_ 1088 bcm_mainc_step 14 "ALL_OPEN_SHUTDOWN" 13 "SHUTDOWN_REQUEST" 12 "MAIN_P_CLOSED_CHARGE" 11 "MAIN_PN_CLOSED_DRIVE" 10 "FAILED_MAINP_OPEN" 9 "OPEN_MAINR" 8 "CLOSE_MAINP" 7 "WAIT_PRECHARGE" 6 "FAILED_MAINN_OPEN" 5 "CLOSE_MAINN" 4 "FAILED_MAINN_WELD" 3 "FAILED_MAINR_OPEN" 2 "CLOSE_MAINR" 1 "FAILED_MAINP_OR_R_WELD" 0 "ALL_OPEN" ;
VAL_ 1088 bcm_ibat2 65534 "NO_VALUE" 65535 "ERROR" ;
VAL_ 1072 bcm_lvbat 255 "ERROR" 254 "NO_VALUE" ;
VAL_ 1072 bcm_cell_vmin 8191 "ERROR" 8190 "NO_VALUE" ;
VAL_ 1072 bcm_cell_vmax 8191 "ERROR" 8190 "NO_VALUE" ;
VAL_ 1072 bcm_cell_tmin 255 "ERROR" 254 "NO_VALUE" ;
VAL_ 1072 bcm_cell_tmax 255 "ERROR" 254 "NO_VALUE" ;
VAL_ 1056 bcm_t_coolant 255 "ERROR" 254 "NO_VALUE" ;
VAL_ 1056 bcm_chg_buf 255 "ERROR" 254 "NO_VALUE" ;
VAL_ 1056 bcm_dis_buf 255 "ERROR" 254 "NO_VALUE" ;
VAL_ 1056 bcm_dis_max 4095 "ERROR" 4094 "NO_VALUE" ;
VAL_ 1056 bcm_chg_max 4095 "ERROR" 4094 "NO_VALUE" ;
VAL_ 1040 bcm_lls_status 3 "OOR_HIGH" 2 "OOR_LOW" 1 "FAULT" 0 "OK" ;
VAL_ 1040 bcm_vbat 4095 "ERROR" 4094 "NO_VALUE" ;
VAL_ 1040 bcm_soc 255 "ERROR" 254 "NO_VALUE" ;
VAL_ 1040 bcm_mainc_stat 2 "FAILURE" 1 "CLOSED" 0 "OPEN" ;
VAL_ 1040 bcm_ibat 65534 "NO_VALUE" 65535 "ERROR" ;
VAL_ 1040 bcm_gfd 4095 "ERROR" 4094 "NO_VALUE" ;
VAL_ 1040 bcm_chgc_stat 2 "FAILURE" 1 "CLOSED" 0 "OPEN" ;
VAL_ 1040 bcm_alarm 3 "TYPE3" 2 "TYPE2" 1 "TYPE1" 0 "NONE" ;
VAL_ 1120 bcm_dtc_001 0 " - " 11276288 "DTC_VEPO" 11276289 "DTC_HSC_MISSING" 11460608 "DTC_NVM_SOC" 11460609 "DTC_NVM_KOT" 11460610 "DTC_NVM_DTC" 11460611 "DTC_NVM_SOC_CORRECTION" 11460612 "DTC_NVM_APP_SCRATCHPAD" 11517962 "DTC_LOOPTIME_TASK_A" 11517963 "DTC_LOOPTIME_TASK_B" 11517964 "DTC_LOOPTIME_TASK_C" 11517965 "DTC_LOOPTIME_TASK_D" 11517966 "DTC_LOOPTIME_TASK_E" 11517967 "DTC_LOOPTIME_TASK_F" 11323904 "DTC_INTERLOCK_A_FAILED_LOW" 11323905 "DTC_INTERLOCK_A_FAILED_HIGH" 11324160 "DTC_INTERLOCK_B_FAILED_LOW" 11324161 "DTC_INTERLOCK_B_FAILED_HIGH" 15728640 "DTC_EPO" 16498688 "DTC_BRUSA_MISSING" 16498689 "DTC_BRUSA_IDC" 16498690 "DTC_BRUSA_REQ_VS_CMD" 16433152 "DTC_AKERWADE_MISSING" 16433153 "DTC_AKERWADE_IDC" 16433154 "DTC_AKERWADE_REQ_VS_CMD" 16564224 "DTC_CHGLEAR_MISSING" 16564225 "DTC_CHGLEAR_IDC" 16564226 "DTC_CHGLEAR_REQ_VS_CMD" 16522240 "DTC_CSM_MISSING" 16522752 "DTC_CSM_VBAT" 16522753 "DTC_CSM_VPOS" 16522754 "DTC_CSM_VNEG" 16522755 "DTC_CSM_CPOS" 16522756 "DTC_CSM_CNEG" 16522757 "DTC_CSM_APOS" 16522758 "DTC_CSM_ANEG" 16522759 "DTC_CSM_FUSE_HI" 16522760 "DTC_CSM_FUSE_LO" 16521728 "DTC_CSM_ASIC" 16521729 "DTC_CSM_AILO" 16521730 "DTC_CSM_AIHI" 16520957 "DTC_LEAKAGE_DETECT_FAULT" 16522444 "DTC_REALTIMECLOCK_FAULT" 16520945 "DTC_CSM_LEAK_FAIL_CALC" 16520946 "DTC_CSM_LEAK_FAIL_HW" 16520947 "DTC_CSM_LEAK_EXT_SHORT" 16520948 "DTC_CSM_LEAK_MID_PACK_SHORT" 16520949 "DTC_CSM_LEAK_ERROR" 16520950 "DTC_CSM_LEAK_UNKNOWN" 16523008 "DTC_CSM_VER_MISMATCH" 16523009 "DTC_CSM_DTC_SET" 16523010 "DTC_CSM_CAL_FAULT" 16560128 "DTC_IBAT_MISMATCH" 16576512 "DTC_DIS_MAX_I2T" 16576513 "DTC_CHG_MAX_I2T" 16576768 "DTC_DIS_WARNING_I2T" 16576769 "DTC_CHG_WARNING_I2T" 11296784 "DTC_SAEJ1772_PROX_DECT_OOR_HI" 11296785 "DTC_SAEJ1772_PROX_DECT_OOR_LO" 11296800 "DTC_SAEJ1772_PILOT_PWM_OOR_HI" 11296801 "DTC_SAEJ1772_PILOT_PWM_OOR_LO" 11296802 "DTC_SAEJ1772_PILOT_PWM_DIG_COMM" 11296803 "DTC_SAEJ1772_PILOT_PWM_IR_ERR" 16175360 "DTC_FGD1_NO_SENSOR" 16175361 "DTC_FGD1_OOR_HI" 16175362 "DTC_FGD1_OOR_LO" 16175363 "DTC_FGD1_FAULT" 16175616 "DTC_FGD2_NO_SENSOR" 16175617 "DTC_FGD2_OOR_HI" 16175618 "DTC_FGD2_OOR_LO" 16175619 "DTC_FGD2_FAULT" 16171008 "DTC_CONT_OPEN" 16171009 "DTC_CONT_CLOSE" 16171010 "DTC_CONT_OPEN_CURRENT" 16171264 "DTC_CONT_CLOSE_ON_RESET" 16171265 "DTC_CONT_CLOSE_SIG_FAILED" 16171520 "DTC_PRECHARGE_TIMEOUT" 16171777 "DTC_CONT_MPOS_WELD_AT_SU" 16171778 "DTC_CONT_MNEG_WELD_AT_SU" 16171780 "DTC_CONT_CPOS_WELD_AT_SU" 16171781 "DTC_CONT_CNEG_WELD_AT_SU" 16171782 "DTC_CONT_ANEG_WELD_AT_SU" 16171783 "DTC_CONT_APOS_WELD_AT_SU" 16172033 "DTC_CONT_MPOS_WELD_AT_SD" 16172034 "DTC_CONT_MNEG_WELD_AT_SD" 16172036 "DTC_CONT_CPOS_WELD_AT_SD" 16172037 "DTC_CONT_CNEG_WELD_AT_SD" 16172038 "DTC_CONT_ANEG_WELD_AT_SD" 16172039 "DTC_CONT_APOS_WELD_AT_SD" 16172289 "DTC_CONT_MPOS_OPEN" 16172290 "DTC_CONT_MNEG_OPEN" 16172291 "DTC_CONT_MPRE_OPEN" 16172292 "DTC_CONT_CPOS_OPEN" 16172293 "DTC_CONT_CNEG_OPEN" 16172294 "DTC_CONT_APOS_OPEN" 16172295 "DTC_CONT_ANEG_OPEN" 16172545 "DTC_CONT_MPOS_VDIF" 16172546 "DTC_CONT_MNEG_VDIF" 16172548 "DTC_CONT_CPOS_VDIF" 16172549 "DTC_CONT_CNEG_VDIF" 16172550 "DTC_CONT_APOS_VDIF" 16172551 "DTC_CONT_ANEG_VDIF" 16174848 "DTC_HVIL" 16174849 "DTC_LVBAT_LO" 16174850 "DTC_LVBAT_HI" 16174851 "DTC_LVBAT_ERR" 16523520 "DTC_LEMLO_OOR_HI" 16523521 "DTC_LEMLO_OOR_LO" 16523522 "DTC_LEMLO_FAULT" 16523776 "DTC_LEMHI_OOR_HI" 16523777 "DTC_LEMHI_OOR_LO" 16523778 "DTC_LEMHI_FAULT" 16496320 "DTC_MBB_TOO_FEW" 16496321 "DTC_MBB_TOO_MANY" 16496352 "DTC_CELL_VMAX_ERR" 16496353 "DTC_CELL_VMIN_ERR" 16496354 "DTC_CELL_VMAX" 16496362 "DTC_CELL_VMAX_SEVERE" 16496355 "DTC_CELL_VMIN" 16496363 "DTC_CELL_VMIN_SEVERE" 16496356 "DTC_MOD_VOLTAGE_COMPARE" 16496336 "DTC_CELL_T_ERR" 16496337 "DTC_CELL_TMAX1" 16496338 "DTC_CELL_TMAX2" 16496339 "DTC_CELL_TMIN" 16497665 "DTC_MBB_01_MISSING" 16497666 "DTC_MBB_02_MISSING" 16497667 "DTC_MBB_03_MISSING" 16497668 "DTC_MBB_04_MISSING" 16497669 "DTC_MBB_05_MISSING" 16497670 "DTC_MBB_06_MISSING" 16497671 "DTC_MBB_07_MISSING" 16497672 "DTC_MBB_08_MISSING" 16497673 "DTC_MBB_09_MISSING" 16497680 "DTC_MBB_10_MISSING" 16497681 "DTC_MBB_11_MISSING" 16497682 "DTC_MBB_12_MISSING" 16497683 "DTC_MBB_13_MISSING" 16497684 "DTC_MBB_14_MISSING" 16497685 "DTC_MBB_15_MISSING" 16497686 "DTC_MBB_16_MISSING" 16497687 "DTC_MBB_17_MISSING" 16497688 "DTC_MBB_18_MISSING" 16497689 "DTC_MBB_19_MISSING" 16497696 "DTC_MBB_20_MISSING" 16497697 "DTC_MBB_21_MISSING" 16497698 "DTC_MBB_22_MISSING" 16497699 "DTC_MBB_23_MISSING" 16497700 "DTC_MBB_24_MISSING" 16498177 "DTC_MBB_01_VFAULT" 16498178 "DTC_MBB_02_VFAULT" 16498179 "DTC_MBB_03_VFAULT" 16498180 "DTC_MBB_04_VFAULT" 16498181 "DTC_MBB_05_VFAULT" 16498182 "DTC_MBB_06_VFAULT" 16498183 "DTC_MBB_07_VFAULT" 16498184 "DTC_MBB_08_VFAULT" 16498185 "DTC_MBB_09_VFAULT" 16498192 "DTC_MBB_10_VFAULT" 16498193 "DTC_MBB_11_VFAULT" 16498194 "DTC_MBB_12_VFAULT" 16498195 "DTC_MBB_13_VFAULT" 16498196 "DTC_MBB_14_VFAULT" 16498197 "DTC_MBB_15_VFAULT" 16498198 "DTC_MBB_16_VFAULT" 16498199 "DTC_MBB_17_VFAULT" 16498200 "DTC_MBB_18_VFAULT" 16498201 "DTC_MBB_19_VFAULT" 16498208 "DTC_MBB_20_VFAULT" 16498209 "DTC_MBB_21_VFAULT" 16498210 "DTC_MBB_22_VFAULT" 16498211 "DTC_MBB_23_VFAULT" 16498212 "DTC_MBB_24_VFAULT" 16497921 "DTC_MBB_01_TFAULT" 16497922 "DTC_MBB_02_TFAULT" 16497923 "DTC_MBB_03_TFAULT" 16497924 "DTC_MBB_04_TFAULT" 16497925 "DTC_MBB_05_TFAULT" 16497926 "DTC_MBB_06_TFAULT" 16497927 "DTC_MBB_07_TFAULT" 16497928 "DTC_MBB_08_TFAULT" 16497929 "DTC_MBB_09_TFAULT" 16497936 "DTC_MBB_10_TFAULT" 16497937 "DTC_MBB_11_TFAULT" 16497938 "DTC_MBB_12_TFAULT" 16497939 "DTC_MBB_13_TFAULT" 16497940 "DTC_MBB_14_TFAULT" 16497941 "DTC_MBB_15_TFAULT" 16497942 "DTC_MBB_16_TFAULT" 16497943 "DTC_MBB_17_TFAULT" 16497944 "DTC_MBB_18_TFAULT" 16497945 "DTC_MBB_19_TFAULT" 16497952 "DTC_MBB_20_TFAULT" 16497953 "DTC_MBB_21_TFAULT" 16497954 "DTC_MBB_22_TFAULT" 16497955 "DTC_MBB_23_TFAULT" 16497956 "DTC_MBB_24_TFAULT" 15785984 "DTC_PRECHARGE_ENERGY" 15785985 "DTC_PRT_FAILED" 15785986 "DTC_PRT_OVERTEMP" 15785987 "DTC_PRT_PROHIBIT" 16556032 "DTC_COOLANT_TEMP_OOR_HI" 16556033 "DTC_COOLANT_TEMP_OOR_LO" 16252928 "DTC_KEY_OFF_TIME_ERROR" 16506880 "DTC_VBAT_MISMATCH" 16506881 "DTC_VBAT_VMAX" 16506882 "DTC_VBAT_VMIN" 16506883 "DTC_PACK_FUSE" 15798544 "DTC_LLS1_OOR_HI" 15798545 "DTC_LLS1_OOR_LO" 15798546 "DTC_LLS1_FAULT" 15798816 "DTC_LLS2_OOR_HI" 15798817 "DTC_LLS2_OOR_LO" 15798818 "DTC_LLS2_FAULT" 14479360 "DTC_CFL_HEARTBEAT" 14479361 "DTC_CFL_FAULT" 14479362 "DTC_CFL_FAULT_LATCH" 13635584 "DTC_CONT_A_FAILED_HI" 13635585 "DTC_CONT_A_FAILED_LO" 13635586 "DTC_CONT_B_FAILED_HI" 13635587 "DTC_CONT_B_FAILED_LO" 13635588 "DTC_CONT_C_FAILED_HI" 13635589 "DTC_CONT_C_FAILED_LO" 13635590 "DTC_CONT_D_FAILED_HI" 13635591 "DTC_CONT_D_FAILED_LO" 13635592 "DTC_CONT_E_FAILED_HI" 13635593 "DTC_CONT_E_FAILED_LO" 13635594 "DTC_CONT_F_FAILED_HI" 13635595 "DTC_CONT_F_FAILED_LO" 13635596 "DTC_CONT_G_FAILED_HI" 13635597 "DTC_CONT_G_FAILED_LO" 13635598 "DTC_LSD_A_FAILED_HI" 13635599 "DTC_LSD_A_FAILED_LO" 13635600 "DTC_LSD_B_FAILED_HI" 13635601 "DTC_LSD_B_FAILED_LO" 13635602 "DTC_LSD_C_FAILED_HI" 13635603 "DTC_LSD_C_FAILED_LO" 13635606 "DTC_CONT_PWR_FAILED_HI" 13635607 "DTC_CONT_PWR_FAILED_LO" 13635608 "DTC_LSD_PUMP_FAILED_HI" 13635609 "DTC_LSD_PUMP_FAILED_LO" 13635610 "DTC_CHG_A_ENABLE_FAILED_HI" 13635611 "DTC_CHG_A_ENABLE_FAILED_LO" 13635612 "DTC_CHG_B_ENABLE_FAILED_HI" 13635613 "DTC_CHG_B_ENABLE_FAILED_LO" 13635614 "DTC_SW14V_PWR_FAILED_HI" 13635615 "DTC_SW14V_PWR_FAILED_LO" 13635620 "DTC_HSD_A_FAILED_HI" 13635621 "DTC_HSD_A_FAILED_LO" 13635622 "DTC_HSD_B_FAILED_HI" 13635623 "DTC_HSD_B_FAILED_LO" 13692968 "DTC_CONT_HPWR_FAILED_HI" 13692969 "DTC_CONT_HPWR_FAILED_LO" 13692970 "DTC_CONT_HPWR_OOR_HI" 13692971 "DTC_CONT_HPWR_OOR_LO" 13635616 "DTC_5V_PWR_OOR_HI" 13635617 "DTC_5V_PWR_OOR_LO" 14606336 "DTC_NVM_WRITE_TO" 14606337 "DTC_NVM_READ_TO" 14614528 "DTC_SPI_DIG_POT_FAULT" ;
VAL_ 1120 bcm_dtc_002 0 " - " 11276288 "DTC_VEPO" 11276289 "DTC_HSC_MISSING" 11460608 "DTC_NVM_SOC" 11460609 "DTC_NVM_KOT" 11460610 "DTC_NVM_DTC" 11460611 "DTC_NVM_SOC_CORRECTION" 11460612 "DTC_NVM_APP_SCRATCHPAD" 11517962 "DTC_LOOPTIME_TASK_A" 11517963 "DTC_LOOPTIME_TASK_B" 11517964 "DTC_LOOPTIME_TASK_C" 11517965 "DTC_LOOPTIME_TASK_D" 11517966 "DTC_LOOPTIME_TASK_E" 11517967 "DTC_LOOPTIME_TASK_F" 11323904 "DTC_INTERLOCK_A_FAILED_LOW" 11323905 "DTC_INTERLOCK_A_FAILED_HIGH" 11324160 "DTC_INTERLOCK_B_FAILED_LOW" 11324161 "DTC_INTERLOCK_B_FAILED_HIGH" 15728640 "DTC_EPO" 16498688 "DTC_BRUSA_MISSING" 16498689 "DTC_BRUSA_IDC" 16498690 "DTC_BRUSA_REQ_VS_CMD" 16433152 "DTC_AKERWADE_MISSING" 16433153 "DTC_AKERWADE_IDC" 16433154 "DTC_AKERWADE_REQ_VS_CMD" 16564224 "DTC_CHGLEAR_MISSING" 16564225 "DTC_CHGLEAR_IDC" 16564226 "DTC_CHGLEAR_REQ_VS_CMD" 16522240 "DTC_CSM_MISSING" 16522752 "DTC_CSM_VBAT" 16522753 "DTC_CSM_VPOS" 16522754 "DTC_CSM_VNEG" 16522755 "DTC_CSM_CPOS" 16522756 "DTC_CSM_CNEG" 16522757 "DTC_CSM_APOS" 16522758 "DTC_CSM_ANEG" 16522759 "DTC_CSM_FUSE_HI" 16522760 "DTC_CSM_FUSE_LO" 16521728 "DTC_CSM_ASIC" 16521729 "DTC_CSM_AILO" 16521730 "DTC_CSM_AIHI" 16520957 "DTC_LEAKAGE_DETECT_FAULT" 16522444 "DTC_REALTIMECLOCK_FAULT" 16520945 "DTC_CSM_LEAK_FAIL_CALC" 16520946 "DTC_CSM_LEAK_FAIL_HW" 16520947 "DTC_CSM_LEAK_EXT_SHORT" 16520948 "DTC_CSM_LEAK_MID_PACK_SHORT" 16520949 "DTC_CSM_LEAK_ERROR" 16520950 "DTC_CSM_LEAK_UNKNOWN" 16523008 "DTC_CSM_VER_MISMATCH" 16523009 "DTC_CSM_DTC_SET" 16523010 "DTC_CSM_CAL_FAULT" 16560128 "DTC_IBAT_MISMATCH" 16576512 "DTC_DIS_MAX_I2T" 16576513 "DTC_CHG_MAX_I2T" 16576768 "DTC_DIS_WARNING_I2T" 16576769 "DTC_CHG_WARNING_I2T" 11296784 "DTC_SAEJ1772_PROX_DECT_OOR_HI" 11296785 "DTC_SAEJ1772_PROX_DECT_OOR_LO" 11296800 "DTC_SAEJ1772_PILOT_PWM_OOR_HI" 11296801 "DTC_SAEJ1772_PILOT_PWM_OOR_LO" 11296802 "DTC_SAEJ1772_PILOT_PWM_DIG_COMM" 11296803 "DTC_SAEJ1772_PILOT_PWM_IR_ERR" 16175360 "DTC_FGD1_NO_SENSOR" 16175361 "DTC_FGD1_OOR_HI" 16175362 "DTC_FGD1_OOR_LO" 16175363 "DTC_FGD1_FAULT" 16175616 "DTC_FGD2_NO_SENSOR" 16175617 "DTC_FGD2_OOR_HI" 16175618 "DTC_FGD2_OOR_LO" 16175619 "DTC_FGD2_FAULT" 16171008 "DTC_CONT_OPEN" 16171009 "DTC_CONT_CLOSE" 16171010 "DTC_CONT_OPEN_CURRENT" 16171264 "DTC_CONT_CLOSE_ON_RESET" 16171265 "DTC_CONT_CLOSE_SIG_FAILED" 16171520 "DTC_PRECHARGE_TIMEOUT" 16171777 "DTC_CONT_MPOS_WELD_AT_SU" 16171778 "DTC_CONT_MNEG_WELD_AT_SU" 16171780 "DTC_CONT_CPOS_WELD_AT_SU" 16171781 "DTC_CONT_CNEG_WELD_AT_SU" 16171782 "DTC_CONT_ANEG_WELD_AT_SU" 16171783 "DTC_CONT_APOS_WELD_AT_SU" 16172033 "DTC_CONT_MPOS_WELD_AT_SD" 16172034 "DTC_CONT_MNEG_WELD_AT_SD" 16172036 "DTC_CONT_CPOS_WELD_AT_SD" 16172037 "DTC_CONT_CNEG_WELD_AT_SD" 16172038 "DTC_CONT_ANEG_WELD_AT_SD" 16172039 "DTC_CONT_APOS_WELD_AT_SD" 16172289 "DTC_CONT_MPOS_OPEN" 16172290 "DTC_CONT_MNEG_OPEN" 16172291 "DTC_CONT_MPRE_OPEN" 16172292 "DTC_CONT_CPOS_OPEN" 16172293 "DTC_CONT_CNEG_OPEN" 16172294 "DTC_CONT_APOS_OPEN" 16172295 "DTC_CONT_ANEG_OPEN" 16172545 "DTC_CONT_MPOS_VDIF" 16172546 "DTC_CONT_MNEG_VDIF" 16172548 "DTC_CONT_CPOS_VDIF" 16172549 "DTC_CONT_CNEG_VDIF" 16172550 "DTC_CONT_APOS_VDIF" 16172551 "DTC_CONT_ANEG_VDIF" 16174848 "DTC_HVIL" 16174849 "DTC_LVBAT_LO" 16174850 "DTC_LVBAT_HI" 16174851 "DTC_LVBAT_ERR" 16523520 "DTC_LEMLO_OOR_HI" 16523521 "DTC_LEMLO_OOR_LO" 16523522 "DTC_LEMLO_FAULT" 16523776 "DTC_LEMHI_OOR_HI" 16523777 "DTC_LEMHI_OOR_LO" 16523778 "DTC_LEMHI_FAULT" 16496320 "DTC_MBB_TOO_FEW" 16496321 "DTC_MBB_TOO_MANY" 16496352 "DTC_CELL_VMAX_ERR" 16496353 "DTC_CELL_VMIN_ERR" 16496354 "DTC_CELL_VMAX" 16496362 "DTC_CELL_VMAX_SEVERE" 16496355 "DTC_CELL_VMIN" 16496363 "DTC_CELL_VMIN_SEVERE" 16496356 "DTC_MOD_VOLTAGE_COMPARE" 16496336 "DTC_CELL_T_ERR" 16496337 "DTC_CELL_TMAX1" 16496338 "DTC_CELL_TMAX2" 16496339 "DTC_CELL_TMIN" 16497665 "DTC_MBB_01_MISSING" 16497666 "DTC_MBB_02_MISSING" 16497667 "DTC_MBB_03_MISSING" 16497668 "DTC_MBB_04_MISSING" 16497669 "DTC_MBB_05_MISSING" 16497670 "DTC_MBB_06_MISSING" 16497671 "DTC_MBB_07_MISSING" 16497672 "DTC_MBB_08_MISSING" 16497673 "DTC_MBB_09_MISSING" 16497680 "DTC_MBB_10_MISSING" 16497681 "DTC_MBB_11_MISSING" 16497682 "DTC_MBB_12_MISSING" 16497683 "DTC_MBB_13_MISSING" 16497684 "DTC_MBB_14_MISSING" 16497685 "DTC_MBB_15_MISSING" 16497686 "DTC_MBB_16_MISSING" 16497687 "DTC_MBB_17_MISSING" 16497688 "DTC_MBB_18_MISSING" 16497689 "DTC_MBB_19_MISSING" 16497696 "DTC_MBB_20_MISSING" 16497697 "DTC_MBB_21_MISSING" 16497698 "DTC_MBB_22_MISSING" 16497699 "DTC_MBB_23_MISSING" 16497700 "DTC_MBB_24_MISSING" 16498177 "DTC_MBB_01_VFAULT" 16498178 "DTC_MBB_02_VFAULT" 16498179 "DTC_MBB_03_VFAULT" 16498180 "DTC_MBB_04_VFAULT" 16498181 "DTC_MBB_05_VFAULT" 16498182 "DTC_MBB_06_VFAULT" 16498183 "DTC_MBB_07_VFAULT" 16498184 "DTC_MBB_08_VFAULT" 16498185 "DTC_MBB_09_VFAULT" 16498192 "DTC_MBB_10_VFAULT" 16498193 "DTC_MBB_11_VFAULT" 16498194 "DTC_MBB_12_VFAULT" 16498195 "DTC_MBB_13_VFAULT" 16498196 "DTC_MBB_14_VFAULT" 16498197 "DTC_MBB_15_VFAULT" 16498198 "DTC_MBB_16_VFAULT" 16498199 "DTC_MBB_17_VFAULT" 16498200 "DTC_MBB_18_VFAULT" 16498201 "DTC_MBB_19_VFAULT" 16498208 "DTC_MBB_20_VFAULT" 16498209 "DTC_MBB_21_VFAULT" 16498210 "DTC_MBB_22_VFAULT" 16498211 "DTC_MBB_23_VFAULT" 16498212 "DTC_MBB_24_VFAULT" 16497921 "DTC_MBB_01_TFAULT" 16497922 "DTC_MBB_02_TFAULT" 16497923 "DTC_MBB_03_TFAULT" 16497924 "DTC_MBB_04_TFAULT" 16497925 "DTC_MBB_05_TFAULT" 16497926 "DTC_MBB_06_TFAULT" 16497927 "DTC_MBB_07_TFAULT" 16497928 "DTC_MBB_08_TFAULT" 16497929 "DTC_MBB_09_TFAULT" 16497936 "DTC_MBB_10_TFAULT" 16497937 "DTC_MBB_11_TFAULT" 16497938 "DTC_MBB_12_TFAULT" 16497939 "DTC_MBB_13_TFAULT" 16497940 "DTC_MBB_14_TFAULT" 16497941 "DTC_MBB_15_TFAULT" 16497942 "DTC_MBB_16_TFAULT" 16497943 "DTC_MBB_17_TFAULT" 16497944 "DTC_MBB_18_TFAULT" 16497945 "DTC_MBB_19_TFAULT" 16497952 "DTC_MBB_20_TFAULT" 16497953 "DTC_MBB_21_TFAULT" 16497954 "DTC_MBB_22_TFAULT" 16497955 "DTC_MBB_23_TFAULT" 16497956 "DTC_MBB_24_TFAULT" 15785984 "DTC_PRECHARGE_ENERGY" 15785985 "DTC_PRT_FAILED" 15785986 "DTC_PRT_OVERTEMP" 15785987 "DTC_PRT_PROHIBIT" 16556032 "DTC_COOLANT_TEMP_OOR_HI" 16556033 "DTC_COOLANT_TEMP_OOR_LO" 16252928 "DTC_KEY_OFF_TIME_ERROR" 16506880 "DTC_VBAT_MISMATCH" 16506881 "DTC_VBAT_VMAX" 16506882 "DTC_VBAT_VMIN" 16506883 "DTC_PACK_FUSE" 15798544 "DTC_LLS1_OOR_HI" 15798545 "DTC_LLS1_OOR_LO" 15798546 "DTC_LLS1_FAULT" 15798816 "DTC_LLS2_OOR_HI" 15798817 "DTC_LLS2_OOR_LO" 15798818 "DTC_LLS2_FAULT" 14479360 "DTC_CFL_HEARTBEAT" 14479361 "DTC_CFL_FAULT" 14479362 "DTC_CFL_FAULT_LATCH" 13635584 "DTC_CONT_A_FAILED_HI" 13635585 "DTC_CONT_A_FAILED_LO" 13635586 "DTC_CONT_B_FAILED_HI" 13635587 "DTC_CONT_B_FAILED_LO" 13635588 "DTC_CONT_C_FAILED_HI" 13635589 "DTC_CONT_C_FAILED_LO" 13635590 "DTC_CONT_D_FAILED_HI" 13635591 "DTC_CONT_D_FAILED_LO" 13635592 "DTC_CONT_E_FAILED_HI" 13635593 "DTC_CONT_E_FAILED_LO" 13635594 "DTC_CONT_F_FAILED_HI" 13635595 "DTC_CONT_F_FAILED_LO" 13635596 "DTC_CONT_G_FAILED_HI" 13635597 "DTC_CONT_G_FAILED_LO" 13635598 "DTC_LSD_A_FAILED_HI" 13635599 "DTC_LSD_A_FAILED_LO" 13635600 "DTC_LSD_B_FAILED_HI" 13635601 "DTC_LSD_B_FAILED_LO" 13635602 "DTC_LSD_C_FAILED_HI" 13635603 "DTC_LSD_C_FAILED_LO" 13635606 "DTC_CONT_PWR_FAILED_HI" 13635607 "DTC_CONT_PWR_FAILED_LO" 13635608 "DTC_LSD_PUMP_FAILED_HI" 13635609 "DTC_LSD_PUMP_FAILED_LO" 13635610 "DTC_CHG_A_ENABLE_FAILED_HI" 13635611 "DTC_CHG_A_ENABLE_FAILED_LO" 13635612 "DTC_CHG_B_ENABLE_FAILED_HI" 13635613 "DTC_CHG_B_ENABLE_FAILED_LO" 13635614 "DTC_SW14V_PWR_FAILED_HI" 13635615 "DTC_SW14V_PWR_FAILED_LO" 13635620 "DTC_HSD_A_FAILED_HI" 13635621 "DTC_HSD_A_FAILED_LO" 13635622 "DTC_HSD_B_FAILED_HI" 13635623 "DTC_HSD_B_FAILED_LO" 13692968 "DTC_CONT_HPWR_FAILED_HI" 13692969 "DTC_CONT_HPWR_FAILED_LO" 13692970 "DTC_CONT_HPWR_OOR_HI" 13692971 "DTC_CONT_HPWR_OOR_LO" 13635616 "DTC_5V_PWR_OOR_HI" 13635617 "DTC_5V_PWR_OOR_LO" 14606336 "DTC_NVM_WRITE_TO" 14606337 "DTC_NVM_READ_TO" 14614528 "DTC_SPI_DIG_POT_FAULT" ;
VAL_ 1120 bcm_dtc_003 0 " - " 11276288 "DTC_VEPO" 11276289 "DTC_HSC_MISSING" 11460608 "DTC_NVM_SOC" 11460609 "DTC_NVM_KOT" 11460610 "DTC_NVM_DTC" 11460611 "DTC_NVM_SOC_CORRECTION" 11460612 "DTC_NVM_APP_SCRATCHPAD" 11517962 "DTC_LOOPTIME_TASK_A" 11517963 "DTC_LOOPTIME_TASK_B" 11517964 "DTC_LOOPTIME_TASK_C" 11517965 "DTC_LOOPTIME_TASK_D" 11517966 "DTC_LOOPTIME_TASK_E" 11517967 "DTC_LOOPTIME_TASK_F" 11323904 "DTC_INTERLOCK_A_FAILED_LOW" 11323905 "DTC_INTERLOCK_A_FAILED_HIGH" 11324160 "DTC_INTERLOCK_B_FAILED_LOW" 11324161 "DTC_INTERLOCK_B_FAILED_HIGH" 15728640 "DTC_EPO" 16498688 "DTC_BRUSA_MISSING" 16498689 "DTC_BRUSA_IDC" 16498690 "DTC_BRUSA_REQ_VS_CMD" 16433152 "DTC_AKERWADE_MISSING" 16433153 "DTC_AKERWADE_IDC" 16433154 "DTC_AKERWADE_REQ_VS_CMD" 16564224 "DTC_CHGLEAR_MISSING" 16564225 "DTC_CHGLEAR_IDC" 16564226 "DTC_CHGLEAR_REQ_VS_CMD" 16522240 "DTC_CSM_MISSING" 16522752 "DTC_CSM_VBAT" 16522753 "DTC_CSM_VPOS" 16522754 "DTC_CSM_VNEG" 16522755 "DTC_CSM_CPOS" 16522756 "DTC_CSM_CNEG" 16522757 "DTC_CSM_APOS" 16522758 "DTC_CSM_ANEG" 16522759 "DTC_CSM_FUSE_HI" 16522760 "DTC_CSM_FUSE_LO" 16521728 "DTC_CSM_ASIC" 16521729 "DTC_CSM_AILO" 16521730 "DTC_CSM_AIHI" 16520957 "DTC_LEAKAGE_DETECT_FAULT" 16522444 "DTC_REALTIMECLOCK_FAULT" 16520945 "DTC_CSM_LEAK_FAIL_CALC" 16520946 "DTC_CSM_LEAK_FAIL_HW" 16520947 "DTC_CSM_LEAK_EXT_SHORT" 16520948 "DTC_CSM_LEAK_MID_PACK_SHORT" 16520949 "DTC_CSM_LEAK_ERROR" 16520950 "DTC_CSM_LEAK_UNKNOWN" 16523008 "DTC_CSM_VER_MISMATCH" 16523009 "DTC_CSM_DTC_SET" 16523010 "DTC_CSM_CAL_FAULT" 16560128 "DTC_IBAT_MISMATCH" 16576512 "DTC_DIS_MAX_I2T" 16576513 "DTC_CHG_MAX_I2T" 16576768 "DTC_DIS_WARNING_I2T" 16576769 "DTC_CHG_WARNING_I2T" 11296784 "DTC_SAEJ1772_PROX_DECT_OOR_HI" 11296785 "DTC_SAEJ1772_PROX_DECT_OOR_LO" 11296800 "DTC_SAEJ1772_PILOT_PWM_OOR_HI" 11296801 "DTC_SAEJ1772_PILOT_PWM_OOR_LO" 11296802 "DTC_SAEJ1772_PILOT_PWM_DIG_COMM" 11296803 "DTC_SAEJ1772_PILOT_PWM_IR_ERR" 16175360 "DTC_FGD1_NO_SENSOR" 16175361 "DTC_FGD1_OOR_HI" 16175362 "DTC_FGD1_OOR_LO" 16175363 "DTC_FGD1_FAULT" 16175616 "DTC_FGD2_NO_SENSOR" 16175617 "DTC_FGD2_OOR_HI" 16175618 "DTC_FGD2_OOR_LO" 16175619 "DTC_FGD2_FAULT" 16171008 "DTC_CONT_OPEN" 16171009 "DTC_CONT_CLOSE" 16171010 "DTC_CONT_OPEN_CURRENT" 16171264 "DTC_CONT_CLOSE_ON_RESET" 16171265 "DTC_CONT_CLOSE_SIG_FAILED" 16171520 "DTC_PRECHARGE_TIMEOUT" 16171777 "DTC_CONT_MPOS_WELD_AT_SU" 16171778 "DTC_CONT_MNEG_WELD_AT_SU" 16171780 "DTC_CONT_CPOS_WELD_AT_SU" 16171781 "DTC_CONT_CNEG_WELD_AT_SU" 16171782 "DTC_CONT_ANEG_WELD_AT_SU" 16171783 "DTC_CONT_APOS_WELD_AT_SU" 16172033 "DTC_CONT_MPOS_WELD_AT_SD" 16172034 "DTC_CONT_MNEG_WELD_AT_SD" 16172036 "DTC_CONT_CPOS_WELD_AT_SD" 16172037 "DTC_CONT_CNEG_WELD_AT_SD" 16172038 "DTC_CONT_ANEG_WELD_AT_SD" 16172039 "DTC_CONT_APOS_WELD_AT_SD" 16172289 "DTC_CONT_MPOS_OPEN" 16172290 "DTC_CONT_MNEG_OPEN" 16172291 "DTC_CONT_MPRE_OPEN" 16172292 "DTC_CONT_CPOS_OPEN" 16172293 "DTC_CONT_CNEG_OPEN" 16172294 "DTC_CONT_APOS_OPEN" 16172295 "DTC_CONT_ANEG_OPEN" 16172545 "DTC_CONT_MPOS_VDIF" 16172546 "DTC_CONT_MNEG_VDIF" 16172548 "DTC_CONT_CPOS_VDIF" 16172549 "DTC_CONT_CNEG_VDIF" 16172550 "DTC_CONT_APOS_VDIF" 16172551 "DTC_CONT_ANEG_VDIF" 16174848 "DTC_HVIL" 16174849 "DTC_LVBAT_LO" 16174850 "DTC_LVBAT_HI" 16174851 "DTC_LVBAT_ERR" 16523520 "DTC_LEMLO_OOR_HI" 16523521 "DTC_LEMLO_OOR_LO" 16523522 "DTC_LEMLO_FAULT" 16523776 "DTC_LEMHI_OOR_HI" 16523777 "DTC_LEMHI_OOR_LO" 16523778 "DTC_LEMHI_FAULT" 16496320 "DTC_MBB_TOO_FEW" 16496321 "DTC_MBB_TOO_MANY" 16496352 "DTC_CELL_VMAX_ERR" 16496353 "DTC_CELL_VMIN_ERR" 16496354 "DTC_CELL_VMAX" 16496362 "DTC_CELL_VMAX_SEVERE" 16496355 "DTC_CELL_VMIN" 16496363 "DTC_CELL_VMIN_SEVERE" 16496356 "DTC_MOD_VOLTAGE_COMPARE" 16496336 "DTC_CELL_T_ERR" 16496337 "DTC_CELL_TMAX1" 16496338 "DTC_CELL_TMAX2" 16496339 "DTC_CELL_TMIN" 16497665 "DTC_MBB_01_MISSING" 16497666 "DTC_MBB_02_MISSING" 16497667 "DTC_MBB_03_MISSING" 16497668 "DTC_MBB_04_MISSING" 16497669 "DTC_MBB_05_MISSING" 16497670 "DTC_MBB_06_MISSING" 16497671 "DTC_MBB_07_MISSING" 16497672 "DTC_MBB_08_MISSING" 16497673 "DTC_MBB_09_MISSING" 16497680 "DTC_MBB_10_MISSING" 16497681 "DTC_MBB_11_MISSING" 16497682 "DTC_MBB_12_MISSING" 16497683 "DTC_MBB_13_MISSING" 16497684 "DTC_MBB_14_MISSING" 16497685 "DTC_MBB_15_MISSING" 16497686 "DTC_MBB_16_MISSING" 16497687 "DTC_MBB_17_MISSING" 16497688 "DTC_MBB_18_MISSING" 16497689 "DTC_MBB_19_MISSING" 16497696 "DTC_MBB_20_MISSING" 16497697 "DTC_MBB_21_MISSING" 16497698 "DTC_MBB_22_MISSING" 16497699 "DTC_MBB_23_MISSING" 16497700 "DTC_MBB_24_MISSING" 16498177 "DTC_MBB_01_VFAULT" 16498178 "DTC_MBB_02_VFAULT" 16498179 "DTC_MBB_03_VFAULT" 16498180 "DTC_MBB_04_VFAULT" 16498181 "DTC_MBB_05_VFAULT" 16498182 "DTC_MBB_06_VFAULT" 16498183 "DTC_MBB_07_VFAULT" 16498184 "DTC_MBB_08_VFAULT" 16498185 "DTC_MBB_09_VFAULT" 16498192 "DTC_MBB_10_VFAULT" 16498193 "DTC_MBB_11_VFAULT" 16498194 "DTC_MBB_12_VFAULT" 16498195 "DTC_MBB_13_VFAULT" 16498196 "DTC_MBB_14_VFAULT" 16498197 "DTC_MBB_15_VFAULT" 16498198 "DTC_MBB_16_VFAULT" 16498199 "DTC_MBB_17_VFAULT" 16498200 "DTC_MBB_18_VFAULT" 16498201 "DTC_MBB_19_VFAULT" 16498208 "DTC_MBB_20_VFAULT" 16498209 "DTC_MBB_21_VFAULT" 16498210 "DTC_MBB_22_VFAULT" 16498211 "DTC_MBB_23_VFAULT" 16498212 "DTC_MBB_24_VFAULT" 16497921 "DTC_MBB_01_TFAULT" 16497922 "DTC_MBB_02_TFAULT" 16497923 "DTC_MBB_03_TFAULT" 16497924 "DTC_MBB_04_TFAULT" 16497925 "DTC_MBB_05_TFAULT" 16497926 "DTC_MBB_06_TFAULT" 16497927 "DTC_MBB_07_TFAULT" 16497928 "DTC_MBB_08_TFAULT" 16497929 "DTC_MBB_09_TFAULT" 16497936 "DTC_MBB_10_TFAULT" 16497937 "DTC_MBB_11_TFAULT" 16497938 "DTC_MBB_12_TFAULT" 16497939 "DTC_MBB_13_TFAULT" 16497940 "DTC_MBB_14_TFAULT" 16497941 "DTC_MBB_15_TFAULT" 16497942 "DTC_MBB_16_TFAULT" 16497943 "DTC_MBB_17_TFAULT" 16497944 "DTC_MBB_18_TFAULT" 16497945 "DTC_MBB_19_TFAULT" 16497952 "DTC_MBB_20_TFAULT" 16497953 "DTC_MBB_21_TFAULT" 16497954 "DTC_MBB_22_TFAULT" 16497955 "DTC_MBB_23_TFAULT" 16497956 "DTC_MBB_24_TFAULT" 15785984 "DTC_PRECHARGE_ENERGY" 15785985 "DTC_PRT_FAILED" 15785986 "DTC_PRT_OVERTEMP" 15785987 "DTC_PRT_PROHIBIT" 16556032 "DTC_COOLANT_TEMP_OOR_HI" 16556033 "DTC_COOLANT_TEMP_OOR_LO" 16252928 "DTC_KEY_OFF_TIME_ERROR" 16506880 "DTC_VBAT_MISMATCH" 16506881 "DTC_VBAT_VMAX" 16506882 "DTC_VBAT_VMIN" 16506883 "DTC_PACK_FUSE" 15798544 "DTC_LLS1_OOR_HI" 15798545 "DTC_LLS1_OOR_LO" 15798546 "DTC_LLS1_FAULT" 15798816 "DTC_LLS2_OOR_HI" 15798817 "DTC_LLS2_OOR_LO" 15798818 "DTC_LLS2_FAULT" 14479360 "DTC_CFL_HEARTBEAT" 14479361 "DTC_CFL_FAULT" 14479362 "DTC_CFL_FAULT_LATCH" 13635584 "DTC_CONT_A_FAILED_HI" 13635585 "DTC_CONT_A_FAILED_LO" 13635586 "DTC_CONT_B_FAILED_HI" 13635587 "DTC_CONT_B_FAILED_LO" 13635588 "DTC_CONT_C_FAILED_HI" 13635589 "DTC_CONT_C_FAILED_LO" 13635590 "DTC_CONT_D_FAILED_HI" 13635591 "DTC_CONT_D_FAILED_LO" 13635592 "DTC_CONT_E_FAILED_HI" 13635593 "DTC_CONT_E_FAILED_LO" 13635594 "DTC_CONT_F_FAILED_HI" 13635595 "DTC_CONT_F_FAILED_LO" 13635596 "DTC_CONT_G_FAILED_HI" 13635597 "DTC_CONT_G_FAILED_LO" 13635598 "DTC_LSD_A_FAILED_HI" 13635599 "DTC_LSD_A_FAILED_LO" 13635600 "DTC_LSD_B_FAILED_HI" 13635601 "DTC_LSD_B_FAILED_LO" 13635602 "DTC_LSD_C_FAILED_HI" 13635603 "DTC_LSD_C_FAILED_LO" 13635606 "DTC_CONT_PWR_FAILED_HI" 13635607 "DTC_CONT_PWR_FAILED_LO" 13635608 "DTC_LSD_PUMP_FAILED_HI" 13635609 "DTC_LSD_PUMP_FAILED_LO" 13635610 "DTC_CHG_A_ENABLE_FAILED_HI" 13635611 "DTC_CHG_A_ENABLE_FAILED_LO" 13635612 "DTC_CHG_B_ENABLE_FAILED_HI" 13635613 "DTC_CHG_B_ENABLE_FAILED_LO" 13635614 "DTC_SW14V_PWR_FAILED_HI" 13635615 "DTC_SW14V_PWR_FAILED_LO" 13635620 "DTC_HSD_A_FAILED_HI" 13635621 "DTC_HSD_A_FAILED_LO" 13635622 "DTC_HSD_B_FAILED_HI" 13635623 "DTC_HSD_B_FAILED_LO" 13692968 "DTC_CONT_HPWR_FAILED_HI" 13692969 "DTC_CONT_HPWR_FAILED_LO" 13692970 "DTC_CONT_HPWR_OOR_HI" 13692971 "DTC_CONT_HPWR_OOR_LO" 13635616 "DTC_5V_PWR_OOR_HI" 13635617 "DTC_5V_PWR_OOR_LO" 14606336 "DTC_NVM_WRITE_TO" 14606337 "DTC_NVM_READ_TO" 14614528 "DTC_SPI_DIG_POT_FAULT" ;
VAL_ 1120 bcm_dtc_004 0 " - " 11276288 "DTC_VEPO" 11276289 "DTC_HSC_MISSING" 11460608 "DTC_NVM_SOC" 11460609 "DTC_NVM_KOT" 11460610 "DTC_NVM_DTC" 11460611 "DTC_NVM_SOC_CORRECTION" 11460612 "DTC_NVM_APP_SCRATCHPAD" 11517962 "DTC_LOOPTIME_TASK_A" 11517963 "DTC_LOOPTIME_TASK_B" 11517964 "DTC_LOOPTIME_TASK_C" 11517965 "DTC_LOOPTIME_TASK_D" 11517966 "DTC_LOOPTIME_TASK_E" 11517967 "DTC_LOOPTIME_TASK_F" 11323904 "DTC_INTERLOCK_A_FAILED_LOW" 11323905 "DTC_INTERLOCK_A_FAILED_HIGH" 11324160 "DTC_INTERLOCK_B_FAILED_LOW" 11324161 "DTC_INTERLOCK_B_FAILED_HIGH" 15728640 "DTC_EPO" 16498688 "DTC_BRUSA_MISSING" 16498689 "DTC_BRUSA_IDC" 16498690 "DTC_BRUSA_REQ_VS_CMD" 16433152 "DTC_AKERWADE_MISSING" 16433153 "DTC_AKERWADE_IDC" 16433154 "DTC_AKERWADE_REQ_VS_CMD" 16564224 "DTC_CHGLEAR_MISSING" 16564225 "DTC_CHGLEAR_IDC" 16564226 "DTC_CHGLEAR_REQ_VS_CMD" 16522240 "DTC_CSM_MISSING" 16522752 "DTC_CSM_VBAT" 16522753 "DTC_CSM_VPOS" 16522754 "DTC_CSM_VNEG" 16522755 "DTC_CSM_CPOS" 16522756 "DTC_CSM_CNEG" 16522757 "DTC_CSM_APOS" 16522758 "DTC_CSM_ANEG" 16522759 "DTC_CSM_FUSE_HI" 16522760 "DTC_CSM_FUSE_LO" 16521728 "DTC_CSM_ASIC" 16521729 "DTC_CSM_AILO" 16521730 "DTC_CSM_AIHI" 16520957 "DTC_LEAKAGE_DETECT_FAULT" 16522444 "DTC_REALTIMECLOCK_FAULT" 16520945 "DTC_CSM_LEAK_FAIL_CALC" 16520946 "DTC_CSM_LEAK_FAIL_HW" 16520947 "DTC_CSM_LEAK_EXT_SHORT" 16520948 "DTC_CSM_LEAK_MID_PACK_SHORT" 16520949 "DTC_CSM_LEAK_ERROR" 16520950 "DTC_CSM_LEAK_UNKNOWN" 16523008 "DTC_CSM_VER_MISMATCH" 16523009 "DTC_CSM_DTC_SET" 16523010 "DTC_CSM_CAL_FAULT" 16560128 "DTC_IBAT_MISMATCH" 16576512 "DTC_DIS_MAX_I2T" 16576513 "DTC_CHG_MAX_I2T" 16576768 "DTC_DIS_WARNING_I2T" 16576769 "DTC_CHG_WARNING_I2T" 11296784 "DTC_SAEJ1772_PROX_DECT_OOR_HI" 11296785 "DTC_SAEJ1772_PROX_DECT_OOR_LO" 11296800 "DTC_SAEJ1772_PILOT_PWM_OOR_HI" 11296801 "DTC_SAEJ1772_PILOT_PWM_OOR_LO" 11296802 "DTC_SAEJ1772_PILOT_PWM_DIG_COMM" 11296803 "DTC_SAEJ1772_PILOT_PWM_IR_ERR" 16175360 "DTC_FGD1_NO_SENSOR" 16175361 "DTC_FGD1_OOR_HI" 16175362 "DTC_FGD1_OOR_LO" 16175363 "DTC_FGD1_FAULT" 16175616 "DTC_FGD2_NO_SENSOR" 16175617 "DTC_FGD2_OOR_HI" 16175618 "DTC_FGD2_OOR_LO" 16175619 "DTC_FGD2_FAULT" 16171008 "DTC_CONT_OPEN" 16171009 "DTC_CONT_CLOSE" 16171010 "DTC_CONT_OPEN_CURRENT" 16171264 "DTC_CONT_CLOSE_ON_RESET" 16171265 "DTC_CONT_CLOSE_SIG_FAILED" 16171520 "DTC_PRECHARGE_TIMEOUT" 16171777 "DTC_CONT_MPOS_WELD_AT_SU" 16171778 "DTC_CONT_MNEG_WELD_AT_SU" 16171780 "DTC_CONT_CPOS_WELD_AT_SU" 16171781 "DTC_CONT_CNEG_WELD_AT_SU" 16171782 "DTC_CONT_ANEG_WELD_AT_SU" 16171783 "DTC_CONT_APOS_WELD_AT_SU" 16172033 "DTC_CONT_MPOS_WELD_AT_SD" 16172034 "DTC_CONT_MNEG_WELD_AT_SD" 16172036 "DTC_CONT_CPOS_WELD_AT_SD" 16172037 "DTC_CONT_CNEG_WELD_AT_SD" 16172038 "DTC_CONT_ANEG_WELD_AT_SD" 16172039 "DTC_CONT_APOS_WELD_AT_SD" 16172289 "DTC_CONT_MPOS_OPEN" 16172290 "DTC_CONT_MNEG_OPEN" 16172291 "DTC_CONT_MPRE_OPEN" 16172292 "DTC_CONT_CPOS_OPEN" 16172293 "DTC_CONT_CNEG_OPEN" 16172294 "DTC_CONT_APOS_OPEN" 16172295 "DTC_CONT_ANEG_OPEN" 16172545 "DTC_CONT_MPOS_VDIF" 16172546 "DTC_CONT_MNEG_VDIF" 16172548 "DTC_CONT_CPOS_VDIF" 16172549 "DTC_CONT_CNEG_VDIF" 16172550 "DTC_CONT_APOS_VDIF" 16172551 "DTC_CONT_ANEG_VDIF" 16174848 "DTC_HVIL" 16174849 "DTC_LVBAT_LO" 16174850 "DTC_LVBAT_HI" 16174851 "DTC_LVBAT_ERR" 16523520 "DTC_LEMLO_OOR_HI" 16523521 "DTC_LEMLO_OOR_LO" 16523522 "DTC_LEMLO_FAULT" 16523776 "DTC_LEMHI_OOR_HI" 16523777 "DTC_LEMHI_OOR_LO" 16523778 "DTC_LEMHI_FAULT" 16496320 "DTC_MBB_TOO_FEW" 16496321 "DTC_MBB_TOO_MANY" 16496352 "DTC_CELL_VMAX_ERR" 16496353 "DTC_CELL_VMIN_ERR" 16496354 "DTC_CELL_VMAX" 16496362 "DTC_CELL_VMAX_SEVERE" 16496355 "DTC_CELL_VMIN" 16496363 "DTC_CELL_VMIN_SEVERE" 16496356 "DTC_MOD_VOLTAGE_COMPARE" 16496336 "DTC_CELL_T_ERR" 16496337 "DTC_CELL_TMAX1" 16496338 "DTC_CELL_TMAX2" 16496339 "DTC_CELL_TMIN" 16497665 "DTC_MBB_01_MISSING" 16497666 "DTC_MBB_02_MISSING" 16497667 "DTC_MBB_03_MISSING" 16497668 "DTC_MBB_04_MISSING" 16497669 "DTC_MBB_05_MISSING" 16497670 "DTC_MBB_06_MISSING" 16497671 "DTC_MBB_07_MISSING" 16497672 "DTC_MBB_08_MISSING" 16497673 "DTC_MBB_09_MISSING" 16497680 "DTC_MBB_10_MISSING" 16497681 "DTC_MBB_11_MISSING" 16497682 "DTC_MBB_12_MISSING" 16497683 "DTC_MBB_13_MISSING" 16497684 "DTC_MBB_14_MISSING" 16497685 "DTC_MBB_15_MISSING" 16497686 "DTC_MBB_16_MISSING" 16497687 "DTC_MBB_17_MISSING" 16497688 "DTC_MBB_18_MISSING" 16497689 "DTC_MBB_19_MISSING" 16497696 "DTC_MBB_20_MISSING" 16497697 "DTC_MBB_21_MISSING" 16497698 "DTC_MBB_22_MISSING" 16497699 "DTC_MBB_23_MISSING" 16497700 "DTC_MBB_24_MISSING" 16498177 "DTC_MBB_01_VFAULT" 16498178 "DTC_MBB_02_VFAULT" 16498179 "DTC_MBB_03_VFAULT" 16498180 "DTC_MBB_04_VFAULT" 16498181 "DTC_MBB_05_VFAULT" 16498182 "DTC_MBB_06_VFAULT" 16498183 "DTC_MBB_07_VFAULT" 16498184 "DTC_MBB_08_VFAULT" 16498185 "DTC_MBB_09_VFAULT" 16498192 "DTC_MBB_10_VFAULT" 16498193 "DTC_MBB_11_VFAULT" 16498194 "DTC_MBB_12_VFAULT" 16498195 "DTC_MBB_13_VFAULT" 16498196 "DTC_MBB_14_VFAULT" 16498197 "DTC_MBB_15_VFAULT" 16498198 "DTC_MBB_16_VFAULT" 16498199 "DTC_MBB_17_VFAULT" 16498200 "DTC_MBB_18_VFAULT" 16498201 "DTC_MBB_19_VFAULT" 16498208 "DTC_MBB_20_VFAULT" 16498209 "DTC_MBB_21_VFAULT" 16498210 "DTC_MBB_22_VFAULT" 16498211 "DTC_MBB_23_VFAULT" 16498212 "DTC_MBB_24_VFAULT" 16497921 "DTC_MBB_01_TFAULT" 16497922 "DTC_MBB_02_TFAULT" 16497923 "DTC_MBB_03_TFAULT" 16497924 "DTC_MBB_04_TFAULT" 16497925 "DTC_MBB_05_TFAULT" 16497926 "DTC_MBB_06_TFAULT" 16497927 "DTC_MBB_07_TFAULT" 16497928 "DTC_MBB_08_TFAULT" 16497929 "DTC_MBB_09_TFAULT" 16497936 "DTC_MBB_10_TFAULT" 16497937 "DTC_MBB_11_TFAULT" 16497938 "DTC_MBB_12_TFAULT" 16497939 "DTC_MBB_13_TFAULT" 16497940 "DTC_MBB_14_TFAULT" 16497941 "DTC_MBB_15_TFAULT" 16497942 "DTC_MBB_16_TFAULT" 16497943 "DTC_MBB_17_TFAULT" 16497944 "DTC_MBB_18_TFAULT" 16497945 "DTC_MBB_19_TFAULT" 16497952 "DTC_MBB_20_TFAULT" 16497953 "DTC_MBB_21_TFAULT" 16497954 "DTC_MBB_22_TFAULT" 16497955 "DTC_MBB_23_TFAULT" 16497956 "DTC_MBB_24_TFAULT" 15785984 "DTC_PRECHARGE_ENERGY" 15785985 "DTC_PRT_FAILED" 15785986 "DTC_PRT_OVERTEMP" 15785987 "DTC_PRT_PROHIBIT" 16556032 "DTC_COOLANT_TEMP_OOR_HI" 16556033 "DTC_COOLANT_TEMP_OOR_LO" 16252928 "DTC_KEY_OFF_TIME_ERROR" 16506880 "DTC_VBAT_MISMATCH" 16506881 "DTC_VBAT_VMAX" 16506882 "DTC_VBAT_VMIN" 16506883 "DTC_PACK_FUSE" 15798544 "DTC_LLS1_OOR_HI" 15798545 "DTC_LLS1_OOR_LO" 15798546 "DTC_LLS1_FAULT" 15798816 "DTC_LLS2_OOR_HI" 15798817 "DTC_LLS2_OOR_LO" 15798818 "DTC_LLS2_FAULT" 14479360 "DTC_CFL_HEARTBEAT" 14479361 "DTC_CFL_FAULT" 14479362 "DTC_CFL_FAULT_LATCH" 13635584 "DTC_CONT_A_FAILED_HI" 13635585 "DTC_CONT_A_FAILED_LO" 13635586 "DTC_CONT_B_FAILED_HI" 13635587 "DTC_CONT_B_FAILED_LO" 13635588 "DTC_CONT_C_FAILED_HI" 13635589 "DTC_CONT_C_FAILED_LO" 13635590 "DTC_CONT_D_FAILED_HI" 13635591 "DTC_CONT_D_FAILED_LO" 13635592 "DTC_CONT_E_FAILED_HI" 13635593 "DTC_CONT_E_FAILED_LO" 13635594 "DTC_CONT_F_FAILED_HI" 13635595 "DTC_CONT_F_FAILED_LO" 13635596 "DTC_CONT_G_FAILED_HI" 13635597 "DTC_CONT_G_FAILED_LO" 13635598 "DTC_LSD_A_FAILED_HI" 13635599 "DTC_LSD_A_FAILED_LO" 13635600 "DTC_LSD_B_FAILED_HI" 13635601 "DTC_LSD_B_FAILED_LO" 13635602 "DTC_LSD_C_FAILED_HI" 13635603 "DTC_LSD_C_FAILED_LO" 13635606 "DTC_CONT_PWR_FAILED_HI" 13635607 "DTC_CONT_PWR_FAILED_LO" 13635608 "DTC_LSD_PUMP_FAILED_HI" 13635609 "DTC_LSD_PUMP_FAILED_LO" 13635610 "DTC_CHG_A_ENABLE_FAILED_HI" 13635611 "DTC_CHG_A_ENABLE_FAILED_LO" 13635612 "DTC_CHG_B_ENABLE_FAILED_HI" 13635613 "DTC_CHG_B_ENABLE_FAILED_LO" 13635614 "DTC_SW14V_PWR_FAILED_HI" 13635615 "DTC_SW14V_PWR_FAILED_LO" 13635620 "DTC_HSD_A_FAILED_HI" 13635621 "DTC_HSD_A_FAILED_LO" 13635622 "DTC_HSD_B_FAILED_HI" 13635623 "DTC_HSD_B_FAILED_LO" 13692968 "DTC_CONT_HPWR_FAILED_HI" 13692969 "DTC_CONT_HPWR_FAILED_LO" 13692970 "DTC_CONT_HPWR_OOR_HI" 13692971 "DTC_CONT_HPWR_OOR_LO" 13635616 "DTC_5V_PWR_OOR_HI" 13635617 "DTC_5V_PWR_OOR_LO" 14606336 "DTC_NVM_WRITE_TO" 14606337 "DTC_NVM_READ_TO" 14614528 "DTC_SPI_DIG_POT_FAULT" ;
VAL_ 1120 bcm_dtc_005 0 " - " 11276288 "DTC_VEPO" 11276289 "DTC_HSC_MISSING" 11460608 "DTC_NVM_SOC" 11460609 "DTC_NVM_KOT" 11460610 "DTC_NVM_DTC" 11460611 "DTC_NVM_SOC_CORRECTION" 11460612 "DTC_NVM_APP_SCRATCHPAD" 11517962 "DTC_LOOPTIME_TASK_A" 11517963 "DTC_LOOPTIME_TASK_B" 11517964 "DTC_LOOPTIME_TASK_C" 11517965 "DTC_LOOPTIME_TASK_D" 11517966 "DTC_LOOPTIME_TASK_E" 11517967 "DTC_LOOPTIME_TASK_F" 11323904 "DTC_INTERLOCK_A_FAILED_LOW" 11323905 "DTC_INTERLOCK_A_FAILED_HIGH" 11324160 "DTC_INTERLOCK_B_FAILED_LOW" 11324161 "DTC_INTERLOCK_B_FAILED_HIGH" 15728640 "DTC_EPO" 16498688 "DTC_BRUSA_MISSING" 16498689 "DTC_BRUSA_IDC" 16498690 "DTC_BRUSA_REQ_VS_CMD" 16433152 "DTC_AKERWADE_MISSING" 16433153 "DTC_AKERWADE_IDC" 16433154 "DTC_AKERWADE_REQ_VS_CMD" 16564224 "DTC_CHGLEAR_MISSING" 16564225 "DTC_CHGLEAR_IDC" 16564226 "DTC_CHGLEAR_REQ_VS_CMD" 16522240 "DTC_CSM_MISSING" 16522752 "DTC_CSM_VBAT" 16522753 "DTC_CSM_VPOS" 16522754 "DTC_CSM_VNEG" 16522755 "DTC_CSM_CPOS" 16522756 "DTC_CSM_CNEG" 16522757 "DTC_CSM_APOS" 16522758 "DTC_CSM_ANEG" 16522759 "DTC_CSM_FUSE_HI" 16522760 "DTC_CSM_FUSE_LO" 16521728 "DTC_CSM_ASIC" 16521729 "DTC_CSM_AILO" 16521730 "DTC_CSM_AIHI" 16520957 "DTC_LEAKAGE_DETECT_FAULT" 16522444 "DTC_REALTIMECLOCK_FAULT" 16520945 "DTC_CSM_LEAK_FAIL_CALC" 16520946 "DTC_CSM_LEAK_FAIL_HW" 16520947 "DTC_CSM_LEAK_EXT_SHORT" 16520948 "DTC_CSM_LEAK_MID_PACK_SHORT" 16520949 "DTC_CSM_LEAK_ERROR" 16520950 "DTC_CSM_LEAK_UNKNOWN" 16523008 "DTC_CSM_VER_MISMATCH" 16523009 "DTC_CSM_DTC_SET" 16523010 "DTC_CSM_CAL_FAULT" 16560128 "DTC_IBAT_MISMATCH" 16576512 "DTC_DIS_MAX_I2T" 16576513 "DTC_CHG_MAX_I2T" 16576768 "DTC_DIS_WARNING_I2T" 16576769 "DTC_CHG_WARNING_I2T" 11296784 "DTC_SAEJ1772_PROX_DECT_OOR_HI" 11296785 "DTC_SAEJ1772_PROX_DECT_OOR_LO" 11296800 "DTC_SAEJ1772_PILOT_PWM_OOR_HI" 11296801 "DTC_SAEJ1772_PILOT_PWM_OOR_LO" 11296802 "DTC_SAEJ1772_PILOT_PWM_DIG_COMM" 11296803 "DTC_SAEJ1772_PILOT_PWM_IR_ERR" 16175360 "DTC_FGD1_NO_SENSOR" 16175361 "DTC_FGD1_OOR_HI" 16175362 "DTC_FGD1_OOR_LO" 16175363 "DTC_FGD1_FAULT" 16175616 "DTC_FGD2_NO_SENSOR" 16175617 "DTC_FGD2_OOR_HI" 16175618 "DTC_FGD2_OOR_LO" 16175619 "DTC_FGD2_FAULT" 16171008 "DTC_CONT_OPEN" 16171009 "DTC_CONT_CLOSE" 16171010 "DTC_CONT_OPEN_CURRENT" 16171264 "DTC_CONT_CLOSE_ON_RESET" 16171265 "DTC_CONT_CLOSE_SIG_FAILED" 16171520 "DTC_PRECHARGE_TIMEOUT" 16171777 "DTC_CONT_MPOS_WELD_AT_SU" 16171778 "DTC_CONT_MNEG_WELD_AT_SU" 16171780 "DTC_CONT_CPOS_WELD_AT_SU" 16171781 "DTC_CONT_CNEG_WELD_AT_SU" 16171782 "DTC_CONT_ANEG_WELD_AT_SU" 16171783 "DTC_CONT_APOS_WELD_AT_SU" 16172033 "DTC_CONT_MPOS_WELD_AT_SD" 16172034 "DTC_CONT_MNEG_WELD_AT_SD" 16172036 "DTC_CONT_CPOS_WELD_AT_SD" 16172037 "DTC_CONT_CNEG_WELD_AT_SD" 16172038 "DTC_CONT_ANEG_WELD_AT_SD" 16172039 "DTC_CONT_APOS_WELD_AT_SD" 16172289 "DTC_CONT_MPOS_OPEN" 16172290 "DTC_CONT_MNEG_OPEN" 16172291 "DTC_CONT_MPRE_OPEN" 16172292 "DTC_CONT_CPOS_OPEN" 16172293 "DTC_CONT_CNEG_OPEN" 16172294 "DTC_CONT_APOS_OPEN" 16172295 "DTC_CONT_ANEG_OPEN" 16172545 "DTC_CONT_MPOS_VDIF" 16172546 "DTC_CONT_MNEG_VDIF" 16172548 "DTC_CONT_CPOS_VDIF" 16172549 "DTC_CONT_CNEG_VDIF" 16172550 "DTC_CONT_APOS_VDIF" 16172551 "DTC_CONT_ANEG_VDIF" 16174848 "DTC_HVIL" 16174849 "DTC_LVBAT_LO" 16174850 "DTC_LVBAT_HI" 16174851 "DTC_LVBAT_ERR" 16523520 "DTC_LEMLO_OOR_HI" 16523521 "DTC_LEMLO_OOR_LO" 16523522 "DTC_LEMLO_FAULT" 16523776 "DTC_LEMHI_OOR_HI" 16523777 "DTC_LEMHI_OOR_LO" 16523778 "DTC_LEMHI_FAULT" 16496320 "DTC_MBB_TOO_FEW" 16496321 "DTC_MBB_TOO_MANY" 16496352 "DTC_CELL_VMAX_ERR" 16496353 "DTC_CELL_VMIN_ERR" 16496354 "DTC_CELL_VMAX" 16496362 "DTC_CELL_VMAX_SEVERE" 16496355 "DTC_CELL_VMIN" 16496363 "DTC_CELL_VMIN_SEVERE" 16496356 "DTC_MOD_VOLTAGE_COMPARE" 16496336 "DTC_CELL_T_ERR" 16496337 "DTC_CELL_TMAX1" 16496338 "DTC_CELL_TMAX2" 16496339 "DTC_CELL_TMIN" 16497665 "DTC_MBB_01_MISSING" 16497666 "DTC_MBB_02_MISSING" 16497667 "DTC_MBB_03_MISSING" 16497668 "DTC_MBB_04_MISSING" 16497669 "DTC_MBB_05_MISSING" 16497670 "DTC_MBB_06_MISSING" 16497671 "DTC_MBB_07_MISSING" 16497672 "DTC_MBB_08_MISSING" 16497673 "DTC_MBB_09_MISSING" 16497680 "DTC_MBB_10_MISSING" 16497681 "DTC_MBB_11_MISSING" 16497682 "DTC_MBB_12_MISSING" 16497683 "DTC_MBB_13_MISSING" 16497684 "DTC_MBB_14_MISSING" 16497685 "DTC_MBB_15_MISSING" 16497686 "DTC_MBB_16_MISSING" 16497687 "DTC_MBB_17_MISSING" 16497688 "DTC_MBB_18_MISSING" 16497689 "DTC_MBB_19_MISSING" 16497696 "DTC_MBB_20_MISSING" 16497697 "DTC_MBB_21_MISSING" 16497698 "DTC_MBB_22_MISSING" 16497699 "DTC_MBB_23_MISSING" 16497700 "DTC_MBB_24_MISSING" 16498177 "DTC_MBB_01_VFAULT" 16498178 "DTC_MBB_02_VFAULT" 16498179 "DTC_MBB_03_VFAULT" 16498180 "DTC_MBB_04_VFAULT" 16498181 "DTC_MBB_05_VFAULT" 16498182 "DTC_MBB_06_VFAULT" 16498183 "DTC_MBB_07_VFAULT" 16498184 "DTC_MBB_08_VFAULT" 16498185 "DTC_MBB_09_VFAULT" 16498192 "DTC_MBB_10_VFAULT" 16498193 "DTC_MBB_11_VFAULT" 16498194 "DTC_MBB_12_VFAULT" 16498195 "DTC_MBB_13_VFAULT" 16498196 "DTC_MBB_14_VFAULT" 16498197 "DTC_MBB_15_VFAULT" 16498198 "DTC_MBB_16_VFAULT" 16498199 "DTC_MBB_17_VFAULT" 16498200 "DTC_MBB_18_VFAULT" 16498201 "DTC_MBB_19_VFAULT" 16498208 "DTC_MBB_20_VFAULT" 16498209 "DTC_MBB_21_VFAULT" 16498210 "DTC_MBB_22_VFAULT" 16498211 "DTC_MBB_23_VFAULT" 16498212 "DTC_MBB_24_VFAULT" 16497921 "DTC_MBB_01_TFAULT" 16497922 "DTC_MBB_02_TFAULT" 16497923 "DTC_MBB_03_TFAULT" 16497924 "DTC_MBB_04_TFAULT" 16497925 "DTC_MBB_05_TFAULT" 16497926 "DTC_MBB_06_TFAULT" 16497927 "DTC_MBB_07_TFAULT" 16497928 "DTC_MBB_08_TFAULT" 16497929 "DTC_MBB_09_TFAULT" 16497936 "DTC_MBB_10_TFAULT" 16497937 "DTC_MBB_11_TFAULT" 16497938 "DTC_MBB_12_TFAULT" 16497939 "DTC_MBB_13_TFAULT" 16497940 "DTC_MBB_14_TFAULT" 16497941 "DTC_MBB_15_TFAULT" 16497942 "DTC_MBB_16_TFAULT" 16497943 "DTC_MBB_17_TFAULT" 16497944 "DTC_MBB_18_TFAULT" 16497945 "DTC_MBB_19_TFAULT" 16497952 "DTC_MBB_20_TFAULT" 16497953 "DTC_MBB_21_TFAULT" 16497954 "DTC_MBB_22_TFAULT" 16497955 "DTC_MBB_23_TFAULT" 16497956 "DTC_MBB_24_TFAULT" 15785984 "DTC_PRECHARGE_ENERGY" 15785985 "DTC_PRT_FAILED" 15785986 "DTC_PRT_OVERTEMP" 15785987 "DTC_PRT_PROHIBIT" 16556032 "DTC_COOLANT_TEMP_OOR_HI" 16556033 "DTC_COOLANT_TEMP_OOR_LO" 16252928 "DTC_KEY_OFF_TIME_ERROR" 16506880 "DTC_VBAT_MISMATCH" 16506881 "DTC_VBAT_VMAX" 16506882 "DTC_VBAT_VMIN" 16506883 "DTC_PACK_FUSE" 15798544 "DTC_LLS1_OOR_HI" 15798545 "DTC_LLS1_OOR_LO" 15798546 "DTC_LLS1_FAULT" 15798816 "DTC_LLS2_OOR_HI" 15798817 "DTC_LLS2_OOR_LO" 15798818 "DTC_LLS2_FAULT" 14479360 "DTC_CFL_HEARTBEAT" 14479361 "DTC_CFL_FAULT" 14479362 "DTC_CFL_FAULT_LATCH" 13635584 "DTC_CONT_A_FAILED_HI" 13635585 "DTC_CONT_A_FAILED_LO" 13635586 "DTC_CONT_B_FAILED_HI" 13635587 "DTC_CONT_B_FAILED_LO" 13635588 "DTC_CONT_C_FAILED_HI" 13635589 "DTC_CONT_C_FAILED_LO" 13635590 "DTC_CONT_D_FAILED_HI" 13635591 "DTC_CONT_D_FAILED_LO" 13635592 "DTC_CONT_E_FAILED_HI" 13635593 "DTC_CONT_E_FAILED_LO" 13635594 "DTC_CONT_F_FAILED_HI" 13635595 "DTC_CONT_F_FAILED_LO" 13635596 "DTC_CONT_G_FAILED_HI" 13635597 "DTC_CONT_G_FAILED_LO" 13635598 "DTC_LSD_A_FAILED_HI" 13635599 "DTC_LSD_A_FAILED_LO" 13635600 "DTC_LSD_B_FAILED_HI" 13635601 "DTC_LSD_B_FAILED_LO" 13635602 "DTC_LSD_C_FAILED_HI" 13635603 "DTC_LSD_C_FAILED_LO" 13635606 "DTC_CONT_PWR_FAILED_HI" 13635607 "DTC_CONT_PWR_FAILED_LO" 13635608 "DTC_LSD_PUMP_FAILED_HI" 13635609 "DTC_LSD_PUMP_FAILED_LO" 13635610 "DTC_CHG_A_ENABLE_FAILED_HI" 13635611 "DTC_CHG_A_ENABLE_FAILED_LO" 13635612 "DTC_CHG_B_ENABLE_FAILED_HI" 13635613 "DTC_CHG_B_ENABLE_FAILED_LO" 13635614 "DTC_SW14V_PWR_FAILED_HI" 13635615 "DTC_SW14V_PWR_FAILED_LO" 13635620 "DTC_HSD_A_FAILED_HI" 13635621 "DTC_HSD_A_FAILED_LO" 13635622 "DTC_HSD_B_FAILED_HI" 13635623 "DTC_HSD_B_FAILED_LO" 13692968 "DTC_CONT_HPWR_FAILED_HI" 13692969 "DTC_CONT_HPWR_FAILED_LO" 13692970 "DTC_CONT_HPWR_OOR_HI" 13692971 "DTC_CONT_HPWR_OOR_LO" 13635616 "DTC_5V_PWR_OOR_HI" 13635617 "DTC_5V_PWR_OOR_LO" 14606336 "DTC_NVM_WRITE_TO" 14606337 "DTC_NVM_READ_TO" 14614528 "DTC_SPI_DIG_POT_FAULT" ;
VAL_ 1120 bcm_dtc_006 0 " - " 11276288 "DTC_VEPO" 11276289 "DTC_HSC_MISSING" 11460608 "DTC_NVM_SOC" 11460609 "DTC_NVM_KOT" 11460610 "DTC_NVM_DTC" 11460611 "DTC_NVM_SOC_CORRECTION" 11460612 "DTC_NVM_APP_SCRATCHPAD" 11517962 "DTC_LOOPTIME_TASK_A" 11517963 "DTC_LOOPTIME_TASK_B" 11517964 "DTC_LOOPTIME_TASK_C" 11517965 "DTC_LOOPTIME_TASK_D" 11517966 "DTC_LOOPTIME_TASK_E" 11517967 "DTC_LOOPTIME_TASK_F" 11323904 "DTC_INTERLOCK_A_FAILED_LOW" 11323905 "DTC_INTERLOCK_A_FAILED_HIGH" 11324160 "DTC_INTERLOCK_B_FAILED_LOW" 11324161 "DTC_INTERLOCK_B_FAILED_HIGH" 15728640 "DTC_EPO" 16498688 "DTC_BRUSA_MISSING" 16498689 "DTC_BRUSA_IDC" 16498690 "DTC_BRUSA_REQ_VS_CMD" 16433152 "DTC_AKERWADE_MISSING" 16433153 "DTC_AKERWADE_IDC" 16433154 "DTC_AKERWADE_REQ_VS_CMD" 16564224 "DTC_CHGLEAR_MISSING" 16564225 "DTC_CHGLEAR_IDC" 16564226 "DTC_CHGLEAR_REQ_VS_CMD" 16522240 "DTC_CSM_MISSING" 16522752 "DTC_CSM_VBAT" 16522753 "DTC_CSM_VPOS" 16522754 "DTC_CSM_VNEG" 16522755 "DTC_CSM_CPOS" 16522756 "DTC_CSM_CNEG" 16522757 "DTC_CSM_APOS" 16522758 "DTC_CSM_ANEG" 16522759 "DTC_CSM_FUSE_HI" 16522760 "DTC_CSM_FUSE_LO" 16521728 "DTC_CSM_ASIC" 16521729 "DTC_CSM_AILO" 16521730 "DTC_CSM_AIHI" 16520957 "DTC_LEAKAGE_DETECT_FAULT" 16522444 "DTC_REALTIMECLOCK_FAULT" 16520945 "DTC_CSM_LEAK_FAIL_CALC" 16520946 "DTC_CSM_LEAK_FAIL_HW" 16520947 "DTC_CSM_LEAK_EXT_SHORT" 16520948 "DTC_CSM_LEAK_MID_PACK_SHORT" 16520949 "DTC_CSM_LEAK_ERROR" 16520950 "DTC_CSM_LEAK_UNKNOWN" 16523008 "DTC_CSM_VER_MISMATCH" 16523009 "DTC_CSM_DTC_SET" 16523010 "DTC_CSM_CAL_FAULT" 16560128 "DTC_IBAT_MISMATCH" 16576512 "DTC_DIS_MAX_I2T" 16576513 "DTC_CHG_MAX_I2T" 16576768 "DTC_DIS_WARNING_I2T" 16576769 "DTC_CHG_WARNING_I2T" 11296784 "DTC_SAEJ1772_PROX_DECT_OOR_HI" 11296785 "DTC_SAEJ1772_PROX_DECT_OOR_LO" 11296800 "DTC_SAEJ1772_PILOT_PWM_OOR_HI" 11296801 "DTC_SAEJ1772_PILOT_PWM_OOR_LO" 11296802 "DTC_SAEJ1772_PILOT_PWM_DIG_COMM" 11296803 "DTC_SAEJ1772_PILOT_PWM_IR_ERR" 16175360 "DTC_FGD1_NO_SENSOR" 16175361 "DTC_FGD1_OOR_HI" 16175362 "DTC_FGD1_OOR_LO" 16175363 "DTC_FGD1_FAULT" 16175616 "DTC_FGD2_NO_SENSOR" 16175617 "DTC_FGD2_OOR_HI" 16175618 "DTC_FGD2_OOR_LO" 16175619 "DTC_FGD2_FAULT" 16171008 "DTC_CONT_OPEN" 16171009 "DTC_CONT_CLOSE" 16171010 "DTC_CONT_OPEN_CURRENT" 16171264 "DTC_CONT_CLOSE_ON_RESET" 16171265 "DTC_CONT_CLOSE_SIG_FAILED" 16171520 "DTC_PRECHARGE_TIMEOUT" 16171777 "DTC_CONT_MPOS_WELD_AT_SU" 16171778 "DTC_CONT_MNEG_WELD_AT_SU" 16171780 "DTC_CONT_CPOS_WELD_AT_SU" 16171781 "DTC_CONT_CNEG_WELD_AT_SU" 16171782 "DTC_CONT_ANEG_WELD_AT_SU" 16171783 "DTC_CONT_APOS_WELD_AT_SU" 16172033 "DTC_CONT_MPOS_WELD_AT_SD" 16172034 "DTC_CONT_MNEG_WELD_AT_SD" 16172036 "DTC_CONT_CPOS_WELD_AT_SD" 16172037 "DTC_CONT_CNEG_WELD_AT_SD" 16172038 "DTC_CONT_ANEG_WELD_AT_SD" 16172039 "DTC_CONT_APOS_WELD_AT_SD" 16172289 "DTC_CONT_MPOS_OPEN" 16172290 "DTC_CONT_MNEG_OPEN" 16172291 "DTC_CONT_MPRE_OPEN" 16172292 "DTC_CONT_CPOS_OPEN" 16172293 "DTC_CONT_CNEG_OPEN" 16172294 "DTC_CONT_APOS_OPEN" 16172295 "DTC_CONT_ANEG_OPEN" 16172545 "DTC_CONT_MPOS_VDIF" 16172546 "DTC_CONT_MNEG_VDIF" 16172548 "DTC_CONT_CPOS_VDIF" 16172549 "DTC_CONT_CNEG_VDIF" 16172550 "DTC_CONT_APOS_VDIF" 16172551 "DTC_CONT_ANEG_VDIF" 16174848 "DTC_HVIL" 16174849 "DTC_LVBAT_LO" 16174850 "DTC_LVBAT_HI" 16174851 "DTC_LVBAT_ERR" 16523520 "DTC_LEMLO_OOR_HI" 16523521 "DTC_LEMLO_OOR_LO" 16523522 "DTC_LEMLO_FAULT" 16523776 "DTC_LEMHI_OOR_HI" 16523777 "DTC_LEMHI_OOR_LO" 16523778 "DTC_LEMHI_FAULT" 16496320 "DTC_MBB_TOO_FEW" 16496321 "DTC_MBB_TOO_MANY" 16496352 "DTC_CELL_VMAX_ERR" 16496353 "DTC_CELL_VMIN_ERR" 16496354 "DTC_CELL_VMAX" 16496362 "DTC_CELL_VMAX_SEVERE" 16496355 "DTC_CELL_VMIN" 16496363 "DTC_CELL_VMIN_SEVERE" 16496356 "DTC_MOD_VOLTAGE_COMPARE" 16496336 "DTC_CELL_T_ERR" 16496337 "DTC_CELL_TMAX1" 16496338 "DTC_CELL_TMAX2" 16496339 "DTC_CELL_TMIN" 16497665 "DTC_MBB_01_MISSING" 16497666 "DTC_MBB_02_MISSING" 16497667 "DTC_MBB_03_MISSING" 16497668 "DTC_MBB_04_MISSING" 16497669 "DTC_MBB_05_MISSING" 16497670 "DTC_MBB_06_MISSING" 16497671 "DTC_MBB_07_MISSING" 16497672 "DTC_MBB_08_MISSING" 16497673 "DTC_MBB_09_MISSING" 16497680 "DTC_MBB_10_MISSING" 16497681 "DTC_MBB_11_MISSING" 16497682 "DTC_MBB_12_MISSING" 16497683 "DTC_MBB_13_MISSING" 16497684 "DTC_MBB_14_MISSING" 16497685 "DTC_MBB_15_MISSING" 16497686 "DTC_MBB_16_MISSING" 16497687 "DTC_MBB_17_MISSING" 16497688 "DTC_MBB_18_MISSING" 16497689 "DTC_MBB_19_MISSING" 16497696 "DTC_MBB_20_MISSING" 16497697 "DTC_MBB_21_MISSING" 16497698 "DTC_MBB_22_MISSING" 16497699 "DTC_MBB_23_MISSING" 16497700 "DTC_MBB_24_MISSING" 16498177 "DTC_MBB_01_VFAULT" 16498178 "DTC_MBB_02_VFAULT" 16498179 "DTC_MBB_03_VFAULT" 16498180 "DTC_MBB_04_VFAULT" 16498181 "DTC_MBB_05_VFAULT" 16498182 "DTC_MBB_06_VFAULT" 16498183 "DTC_MBB_07_VFAULT" 16498184 "DTC_MBB_08_VFAULT" 16498185 "DTC_MBB_09_VFAULT" 16498192 "DTC_MBB_10_VFAULT" 16498193 "DTC_MBB_11_VFAULT" 16498194 "DTC_MBB_12_VFAULT" 16498195 "DTC_MBB_13_VFAULT" 16498196 "DTC_MBB_14_VFAULT" 16498197 "DTC_MBB_15_VFAULT" 16498198 "DTC_MBB_16_VFAULT" 16498199 "DTC_MBB_17_VFAULT" 16498200 "DTC_MBB_18_VFAULT" 16498201 "DTC_MBB_19_VFAULT" 16498208 "DTC_MBB_20_VFAULT" 16498209 "DTC_MBB_21_VFAULT" 16498210 "DTC_MBB_22_VFAULT" 16498211 "DTC_MBB_23_VFAULT" 16498212 "DTC_MBB_24_VFAULT" 16497921 "DTC_MBB_01_TFAULT" 16497922 "DTC_MBB_02_TFAULT" 16497923 "DTC_MBB_03_TFAULT" 16497924 "DTC_MBB_04_TFAULT" 16497925 "DTC_MBB_05_TFAULT" 16497926 "DTC_MBB_06_TFAULT" 16497927 "DTC_MBB_07_TFAULT" 16497928 "DTC_MBB_08_TFAULT" 16497929 "DTC_MBB_09_TFAULT" 16497936 "DTC_MBB_10_TFAULT" 16497937 "DTC_MBB_11_TFAULT" 16497938 "DTC_MBB_12_TFAULT" 16497939 "DTC_MBB_13_TFAULT" 16497940 "DTC_MBB_14_TFAULT" 16497941 "DTC_MBB_15_TFAULT" 16497942 "DTC_MBB_16_TFAULT" 16497943 "DTC_MBB_17_TFAULT" 16497944 "DTC_MBB_18_TFAULT" 16497945 "DTC_MBB_19_TFAULT" 16497952 "DTC_MBB_20_TFAULT" 16497953 "DTC_MBB_21_TFAULT" 16497954 "DTC_MBB_22_TFAULT" 16497955 "DTC_MBB_23_TFAULT" 16497956 "DTC_MBB_24_TFAULT" 15785984 "DTC_PRECHARGE_ENERGY" 15785985 "DTC_PRT_FAILED" 15785986 "DTC_PRT_OVERTEMP" 15785987 "DTC_PRT_PROHIBIT" 16556032 "DTC_COOLANT_TEMP_OOR_HI" 16556033 "DTC_COOLANT_TEMP_OOR_LO" 16252928 "DTC_KEY_OFF_TIME_ERROR" 16506880 "DTC_VBAT_MISMATCH" 16506881 "DTC_VBAT_VMAX" 16506882 "DTC_VBAT_VMIN" 16506883 "DTC_PACK_FUSE" 15798544 "DTC_LLS1_OOR_HI" 15798545 "DTC_LLS1_OOR_LO" 15798546 "DTC_LLS1_FAULT" 15798816 "DTC_LLS2_OOR_HI" 15798817 "DTC_LLS2_OOR_LO" 15798818 "DTC_LLS2_FAULT" 14479360 "DTC_CFL_HEARTBEAT" 14479361 "DTC_CFL_FAULT" 14479362 "DTC_CFL_FAULT_LATCH" 13635584 "DTC_CONT_A_FAILED_HI" 13635585 "DTC_CONT_A_FAILED_LO" 13635586 "DTC_CONT_B_FAILED_HI" 13635587 "DTC_CONT_B_FAILED_LO" 13635588 "DTC_CONT_C_FAILED_HI" 13635589 "DTC_CONT_C_FAILED_LO" 13635590 "DTC_CONT_D_FAILED_HI" 13635591 "DTC_CONT_D_FAILED_LO" 13635592 "DTC_CONT_E_FAILED_HI" 13635593 "DTC_CONT_E_FAILED_LO" 13635594 "DTC_CONT_F_FAILED_HI" 13635595 "DTC_CONT_F_FAILED_LO" 13635596 "DTC_CONT_G_FAILED_HI" 13635597 "DTC_CONT_G_FAILED_LO" 13635598 "DTC_LSD_A_FAILED_HI" 13635599 "DTC_LSD_A_FAILED_LO" 13635600 "DTC_LSD_B_FAILED_HI" 13635601 "DTC_LSD_B_FAILED_LO" 13635602 "DTC_LSD_C_FAILED_HI" 13635603 "DTC_LSD_C_FAILED_LO" 13635606 "DTC_CONT_PWR_FAILED_HI" 13635607 "DTC_CONT_PWR_FAILED_LO" 13635608 "DTC_LSD_PUMP_FAILED_HI" 13635609 "DTC_LSD_PUMP_FAILED_LO" 13635610 "DTC_CHG_A_ENABLE_FAILED_HI" 13635611 "DTC_CHG_A_ENABLE_FAILED_LO" 13635612 "DTC_CHG_B_ENABLE_FAILED_HI" 13635613 "DTC_CHG_B_ENABLE_FAILED_LO" 13635614 "DTC_SW14V_PWR_FAILED_HI" 13635615 "DTC_SW14V_PWR_FAILED_LO" 13635620 "DTC_HSD_A_FAILED_HI" 13635621 "DTC_HSD_A_FAILED_LO" 13635622 "DTC_HSD_B_FAILED_HI" 13635623 "DTC_HSD_B_FAILED_LO" 13692968 "DTC_CONT_HPWR_FAILED_HI" 13692969 "DTC_CONT_HPWR_FAILED_LO" 13692970 "DTC_CONT_HPWR_OOR_HI" 13692971 "DTC_CONT_HPWR_OOR_LO" 13635616 "DTC_5V_PWR_OOR_HI" 13635617 "DTC_5V_PWR_OOR_LO" 14606336 "DTC_NVM_WRITE_TO" 14606337 "DTC_NVM_READ_TO" 14614528 "DTC_SPI_DIG_POT_FAULT" ;
VAL_ 1120 bcm_dtc_007 0 " - " 11276288 "DTC_VEPO" 11276289 "DTC_HSC_MISSING" 11460608 "DTC_NVM_SOC" 11460609 "DTC_NVM_KOT" 11460610 "DTC_NVM_DTC" 11460611 "DTC_NVM_SOC_CORRECTION" 11460612 "DTC_NVM_APP_SCRATCHPAD" 11517962 "DTC_LOOPTIME_TASK_A" 11517963 "DTC_LOOPTIME_TASK_B" 11517964 "DTC_LOOPTIME_TASK_C" 11517965 "DTC_LOOPTIME_TASK_D" 11517966 "DTC_LOOPTIME_TASK_E" 11517967 "DTC_LOOPTIME_TASK_F" 11323904 "DTC_INTERLOCK_A_FAILED_LOW" 11323905 "DTC_INTERLOCK_A_FAILED_HIGH" 11324160 "DTC_INTERLOCK_B_FAILED_LOW" 11324161 "DTC_INTERLOCK_B_FAILED_HIGH" 15728640 "DTC_EPO" 16498688 "DTC_BRUSA_MISSING" 16498689 "DTC_BRUSA_IDC" 16498690 "DTC_BRUSA_REQ_VS_CMD" 16433152 "DTC_AKERWADE_MISSING" 16433153 "DTC_AKERWADE_IDC" 16433154 "DTC_AKERWADE_REQ_VS_CMD" 16564224 "DTC_CHGLEAR_MISSING" 16564225 "DTC_CHGLEAR_IDC" 16564226 "DTC_CHGLEAR_REQ_VS_CMD" 16522240 "DTC_CSM_MISSING" 16522752 "DTC_CSM_VBAT" 16522753 "DTC_CSM_VPOS" 16522754 "DTC_CSM_VNEG" 16522755 "DTC_CSM_CPOS" 16522756 "DTC_CSM_CNEG" 16522757 "DTC_CSM_APOS" 16522758 "DTC_CSM_ANEG" 16522759 "DTC_CSM_FUSE_HI" 16522760 "DTC_CSM_FUSE_LO" 16521728 "DTC_CSM_ASIC" 16521729 "DTC_CSM_AILO" 16521730 "DTC_CSM_AIHI" 16520957 "DTC_LEAKAGE_DETECT_FAULT" 16522444 "DTC_REALTIMECLOCK_FAULT" 16520945 "DTC_CSM_LEAK_FAIL_CALC" 16520946 "DTC_CSM_LEAK_FAIL_HW" 16520947 "DTC_CSM_LEAK_EXT_SHORT" 16520948 "DTC_CSM_LEAK_MID_PACK_SHORT" 16520949 "DTC_CSM_LEAK_ERROR" 16520950 "DTC_CSM_LEAK_UNKNOWN" 16523008 "DTC_CSM_VER_MISMATCH" 16523009 "DTC_CSM_DTC_SET" 16523010 "DTC_CSM_CAL_FAULT" 16560128 "DTC_IBAT_MISMATCH" 16576512 "DTC_DIS_MAX_I2T" 16576513 "DTC_CHG_MAX_I2T" 16576768 "DTC_DIS_WARNING_I2T" 16576769 "DTC_CHG_WARNING_I2T" 11296784 "DTC_SAEJ1772_PROX_DECT_OOR_HI" 11296785 "DTC_SAEJ1772_PROX_DECT_OOR_LO" 11296800 "DTC_SAEJ1772_PILOT_PWM_OOR_HI" 11296801 "DTC_SAEJ1772_PILOT_PWM_OOR_LO" 11296802 "DTC_SAEJ1772_PILOT_PWM_DIG_COMM" 11296803 "DTC_SAEJ1772_PILOT_PWM_IR_ERR" 16175360 "DTC_FGD1_NO_SENSOR" 16175361 "DTC_FGD1_OOR_HI" 16175362 "DTC_FGD1_OOR_LO" 16175363 "DTC_FGD1_FAULT" 16175616 "DTC_FGD2_NO_SENSOR" 16175617 "DTC_FGD2_OOR_HI" 16175618 "DTC_FGD2_OOR_LO" 16175619 "DTC_FGD2_FAULT" 16171008 "DTC_CONT_OPEN" 16171009 "DTC_CONT_CLOSE" 16171010 "DTC_CONT_OPEN_CURRENT" 16171264 "DTC_CONT_CLOSE_ON_RESET" 16171265 "DTC_CONT_CLOSE_SIG_FAILED" 16171520 "DTC_PRECHARGE_TIMEOUT" 16171777 "DTC_CONT_MPOS_WELD_AT_SU" 16171778 "DTC_CONT_MNEG_WELD_AT_SU" 16171780 "DTC_CONT_CPOS_WELD_AT_SU" 16171781 "DTC_CONT_CNEG_WELD_AT_SU" 16171782 "DTC_CONT_ANEG_WELD_AT_SU" 16171783 "DTC_CONT_APOS_WELD_AT_SU" 16172033 "DTC_CONT_MPOS_WELD_AT_SD" 16172034 "DTC_CONT_MNEG_WELD_AT_SD" 16172036 "DTC_CONT_CPOS_WELD_AT_SD" 16172037 "DTC_CONT_CNEG_WELD_AT_SD" 16172038 "DTC_CONT_ANEG_WELD_AT_SD" 16172039 "DTC_CONT_APOS_WELD_AT_SD" 16172289 "DTC_CONT_MPOS_OPEN" 16172290 "DTC_CONT_MNEG_OPEN" 16172291 "DTC_CONT_MPRE_OPEN" 16172292 "DTC_CONT_CPOS_OPEN" 16172293 "DTC_CONT_CNEG_OPEN" 16172294 "DTC_CONT_APOS_OPEN" 16172295 "DTC_CONT_ANEG_OPEN" 16172545 "DTC_CONT_MPOS_VDIF" 16172546 "DTC_CONT_MNEG_VDIF" 16172548 "DTC_CONT_CPOS_VDIF" 16172549 "DTC_CONT_CNEG_VDIF" 16172550 "DTC_CONT_APOS_VDIF" 16172551 "DTC_CONT_ANEG_VDIF" 16174848 "DTC_HVIL" 16174849 "DTC_LVBAT_LO" 16174850 "DTC_LVBAT_HI" 16174851 "DTC_LVBAT_ERR" 16523520 "DTC_LEMLO_OOR_HI" 16523521 "DTC_LEMLO_OOR_LO" 16523522 "DTC_LEMLO_FAULT" 16523776 "DTC_LEMHI_OOR_HI" 16523777 "DTC_LEMHI_OOR_LO" 16523778 "DTC_LEMHI_FAULT" 16496320 "DTC_MBB_TOO_FEW" 16496321 "DTC_MBB_TOO_MANY" 16496352 "DTC_CELL_VMAX_ERR" 16496353 "DTC_CELL_VMIN_ERR" 16496354 "DTC_CELL_VMAX" 16496362 "DTC_CELL_VMAX_SEVERE" 16496355 "DTC_CELL_VMIN" 16496363 "DTC_CELL_VMIN_SEVERE" 16496356 "DTC_MOD_VOLTAGE_COMPARE" 16496336 "DTC_CELL_T_ERR" 16496337 "DTC_CELL_TMAX1" 16496338 "DTC_CELL_TMAX2" 16496339 "DTC_CELL_TMIN" 16497665 "DTC_MBB_01_MISSING" 16497666 "DTC_MBB_02_MISSING" 16497667 "DTC_MBB_03_MISSING" 16497668 "DTC_MBB_04_MISSING" 16497669 "DTC_MBB_05_MISSING" 16497670 "DTC_MBB_06_MISSING" 16497671 "DTC_MBB_07_MISSING" 16497672 "DTC_MBB_08_MISSING" 16497673 "DTC_MBB_09_MISSING" 16497680 "DTC_MBB_10_MISSING" 16497681 "DTC_MBB_11_MISSING" 16497682 "DTC_MBB_12_MISSING" 16497683 "DTC_MBB_13_MISSING" 16497684 "DTC_MBB_14_MISSING" 16497685 "DTC_MBB_15_MISSING" 16497686 "DTC_MBB_16_MISSING" 16497687 "DTC_MBB_17_MISSING" 16497688 "DTC_MBB_18_MISSING" 16497689 "DTC_MBB_19_MISSING" 16497696 "DTC_MBB_20_MISSING" 16497697 "DTC_MBB_21_MISSING" 16497698 "DTC_MBB_22_MISSING" 16497699 "DTC_MBB_23_MISSING" 16497700 "DTC_MBB_24_MISSING" 16498177 "DTC_MBB_01_VFAULT" 16498178 "DTC_MBB_02_VFAULT" 16498179 "DTC_MBB_03_VFAULT" 16498180 "DTC_MBB_04_VFAULT" 16498181 "DTC_MBB_05_VFAULT" 16498182 "DTC_MBB_06_VFAULT" 16498183 "DTC_MBB_07_VFAULT" 16498184 "DTC_MBB_08_VFAULT" 16498185 "DTC_MBB_09_VFAULT" 16498192 "DTC_MBB_10_VFAULT" 16498193 "DTC_MBB_11_VFAULT" 16498194 "DTC_MBB_12_VFAULT" 16498195 "DTC_MBB_13_VFAULT" 16498196 "DTC_MBB_14_VFAULT" 16498197 "DTC_MBB_15_VFAULT" 16498198 "DTC_MBB_16_VFAULT" 16498199 "DTC_MBB_17_VFAULT" 16498200 "DTC_MBB_18_VFAULT" 16498201 "DTC_MBB_19_VFAULT" 16498208 "DTC_MBB_20_VFAULT" 16498209 "DTC_MBB_21_VFAULT" 16498210 "DTC_MBB_22_VFAULT" 16498211 "DTC_MBB_23_VFAULT" 16498212 "DTC_MBB_24_VFAULT" 16497921 "DTC_MBB_01_TFAULT" 16497922 "DTC_MBB_02_TFAULT" 16497923 "DTC_MBB_03_TFAULT" 16497924 "DTC_MBB_04_TFAULT" 16497925 "DTC_MBB_05_TFAULT" 16497926 "DTC_MBB_06_TFAULT" 16497927 "DTC_MBB_07_TFAULT" 16497928 "DTC_MBB_08_TFAULT" 16497929 "DTC_MBB_09_TFAULT" 16497936 "DTC_MBB_10_TFAULT" 16497937 "DTC_MBB_11_TFAULT" 16497938 "DTC_MBB_12_TFAULT" 16497939 "DTC_MBB_13_TFAULT" 16497940 "DTC_MBB_14_TFAULT" 16497941 "DTC_MBB_15_TFAULT" 16497942 "DTC_MBB_16_TFAULT" 16497943 "DTC_MBB_17_TFAULT" 16497944 "DTC_MBB_18_TFAULT" 16497945 "DTC_MBB_19_TFAULT" 16497952 "DTC_MBB_20_TFAULT" 16497953 "DTC_MBB_21_TFAULT" 16497954 "DTC_MBB_22_TFAULT" 16497955 "DTC_MBB_23_TFAULT" 16497956 "DTC_MBB_24_TFAULT" 15785984 "DTC_PRECHARGE_ENERGY" 15785985 "DTC_PRT_FAILED" 15785986 "DTC_PRT_OVERTEMP" 15785987 "DTC_PRT_PROHIBIT" 16556032 "DTC_COOLANT_TEMP_OOR_HI" 16556033 "DTC_COOLANT_TEMP_OOR_LO" 16252928 "DTC_KEY_OFF_TIME_ERROR" 16506880 "DTC_VBAT_MISMATCH" 16506881 "DTC_VBAT_VMAX" 16506882 "DTC_VBAT_VMIN" 16506883 "DTC_PACK_FUSE" 15798544 "DTC_LLS1_OOR_HI" 15798545 "DTC_LLS1_OOR_LO" 15798546 "DTC_LLS1_FAULT" 15798816 "DTC_LLS2_OOR_HI" 15798817 "DTC_LLS2_OOR_LO" 15798818 "DTC_LLS2_FAULT" 14479360 "DTC_CFL_HEARTBEAT" 14479361 "DTC_CFL_FAULT" 14479362 "DTC_CFL_FAULT_LATCH" 13635584 "DTC_CONT_A_FAILED_HI" 13635585 "DTC_CONT_A_FAILED_LO" 13635586 "DTC_CONT_B_FAILED_HI" 13635587 "DTC_CONT_B_FAILED_LO" 13635588 "DTC_CONT_C_FAILED_HI" 13635589 "DTC_CONT_C_FAILED_LO" 13635590 "DTC_CONT_D_FAILED_HI" 13635591 "DTC_CONT_D_FAILED_LO" 13635592 "DTC_CONT_E_FAILED_HI" 13635593 "DTC_CONT_E_FAILED_LO" 13635594 "DTC_CONT_F_FAILED_HI" 13635595 "DTC_CONT_F_FAILED_LO" 13635596 "DTC_CONT_G_FAILED_HI" 13635597 "DTC_CONT_G_FAILED_LO" 13635598 "DTC_LSD_A_FAILED_HI" 13635599 "DTC_LSD_A_FAILED_LO" 13635600 "DTC_LSD_B_FAILED_HI" 13635601 "DTC_LSD_B_FAILED_LO" 13635602 "DTC_LSD_C_FAILED_HI" 13635603 "DTC_LSD_C_FAILED_LO" 13635606 "DTC_CONT_PWR_FAILED_HI" 13635607 "DTC_CONT_PWR_FAILED_LO" 13635608 "DTC_LSD_PUMP_FAILED_HI" 13635609 "DTC_LSD_PUMP_FAILED_LO" 13635610 "DTC_CHG_A_ENABLE_FAILED_HI" 13635611 "DTC_CHG_A_ENABLE_FAILED_LO" 13635612 "DTC_CHG_B_ENABLE_FAILED_HI" 13635613 "DTC_CHG_B_ENABLE_FAILED_LO" 13635614 "DTC_SW14V_PWR_FAILED_HI" 13635615 "DTC_SW14V_PWR_FAILED_LO" 13635620 "DTC_HSD_A_FAILED_HI" 13635621 "DTC_HSD_A_FAILED_LO" 13635622 "DTC_HSD_B_FAILED_HI" 13635623 "DTC_HSD_B_FAILED_LO" 13692968 "DTC_CONT_HPWR_FAILED_HI" 13692969 "DTC_CONT_HPWR_FAILED_LO" 13692970 "DTC_CONT_HPWR_OOR_HI" 13692971 "DTC_CONT_HPWR_OOR_LO" 13635616 "DTC_5V_PWR_OOR_HI" 13635617 "DTC_5V_PWR_OOR_LO" 14606336 "DTC_NVM_WRITE_TO" 14606337 "DTC_NVM_READ_TO" 14614528 "DTC_SPI_DIG_POT_FAULT" ;
VAL_ 1120 bcm_dtc_008 0 " - " 11276288 "DTC_VEPO" 11276289 "DTC_HSC_MISSING" 11460608 "DTC_NVM_SOC" 11460609 "DTC_NVM_KOT" 11460610 "DTC_NVM_DTC" 11460611 "DTC_NVM_SOC_CORRECTION" 11460612 "DTC_NVM_APP_SCRATCHPAD" 11517962 "DTC_LOOPTIME_TASK_A" 11517963 "DTC_LOOPTIME_TASK_B" 11517964 "DTC_LOOPTIME_TASK_C" 11517965 "DTC_LOOPTIME_TASK_D" 11517966 "DTC_LOOPTIME_TASK_E" 11517967 "DTC_LOOPTIME_TASK_F" 11323904 "DTC_INTERLOCK_A_FAILED_LOW" 11323905 "DTC_INTERLOCK_A_FAILED_HIGH" 11324160 "DTC_INTERLOCK_B_FAILED_LOW" 11324161 "DTC_INTERLOCK_B_FAILED_HIGH" 15728640 "DTC_EPO" 16498688 "DTC_BRUSA_MISSING" 16498689 "DTC_BRUSA_IDC" 16498690 "DTC_BRUSA_REQ_VS_CMD" 16433152 "DTC_AKERWADE_MISSING" 16433153 "DTC_AKERWADE_IDC" 16433154 "DTC_AKERWADE_REQ_VS_CMD" 16564224 "DTC_CHGLEAR_MISSING" 16564225 "DTC_CHGLEAR_IDC" 16564226 "DTC_CHGLEAR_REQ_VS_CMD" 16522240 "DTC_CSM_MISSING" 16522752 "DTC_CSM_VBAT" 16522753 "DTC_CSM_VPOS" 16522754 "DTC_CSM_VNEG" 16522755 "DTC_CSM_CPOS" 16522756 "DTC_CSM_CNEG" 16522757 "DTC_CSM_APOS" 16522758 "DTC_CSM_ANEG" 16522759 "DTC_CSM_FUSE_HI" 16522760 "DTC_CSM_FUSE_LO" 16521728 "DTC_CSM_ASIC" 16521729 "DTC_CSM_AILO" 16521730 "DTC_CSM_AIHI" 16520957 "DTC_LEAKAGE_DETECT_FAULT" 16522444 "DTC_REALTIMECLOCK_FAULT" 16520945 "DTC_CSM_LEAK_FAIL_CALC" 16520946 "DTC_CSM_LEAK_FAIL_HW" 16520947 "DTC_CSM_LEAK_EXT_SHORT" 16520948 "DTC_CSM_LEAK_MID_PACK_SHORT" 16520949 "DTC_CSM_LEAK_ERROR" 16520950 "DTC_CSM_LEAK_UNKNOWN" 16523008 "DTC_CSM_VER_MISMATCH" 16523009 "DTC_CSM_DTC_SET" 16523010 "DTC_CSM_CAL_FAULT" 16560128 "DTC_IBAT_MISMATCH" 16576512 "DTC_DIS_MAX_I2T" 16576513 "DTC_CHG_MAX_I2T" 16576768 "DTC_DIS_WARNING_I2T" 16576769 "DTC_CHG_WARNING_I2T" 11296784 "DTC_SAEJ1772_PROX_DECT_OOR_HI" 11296785 "DTC_SAEJ1772_PROX_DECT_OOR_LO" 11296800 "DTC_SAEJ1772_PILOT_PWM_OOR_HI" 11296801 "DTC_SAEJ1772_PILOT_PWM_OOR_LO" 11296802 "DTC_SAEJ1772_PILOT_PWM_DIG_COMM" 11296803 "DTC_SAEJ1772_PILOT_PWM_IR_ERR" 16175360 "DTC_FGD1_NO_SENSOR" 16175361 "DTC_FGD1_OOR_HI" 16175362 "DTC_FGD1_OOR_LO" 16175363 "DTC_FGD1_FAULT" 16175616 "DTC_FGD2_NO_SENSOR" 16175617 "DTC_FGD2_OOR_HI" 16175618 "DTC_FGD2_OOR_LO" 16175619 "DTC_FGD2_FAULT" 16171008 "DTC_CONT_OPEN" 16171009 "DTC_CONT_CLOSE" 16171010 "DTC_CONT_OPEN_CURRENT" 16171264 "DTC_CONT_CLOSE_ON_RESET" 16171265 "DTC_CONT_CLOSE_SIG_FAILED" 16171520 "DTC_PRECHARGE_TIMEOUT" 16171777 "DTC_CONT_MPOS_WELD_AT_SU" 16171778 "DTC_CONT_MNEG_WELD_AT_SU" 16171780 "DTC_CONT_CPOS_WELD_AT_SU" 16171781 "DTC_CONT_CNEG_WELD_AT_SU" 16171782 "DTC_CONT_ANEG_WELD_AT_SU" 16171783 "DTC_CONT_APOS_WELD_AT_SU" 16172033 "DTC_CONT_MPOS_WELD_AT_SD" 16172034 "DTC_CONT_MNEG_WELD_AT_SD" 16172036 "DTC_CONT_CPOS_WELD_AT_SD" 16172037 "DTC_CONT_CNEG_WELD_AT_SD" 16172038 "DTC_CONT_ANEG_WELD_AT_SD" 16172039 "DTC_CONT_APOS_WELD_AT_SD" 16172289 "DTC_CONT_MPOS_OPEN" 16172290 "DTC_CONT_MNEG_OPEN" 16172291 "DTC_CONT_MPRE_OPEN" 16172292 "DTC_CONT_CPOS_OPEN" 16172293 "DTC_CONT_CNEG_OPEN" 16172294 "DTC_CONT_APOS_OPEN" 16172295 "DTC_CONT_ANEG_OPEN" 16172545 "DTC_CONT_MPOS_VDIF" 16172546 "DTC_CONT_MNEG_VDIF" 16172548 "DTC_CONT_CPOS_VDIF" 16172549 "DTC_CONT_CNEG_VDIF" 16172550 "DTC_CONT_APOS_VDIF" 16172551 "DTC_CONT_ANEG_VDIF" 16174848 "DTC_HVIL" 16174849 "DTC_LVBAT_LO" 16174850 "DTC_LVBAT_HI" 16174851 "DTC_LVBAT_ERR" 16523520 "DTC_LEMLO_OOR_HI" 16523521 "DTC_LEMLO_OOR_LO" 16523522 "DTC_LEMLO_FAULT" 16523776 "DTC_LEMHI_OOR_HI" 16523777 "DTC_LEMHI_OOR_LO" 16523778 "DTC_LEMHI_FAULT" 16496320 "DTC_MBB_TOO_FEW" 16496321 "DTC_MBB_TOO_MANY" 16496352 "DTC_CELL_VMAX_ERR" 16496353 "DTC_CELL_VMIN_ERR" 16496354 "DTC_CELL_VMAX" 16496362 "DTC_CELL_VMAX_SEVERE" 16496355 "DTC_CELL_VMIN" 16496363 "DTC_CELL_VMIN_SEVERE" 16496356 "DTC_MOD_VOLTAGE_COMPARE" 16496336 "DTC_CELL_T_ERR" 16496337 "DTC_CELL_TMAX1" 16496338 "DTC_CELL_TMAX2" 16496339 "DTC_CELL_TMIN" 16497665 "DTC_MBB_01_MISSING" 16497666 "DTC_MBB_02_MISSING" 16497667 "DTC_MBB_03_MISSING" 16497668 "DTC_MBB_04_MISSING" 16497669 "DTC_MBB_05_MISSING" 16497670 "DTC_MBB_06_MISSING" 16497671 "DTC_MBB_07_MISSING" 16497672 "DTC_MBB_08_MISSING" 16497673 "DTC_MBB_09_MISSING" 16497680 "DTC_MBB_10_MISSING" 16497681 "DTC_MBB_11_MISSING" 16497682 "DTC_MBB_12_MISSING" 16497683 "DTC_MBB_13_MISSING" 16497684 "DTC_MBB_14_MISSING" 16497685 "DTC_MBB_15_MISSING" 16497686 "DTC_MBB_16_MISSING" 16497687 "DTC_MBB_17_MISSING" 16497688 "DTC_MBB_18_MISSING" 16497689 "DTC_MBB_19_MISSING" 16497696 "DTC_MBB_20_MISSING" 16497697 "DTC_MBB_21_MISSING" 16497698 "DTC_MBB_22_MISSING" 16497699 "DTC_MBB_23_MISSING" 16497700 "DTC_MBB_24_MISSING" 16498177 "DTC_MBB_01_VFAULT" 16498178 "DTC_MBB_02_VFAULT" 16498179 "DTC_MBB_03_VFAULT" 16498180 "DTC_MBB_04_VFAULT" 16498181 "DTC_MBB_05_VFAULT" 16498182 "DTC_MBB_06_VFAULT" 16498183 "DTC_MBB_07_VFAULT" 16498184 "DTC_MBB_08_VFAULT" 16498185 "DTC_MBB_09_VFAULT" 16498192 "DTC_MBB_10_VFAULT" 16498193 "DTC_MBB_11_VFAULT" 16498194 "DTC_MBB_12_VFAULT" 16498195 "DTC_MBB_13_VFAULT" 16498196 "DTC_MBB_14_VFAULT" 16498197 "DTC_MBB_15_VFAULT" 16498198 "DTC_MBB_16_VFAULT" 16498199 "DTC_MBB_17_VFAULT" 16498200 "DTC_MBB_18_VFAULT" 16498201 "DTC_MBB_19_VFAULT" 16498208 "DTC_MBB_20_VFAULT" 16498209 "DTC_MBB_21_VFAULT" 16498210 "DTC_MBB_22_VFAULT" 16498211 "DTC_MBB_23_VFAULT" 16498212 "DTC_MBB_24_VFAULT" 16497921 "DTC_MBB_01_TFAULT" 16497922 "DTC_MBB_02_TFAULT" 16497923 "DTC_MBB_03_TFAULT" 16497924 "DTC_MBB_04_TFAULT" 16497925 "DTC_MBB_05_TFAULT" 16497926 "DTC_MBB_06_TFAULT" 16497927 "DTC_MBB_07_TFAULT" 16497928 "DTC_MBB_08_TFAULT" 16497929 "DTC_MBB_09_TFAULT" 16497936 "DTC_MBB_10_TFAULT" 16497937 "DTC_MBB_11_TFAULT" 16497938 "DTC_MBB_12_TFAULT" 16497939 "DTC_MBB_13_TFAULT" 16497940 "DTC_MBB_14_TFAULT" 16497941 "DTC_MBB_15_TFAULT" 16497942 "DTC_MBB_16_TFAULT" 16497943 "DTC_MBB_17_TFAULT" 16497944 "DTC_MBB_18_TFAULT" 16497945 "DTC_MBB_19_TFAULT" 16497952 "DTC_MBB_20_TFAULT" 16497953 "DTC_MBB_21_TFAULT" 16497954 "DTC_MBB_22_TFAULT" 16497955 "DTC_MBB_23_TFAULT" 16497956 "DTC_MBB_24_TFAULT" 15785984 "DTC_PRECHARGE_ENERGY" 15785985 "DTC_PRT_FAILED" 15785986 "DTC_PRT_OVERTEMP" 15785987 "DTC_PRT_PROHIBIT" 16556032 "DTC_COOLANT_TEMP_OOR_HI" 16556033 "DTC_COOLANT_TEMP_OOR_LO" 16252928 "DTC_KEY_OFF_TIME_ERROR" 16506880 "DTC_VBAT_MISMATCH" 16506881 "DTC_VBAT_VMAX" 16506882 "DTC_VBAT_VMIN" 16506883 "DTC_PACK_FUSE" 15798544 "DTC_LLS1_OOR_HI" 15798545 "DTC_LLS1_OOR_LO" 15798546 "DTC_LLS1_FAULT" 15798816 "DTC_LLS2_OOR_HI" 15798817 "DTC_LLS2_OOR_LO" 15798818 "DTC_LLS2_FAULT" 14479360 "DTC_CFL_HEARTBEAT" 14479361 "DTC_CFL_FAULT" 14479362 "DTC_CFL_FAULT_LATCH" 13635584 "DTC_CONT_A_FAILED_HI" 13635585 "DTC_CONT_A_FAILED_LO" 13635586 "DTC_CONT_B_FAILED_HI" 13635587 "DTC_CONT_B_FAILED_LO" 13635588 "DTC_CONT_C_FAILED_HI" 13635589 "DTC_CONT_C_FAILED_LO" 13635590 "DTC_CONT_D_FAILED_HI" 13635591 "DTC_CONT_D_FAILED_LO" 13635592 "DTC_CONT_E_FAILED_HI" 13635593 "DTC_CONT_E_FAILED_LO" 13635594 "DTC_CONT_F_FAILED_HI" 13635595 "DTC_CONT_F_FAILED_LO" 13635596 "DTC_CONT_G_FAILED_HI" 13635597 "DTC_CONT_G_FAILED_LO" 13635598 "DTC_LSD_A_FAILED_HI" 13635599 "DTC_LSD_A_FAILED_LO" 13635600 "DTC_LSD_B_FAILED_HI" 13635601 "DTC_LSD_B_FAILED_LO" 13635602 "DTC_LSD_C_FAILED_HI" 13635603 "DTC_LSD_C_FAILED_LO" 13635606 "DTC_CONT_PWR_FAILED_HI" 13635607 "DTC_CONT_PWR_FAILED_LO" 13635608 "DTC_LSD_PUMP_FAILED_HI" 13635609 "DTC_LSD_PUMP_FAILED_LO" 13635610 "DTC_CHG_A_ENABLE_FAILED_HI" 13635611 "DTC_CHG_A_ENABLE_FAILED_LO" 13635612 "DTC_CHG_B_ENABLE_FAILED_HI" 13635613 "DTC_CHG_B_ENABLE_FAILED_LO" 13635614 "DTC_SW14V_PWR_FAILED_HI" 13635615 "DTC_SW14V_PWR_FAILED_LO" 13635620 "DTC_HSD_A_FAILED_HI" 13635621 "DTC_HSD_A_FAILED_LO" 13635622 "DTC_HSD_B_FAILED_HI" 13635623 "DTC_HSD_B_FAILED_LO" 13692968 "DTC_CONT_HPWR_FAILED_HI" 13692969 "DTC_CONT_HPWR_FAILED_LO" 13692970 "DTC_CONT_HPWR_OOR_HI" 13692971 "DTC_CONT_HPWR_OOR_LO" 13635616 "DTC_5V_PWR_OOR_HI" 13635617 "DTC_5V_PWR_OOR_LO" 14606336 "DTC_NVM_WRITE_TO" 14606337 "DTC_NVM_READ_TO" 14614528 "DTC_SPI_DIG_POT_FAULT" ;
